AUTOSAR XML (schema 4-2-2)
standard types defined: UINT8, UINT16, UINT32
package /ECUSystem/CCU/CCUC/CCUCCfg
  ecu instance CCUCCfg: associated-com-i-pdu-group=[TxMPG_PTCANFDConnector_Ctrl, RxMPG_PTCANFDConnector_Ctrl], com-configuration-gw-time-base=0.005, com-configuration-rx-time-base=0.005, com-configuration-tx-time-base=0.005, sleep-mode-supported=true, wake-up-over-bus-supported=true
    can communication controller PTCANFDConnector_Ctrl: wake-up-by-controller-supported=true
    can communication connector PTCANFDConnector: comm-controller=PTCANFDConnector_Ctrl
package /ECUExtractCCU/VehicleProject
  system system: category=ECU_EXTRACT, ecu-extract-version=0.0.0;25/09/22, ECU.Cfg.Ver: 0, system-version=0.0.0;25/09/22, System.Ver: 0
    system mapping SystemMapping
      data-mappings:
        data-element=CCU_CSWC_proto.RootSwCompositionPrototype.CDU_ActiveWakeupBit.CDU_ActiveWakeupBit, system-signal=CDU_ActiveWakeupBit
        data-element=CCU_CSWC_proto.RootSwCompositionPrototype.CDU_APS_PortA_Currt{1..3}.CDU_APS_PortA_Currt{1..3}, system-signal=CDU_APS_PortA_Currt{1..3}
        data-element=CCU_CSWC_proto.RootSwCompositionPrototype.CDU_APS_PortA_U1.CDU_APS_PortA_U1, system-signal=CDU_APS_PortA_U1
        data-element=CCU_CSWC_proto.RootSwCompositionPrototype.CDU_APS_PortA_U2.CDU_APS_PortA_U2, system-signal=CDU_APS_PortA_U2
        data-element=CCU_CSWC_proto.RootSwCompositionPrototype.CDU_APS_PortB_Currt_DCDC.CDU_APS_PortB_Currt_DCDC, system-signal=CDU_APS_PortB_Currt_DCDC
        data-element=CCU_CSWC_proto.RootSwCompositionPrototype.CDU_APS_PortB_Currt_Sfty.CDU_APS_PortB_Currt_Sfty, system-signal=CDU_APS_PortB_Currt_Sfty
        data-element=CCU_CSWC_proto.RootSwCompositionPrototype.CDU_APS_PortB_U1.CDU_APS_PortB_U1, system-signal=CDU_APS_PortB_U1
        data-element=CCU_CSWC_proto.RootSwCompositionPrototype.CDU_APS_PortB_U2.CDU_APS_PortB_U2, system-signal=CDU_APS_PortB_U2
        data-element=CCU_CSWC_proto.RootSwCompositionPrototype.CDU_APS_SIGN.CDU_APS_SIGN, system-signal=CDU_APS_SIGN
        data-element=CCU_CSWC_proto.RootSwCompositionPrototype.CDU_DCDC_Checksum.CDU_DCDC_Checksum, system-signal=CDU_DCDC_Checksum
        data-element=CCU_CSWC_proto.RootSwCompositionPrototype.CDU_DCDC_Counter.CDU_DCDC_Counter, system-signal=CDU_DCDC_Counter
        data-element=CCU_CSWC_proto.RootSwCompositionPrototype.CDU_DetailedFltInfo.CDU_DetailedFltInfo, system-signal=CDU_DetailedFltInfo
        data-element=CCU_CSWC_proto.RootSwCompositionPrototype.CDU_FaultNum1.CDU_FaultNum1, system-signal=CDU_FaultNum1
        data-element=CCU_CSWC_proto.RootSwCompositionPrototype.CDU_FaultNum{10..19}.CDU_FaultNum{10..19}, system-signal=CDU_FaultNum{10..19}
        data-element=CCU_CSWC_proto.RootSwCompositionPrototype.CDU_FaultNum2.CDU_FaultNum2, system-signal=CDU_FaultNum2
        data-element=CCU_CSWC_proto.RootSwCompositionPrototype.CDU_FaultNum20.CDU_FaultNum20, system-signal=CDU_FaultNum20
        data-element=CCU_CSWC_proto.RootSwCompositionPrototype.CDU_FaultNum{3..9}.CDU_FaultNum{3..9}, system-signal=CDU_FaultNum{3..9}
        data-element=CCU_CSWC_proto.RootSwCompositionPrototype.CDU_FirstWakeupReason.CDU_FirstWakeupReason, system-signal=CDU_FirstWakeupReason
        data-element=CCU_CSWC_proto.RootSwCompositionPrototype.CDU_FrameIndex.CDU_FrameIndex, system-signal=CDU_FrameIndex
        data-element=CCU_CSWC_proto.RootSwCompositionPrototype.CDU_HwVersion.CDU_HwVersion, system-signal=CDU_HwVersion
        data-element=CCU_CSWC_proto.RootSwCompositionPrototype.CDU_KL15_Volt.CDU_KL15_Volt, system-signal=CDU_KL15_Volt
        data-element=CCU_CSWC_proto.RootSwCompositionPrototype.CDU_KL30_Volt.CDU_KL30_Volt, system-signal=CDU_KL30_Volt
        data-element=CCU_CSWC_proto.RootSwCompositionPrototype.CDU_NMReq_ACDchaChrgr.CDU_NMReq_ACDchaChrgr, system-signal=CDU_NMReq_ACDchaChrgr
        data-element=CCU_CSWC_proto.RootSwCompositionPrototype.CDU_NMReq_Diag.CDU_NMReq_Diag, system-signal=CDU_NMReq_Diag
        data-element=CCU_CSWC_proto.RootSwCompositionPrototype.CDU_NMReq_NM.CDU_NMReq_NM, system-signal=CDU_NMReq_NM
        data-element=CCU_CSWC_proto.RootSwCompositionPrototype.CDU_NMReq_Poweron.CDU_NMReq_Poweron, system-signal=CDU_NMReq_Poweron
        data-element=CCU_CSWC_proto.RootSwCompositionPrototype.CDU_OBC_1_Checksum.CDU_OBC_1_Checksum, system-signal=CDU_OBC_1_Checksum
        data-element=CCU_CSWC_proto.RootSwCompositionPrototype.CDU_OBC_1_Counter.CDU_OBC_1_Counter, system-signal=CDU_OBC_1_Counter
        data-element=CCU_CSWC_proto.RootSwCompositionPrototype.CDU_RepeatMessageRequestBit.CDU_RepeatMessageRequestBit, system-signal=CDU_RepeatMessageRequestBit
        data-element=CCU_CSWC_proto.RootSwCompositionPrototype.CDU_RepeatSts.CDU_RepeatSts, system-signal=CDU_RepeatSts
        data-element=CCU_CSWC_proto.RootSwCompositionPrototype.CDU_SourceNodeIdentifier.CDU_SourceNodeIdentifier, system-signal=CDU_SourceNodeIdentifier
        data-element=CCU_CSWC_proto.RootSwCompositionPrototype.CDU_SupplierCode.CDU_SupplierCode, system-signal=CDU_SupplierCode
        data-element=CCU_CSWC_proto.RootSwCompositionPrototype.CDU_SupplierNum.CDU_SupplierNum, system-signal=CDU_SupplierNum
        data-element=CCU_CSWC_proto.RootSwCompositionPrototype.CDU_SwMajorVersion.CDU_SwMajorVersion, system-signal=CDU_SwMajorVersion
        data-element=CCU_CSWC_proto.RootSwCompositionPrototype.CDU_SwMinorVersion.CDU_SwMinorVersion, system-signal=CDU_SwMinorVersion
        data-element=CCU_CSWC_proto.RootSwCompositionPrototype.CDU_SwPatchVersion.CDU_SwPatchVersion, system-signal=CDU_SwPatchVersion
        data-element=CCU_CSWC_proto.RootSwCompositionPrototype.CDU_SwVersionDay.CDU_SwVersionDay, system-signal=CDU_SwVersionDay
        data-element=CCU_CSWC_proto.RootSwCompositionPrototype.CDU_SwVersionMonth.CDU_SwVersionMonth, system-signal=CDU_SwVersionMonth
        data-element=CCU_CSWC_proto.RootSwCompositionPrototype.CDU_SwVersionYear.CDU_SwVersionYear, system-signal=CDU_SwVersionYear
        data-element=CCU_CSWC_proto.RootSwCompositionPrototype.CDU_TotalFaultNum.CDU_TotalFaultNum, system-signal=CDU_TotalFaultNum
        data-element=CCU_CSWC_proto.RootSwCompositionPrototype.DCDC_AlerSt.DCDC_AlerSt, system-signal=DCDC_AlerSt
        data-element=CCU_CSWC_proto.RootSwCompositionPrototype.DCDC_CopntTemp.DCDC_CopntTemp, system-signal=DCDC_CopntTemp
        data-element=CCU_CSWC_proto.RootSwCompositionPrototype.DCDC_DcInterLockVolt.DCDC_DcInterLockVolt, system-signal=DCDC_DcInterLockVolt
        data-element=CCU_CSWC_proto.RootSwCompositionPrototype.DCDC_DeratFlag.DCDC_DeratFlag, system-signal=DCDC_DeratFlag
        data-element=CCU_CSWC_proto.RootSwCompositionPrototype.DCDC_DeratReason1.DCDC_DeratReason1, system-signal=DCDC_DeratReason1
        data-element=CCU_CSWC_proto.RootSwCompositionPrototype.DCDC_DeratReason{10..12}.DCDC_DeratReason{10..12}, system-signal=DCDC_DeratReason{10..12}
        data-element=CCU_CSWC_proto.RootSwCompositionPrototype.DCDC_DeratReason{2..9}.DCDC_DeratReason{2..9}, system-signal=DCDC_DeratReason{2..9}
        data-element=CCU_CSWC_proto.RootSwCompositionPrototype.DCDC_EnergyConvrtDir.DCDC_EnergyConvrtDir, system-signal=DCDC_EnergyConvrtDir
        data-element=CCU_CSWC_proto.RootSwCompositionPrototype.DCDC_FaultLevel.DCDC_FaultLevel, system-signal=DCDC_FaultLevel
        data-element=CCU_CSWC_proto.RootSwCompositionPrototype.DCDC_FaultLightReq.DCDC_FaultLightReq, system-signal=DCDC_FaultLightReq
        data-element=CCU_CSWC_proto.RootSwCompositionPrototype.DCDC_FlowReq.DCDC_FlowReq, system-signal=DCDC_FlowReq
        data-element=CCU_CSWC_proto.RootSwCompositionPrototype.DCDC_HVIL_48VDCDC_St.DCDC_HVIL_48VDCDC_St, system-signal=DCDC_HVIL_48VDCDC_St
        data-element=CCU_CSWC_proto.RootSwCompositionPrototype.DCDC_HVIL_Batt_St.DCDC_HVIL_Batt_St, system-signal=DCDC_HVIL_Batt_St
        data-element=CCU_CSWC_proto.RootSwCompositionPrototype.DCDC_HVIL_EAS_St.DCDC_HVIL_EAS_St, system-signal=DCDC_HVIL_EAS_St
        data-element=CCU_CSWC_proto.RootSwCompositionPrototype.DCDC_HVIL_MCU_St.DCDC_HVIL_MCU_St, system-signal=DCDC_HVIL_MCU_St
        data-element=CCU_CSWC_proto.RootSwCompositionPrototype.DCDC_HVIL_PTC_St.DCDC_HVIL_PTC_St, system-signal=DCDC_HVIL_PTC_St
        data-element=CCU_CSWC_proto.RootSwCompositionPrototype.DCDC_HVIL_PTCR_St.DCDC_HVIL_PTCR_St, system-signal=DCDC_HVIL_PTCR_St
        data-element=CCU_CSWC_proto.RootSwCompositionPrototype.DCDC_InpWtrTemp.DCDC_InpWtrTemp, system-signal=DCDC_InpWtrTemp
        data-element=CCU_CSWC_proto.RootSwCompositionPrototype.DCDC_IptCurrt.DCDC_IptCurrt, system-signal=DCDC_IptCurrt
        data-element=CCU_CSWC_proto.RootSwCompositionPrototype.DCDC_IptVolt.DCDC_IptVolt, system-signal=DCDC_IptVolt
        data-element=CCU_CSWC_proto.RootSwCompositionPrototype.DCDC_LoopOut.DCDC_LoopOut, system-signal=DCDC_LoopOut
        data-element=CCU_CSWC_proto.RootSwCompositionPrototype.DCDC_LvSidePwr.DCDC_LvSidePwr, system-signal=DCDC_LvSidePwr
        data-element=CCU_CSWC_proto.RootSwCompositionPrototype.DCDC_MaxOptPwr.DCDC_MaxOptPwr, system-signal=DCDC_MaxOptPwr
        data-element=CCU_CSWC_proto.RootSwCompositionPrototype.DCDC_McuInterLockVolt.DCDC_McuInterLockVolt, system-signal=DCDC_McuInterLockVolt
        data-element=CCU_CSWC_proto.RootSwCompositionPrototype.DCDC_NoLoadCurrtFlag.DCDC_NoLoadCurrtFlag, system-signal=DCDC_NoLoadCurrtFlag
        data-element=CCU_CSWC_proto.RootSwCompositionPrototype.DCDC_OperSt.DCDC_OperSt, system-signal=DCDC_OperSt
        data-element=CCU_CSWC_proto.RootSwCompositionPrototype.DCDC_OptCurrt.DCDC_OptCurrt, system-signal=DCDC_OptCurrt
        data-element=CCU_CSWC_proto.RootSwCompositionPrototype.DCDC_OptVolt.DCDC_OptVolt, system-signal=DCDC_OptVolt
        data-element=CCU_CSWC_proto.RootSwCompositionPrototype.DCDC_Oring_APS_Temp.DCDC_Oring_APS_Temp, system-signal=DCDC_Oring_APS_Temp
        data-element=CCU_CSWC_proto.RootSwCompositionPrototype.DCDC_OutWtrTemp.DCDC_OutWtrTemp, system-signal=DCDC_OutWtrTemp
        data-element=CCU_CSWC_proto.RootSwCompositionPrototype.DCDC_OverTemp.DCDC_OverTemp, system-signal=DCDC_OverTemp
        data-element=CCU_CSWC_proto.RootSwCompositionPrototype.DCDC_PeakPwrTi.DCDC_PeakPwrTi, system-signal=DCDC_PeakPwrTi
        data-element=CCU_CSWC_proto.RootSwCompositionPrototype.DCDC_PNGSt.DCDC_PNGSt, system-signal=DCDC_PNGSt
        data-element=CCU_CSWC_proto.RootSwCompositionPrototype.DCDC_PtcInterLockVolt.DCDC_PtcInterLockVolt, system-signal=DCDC_PtcInterLockVolt
        data-element=CCU_CSWC_proto.RootSwCompositionPrototype.DCDC_SwMajorVersion.DCDC_SwMajorVersion, system-signal=DCDC_SwMajorVersion
        data-element=CCU_CSWC_proto.RootSwCompositionPrototype.DCDC_SwMinorVersion.DCDC_SwMinorVersion, system-signal=DCDC_SwMinorVersion
        data-element=CCU_CSWC_proto.RootSwCompositionPrototype.DCDC_SwPatchVersion.DCDC_SwPatchVersion, system-signal=DCDC_SwPatchVersion
        data-element=CCU_CSWC_proto.RootSwCompositionPrototype.DCDC_SwVersionDay.DCDC_SwVersionDay, system-signal=DCDC_SwVersionDay
        data-element=CCU_CSWC_proto.RootSwCompositionPrototype.DCDC_SwVersionMonth.DCDC_SwVersionMonth, system-signal=DCDC_SwVersionMonth
        data-element=CCU_CSWC_proto.RootSwCompositionPrototype.DCDC_SwVersionYear.DCDC_SwVersionYear, system-signal=DCDC_SwVersionYear
        data-element=CCU_CSWC_proto.RootSwCompositionPrototype.OBC_ACInpFrq.OBC_ACInpFrq, system-signal=OBC_ACInpFrq
        data-element=CCU_CSWC_proto.RootSwCompositionPrototype.OBC_AcIptSts.OBC_AcIptSts, system-signal=OBC_AcIptSts
        data-element=CCU_CSWC_proto.RootSwCompositionPrototype.OBC_AcIptType.OBC_AcIptType, system-signal=OBC_AcIptType
        data-element=CCU_CSWC_proto.RootSwCompositionPrototype.OBC_ACL1Currt.OBC_ACL1Currt, system-signal=OBC_ACL1Currt
        data-element=CCU_CSWC_proto.RootSwCompositionPrototype.OBC_ACL1Volt.OBC_ACL1Volt, system-signal=OBC_ACL1Volt
        data-element=CCU_CSWC_proto.RootSwCompositionPrototype.OBC_ACL2Currt.OBC_ACL2Currt, system-signal=OBC_ACL2Currt
        data-element=CCU_CSWC_proto.RootSwCompositionPrototype.OBC_ACL2Volt.OBC_ACL2Volt, system-signal=OBC_ACL2Volt
        data-element=CCU_CSWC_proto.RootSwCompositionPrototype.OBC_ACL3Currt.OBC_ACL3Currt, system-signal=OBC_ACL3Currt
        data-element=CCU_CSWC_proto.RootSwCompositionPrototype.OBC_ACL3Volt.OBC_ACL3Volt, system-signal=OBC_ACL3Volt
        data-element=CCU_CSWC_proto.RootSwCompositionPrototype.OBC_AcLineImpedance.OBC_AcLineImpedance, system-signal=OBC_AcLineImpedance
        data-element=CCU_CSWC_proto.RootSwCompositionPrototype.OBC_ACPileMaxCurrt.OBC_ACPileMaxCurrt, system-signal=OBC_ACPileMaxCurrt
        data-element=CCU_CSWC_proto.RootSwCompositionPrototype.OBC_ACPwr.OBC_ACPwr, system-signal=OBC_ACPwr
        data-element=CCU_CSWC_proto.RootSwCompositionPrototype.OBC_BusCapacity.OBC_BusCapacity, system-signal=OBC_BusCapacity
        data-element=CCU_CSWC_proto.RootSwCompositionPrototype.OBC_CCRes.OBC_CCRes, system-signal=OBC_CCRes
        data-element=CCU_CSWC_proto.RootSwCompositionPrototype.OBC_ChrgCablePermitCurrt.OBC_ChrgCablePermitCurrt, system-signal=OBC_ChrgCablePermitCurrt
        data-element=CCU_CSWC_proto.RootSwCompositionPrototype.OBC_ChrgDischrgStep.OBC_ChrgDischrgStep, system-signal=OBC_ChrgDischrgStep
        data-element=CCU_CSWC_proto.RootSwCompositionPrototype.OBC_ChrgEndNum.OBC_ChrgEndNum, system-signal=OBC_ChrgEndNum
        data-element=CCU_CSWC_proto.RootSwCompositionPrototype.OBC_ChrgGunCCSts.OBC_ChrgGunCCSts, system-signal=OBC_ChrgGunCCSts
        data-element=CCU_CSWC_proto.RootSwCompositionPrototype.OBC_ChrgOptMaxCurrt.OBC_ChrgOptMaxCurrt, system-signal=OBC_ChrgOptMaxCurrt
        data-element=CCU_CSWC_proto.RootSwCompositionPrototype.OBC_ChrgOptMaxPwr.OBC_ChrgOptMaxPwr, system-signal=OBC_ChrgOptMaxPwr
        data-element=CCU_CSWC_proto.RootSwCompositionPrototype.OBC_ChrgOptMaxVolt.OBC_ChrgOptMaxVolt, system-signal=OBC_ChrgOptMaxVolt
        data-element=CCU_CSWC_proto.RootSwCompositionPrototype.OBC_ChrgOptMinVolt.OBC_ChrgOptMinVolt, system-signal=OBC_ChrgOptMinVolt
        data-element=CCU_CSWC_proto.RootSwCompositionPrototype.OBC_CopntTemp.OBC_CopntTemp, system-signal=OBC_CopntTemp
        data-element=CCU_CSWC_proto.RootSwCompositionPrototype.OBC_CPDuty.OBC_CPDuty, system-signal=OBC_CPDuty
        data-element=CCU_CSWC_proto.RootSwCompositionPrototype.OBC_CPFreqSts.OBC_CPFreqSts, system-signal=OBC_CPFreqSts
        data-element=CCU_CSWC_proto.RootSwCompositionPrototype.OBC_CPFrq.OBC_CPFrq, system-signal=OBC_CPFrq
        data-element=CCU_CSWC_proto.RootSwCompositionPrototype.OBC_CPOutpDuty.OBC_CPOutpDuty, system-signal=OBC_CPOutpDuty
        data-element=CCU_CSWC_proto.RootSwCompositionPrototype.OBC_CPOutpVolt.OBC_CPOutpVolt, system-signal=OBC_CPOutpVolt
        data-element=CCU_CSWC_proto.RootSwCompositionPrototype.OBC_CPSts.OBC_CPSts, system-signal=OBC_CPSts
        data-element=CCU_CSWC_proto.RootSwCompositionPrototype.OBC_CPValidSt.OBC_CPValidSt, system-signal=OBC_CPValidSt
        data-element=CCU_CSWC_proto.RootSwCompositionPrototype.OBC_CPVolt.OBC_CPVolt, system-signal=OBC_CPVolt
        data-element=CCU_CSWC_proto.RootSwCompositionPrototype.OBC_DCChrgMod_LimCurrt.OBC_DCChrgMod_LimCurrt, system-signal=OBC_DCChrgMod_LimCurrt
        data-element=CCU_CSWC_proto.RootSwCompositionPrototype.OBC_DCCurrt.OBC_DCCurrt, system-signal=OBC_DCCurrt
        data-element=CCU_CSWC_proto.RootSwCompositionPrototype.OBC_DchaEndNum.OBC_DchaEndNum, system-signal=OBC_DchaEndNum
        data-element=CCU_CSWC_proto.RootSwCompositionPrototype.OBC_DCVolt.OBC_DCVolt, system-signal=OBC_DCVolt
        data-element=CCU_CSWC_proto.RootSwCompositionPrototype.OBC_DeratFlag.OBC_DeratFlag, system-signal=OBC_DeratFlag
        data-element=CCU_CSWC_proto.RootSwCompositionPrototype.OBC_DeratReason1.OBC_DeratReason1, system-signal=OBC_DeratReason1
        data-element=CCU_CSWC_proto.RootSwCompositionPrototype.OBC_DeratReason{10..19}.OBC_DeratReason{10..19}, system-signal=OBC_DeratReason{10..19}
        data-element=CCU_CSWC_proto.RootSwCompositionPrototype.OBC_DeratReason2.OBC_DeratReason2, system-signal=OBC_DeratReason2
        data-element=CCU_CSWC_proto.RootSwCompositionPrototype.OBC_DeratReason{20..24}.OBC_DeratReason{20..24}, system-signal=OBC_DeratReason{20..24}
        data-element=CCU_CSWC_proto.RootSwCompositionPrototype.OBC_DeratReason{3..9}.OBC_DeratReason{3..9}, system-signal=OBC_DeratReason{3..9}
        data-element=CCU_CSWC_proto.RootSwCompositionPrototype.OBC_DischrgLoadForm.OBC_DischrgLoadForm, system-signal=OBC_DischrgLoadForm
        data-element=CCU_CSWC_proto.RootSwCompositionPrototype.OBC_DischrgOptMaxPwr.OBC_DischrgOptMaxPwr, system-signal=OBC_DischrgOptMaxPwr
        data-element=CCU_CSWC_proto.RootSwCompositionPrototype.OBC_DisWorkMode.OBC_DisWorkMode, system-signal=OBC_DisWorkMode
        data-element=CCU_CSWC_proto.RootSwCompositionPrototype.OBC_EnergyConvrtDir.OBC_EnergyConvrtDir, system-signal=OBC_EnergyConvrtDir
        data-element=CCU_CSWC_proto.RootSwCompositionPrototype.OBC_FastChargeRelayNegSts.OBC_FastChargeRelayNegSts, system-signal=OBC_FastChargeRelayNegSts
        data-element=CCU_CSWC_proto.RootSwCompositionPrototype.OBC_FastChargeRelayPosSts.OBC_FastChargeRelayPosSts, system-signal=OBC_FastChargeRelayPosSts
        data-element=CCU_CSWC_proto.RootSwCompositionPrototype.OBC_FastChrgRelayNeg_Extd_U.OBC_FastChrgRelayNeg_Extd_U, system-signal=OBC_FastChrgRelayNeg_Extd_U
        data-element=CCU_CSWC_proto.RootSwCompositionPrototype.OBC_FastChrgRelayPos_Extd_U.OBC_FastChrgRelayPos_Extd_U, system-signal=OBC_FastChrgRelayPos_Extd_U
        data-element=CCU_CSWC_proto.RootSwCompositionPrototype.OBC_FaultLevel.OBC_FaultLevel, system-signal=OBC_FaultLevel
        data-element=CCU_CSWC_proto.RootSwCompositionPrototype.OBC_FaultLightReq.OBC_FaultLightReq, system-signal=OBC_FaultLightReq
        data-element=CCU_CSWC_proto.RootSwCompositionPrototype.OBC_HVIL_AC_St.OBC_HVIL_AC_St, system-signal=OBC_HVIL_AC_St
        data-element=CCU_CSWC_proto.RootSwCompositionPrototype.OBC_HVIL_DC_St.OBC_HVIL_DC_St, system-signal=OBC_HVIL_DC_St
        data-element=CCU_CSWC_proto.RootSwCompositionPrototype.OBC_InsulationR.OBC_InsulationR, system-signal=OBC_InsulationR
        data-element=CCU_CSWC_proto.RootSwCompositionPrototype.OBC_Ithd.OBC_Ithd, system-signal=OBC_Ithd
        data-element=CCU_CSWC_proto.RootSwCompositionPrototype.OBC_OperSt.OBC_OperSt, system-signal=OBC_OperSt
        data-element=CCU_CSWC_proto.RootSwCompositionPrototype.OBC_RatedPwrLevel.OBC_RatedPwrLevel, system-signal=OBC_RatedPwrLevel
        data-element=CCU_CSWC_proto.RootSwCompositionPrototype.OBC_RBCurrt.OBC_RBCurrt, system-signal=OBC_RBCurrt
        data-element=CCU_CSWC_proto.RootSwCompositionPrototype.OBC_RBMainK{1..4}Sts.OBC_RBMainK{1..4}Sts, system-signal=OBC_RBMainK{1..4}Sts
        data-element=CCU_CSWC_proto.RootSwCompositionPrototype.OBC_S1Sts.OBC_S1Sts, system-signal=OBC_S1Sts
        data-element=CCU_CSWC_proto.RootSwCompositionPrototype.OBC_S2Sts.OBC_S2Sts, system-signal=OBC_S2Sts
        data-element=CCU_CSWC_proto.RootSwCompositionPrototype.OBC_S4Sts.OBC_S4Sts, system-signal=OBC_S4Sts
        data-element=CCU_CSWC_proto.RootSwCompositionPrototype.OBC_SwMajorVersion.OBC_SwMajorVersion, system-signal=OBC_SwMajorVersion
        data-element=CCU_CSWC_proto.RootSwCompositionPrototype.OBC_SwMinorVersion.OBC_SwMinorVersion, system-signal=OBC_SwMinorVersion
        data-element=CCU_CSWC_proto.RootSwCompositionPrototype.OBC_SwPatchVersion.OBC_SwPatchVersion, system-signal=OBC_SwPatchVersion
        data-element=CCU_CSWC_proto.RootSwCompositionPrototype.OBC_SwVersionDay.OBC_SwVersionDay, system-signal=OBC_SwVersionDay
        data-element=CCU_CSWC_proto.RootSwCompositionPrototype.OBC_SwVersionMonth.OBC_SwVersionMonth, system-signal=OBC_SwVersionMonth
        data-element=CCU_CSWC_proto.RootSwCompositionPrototype.OBC_SwVersionYear.OBC_SwVersionYear, system-signal=OBC_SwVersionYear
        data-element=CCU_CSWC_proto.RootSwCompositionPrototype.OBC_Uthd.OBC_Uthd, system-signal=OBC_Uthd
        data-element=CCU_CSWC_proto.RootSwCompositionPrototype.OBC_WorkMode.OBC_WorkMode, system-signal=OBC_WorkMode
        data-element=CCU_CSWC_proto.RootSwCompositionPrototype.BMS_ActvHvOnReq.BMS_ActvHvOnReq, system-signal=BMS_ActvHvOnReq
        data-element=CCU_CSWC_proto.RootSwCompositionPrototype.BMS_BattVolt_U7.BMS_BattVolt_U7, system-signal=BMS_BattVolt_U7
        data-element=CCU_CSWC_proto.RootSwCompositionPrototype.BMS_ChargeInfo_Checksum.BMS_ChargeInfo_Checksum, system-signal=BMS_ChargeInfo_Checksum
        data-element=CCU_CSWC_proto.RootSwCompositionPrototype.BMS_ChargeInfo_Counter.BMS_ChargeInfo_Counter, system-signal=BMS_ChargeInfo_Counter
        data-element=CCU_CSWC_proto.RootSwCompositionPrototype.BMS_DCChrgConnectSt.BMS_DCChrgConnectSt, system-signal=BMS_DCChrgConnectSt
        data-element=CCU_CSWC_proto.RootSwCompositionPrototype.BMS_MainNegSt.BMS_MainNegSt, system-signal=BMS_MainNegSt
        data-element=CCU_CSWC_proto.RootSwCompositionPrototype.BMS_MainPosSt.BMS_MainPosSt, system-signal=BMS_MainPosSt
        data-element=CCU_CSWC_proto.RootSwCompositionPrototype.BMS_MainPreChrgSt.BMS_MainPreChrgSt, system-signal=BMS_MainPreChrgSt
        data-element=CCU_CSWC_proto.RootSwCompositionPrototype.BMS_Measure_Checksum.BMS_Measure_Checksum, system-signal=BMS_Measure_Checksum
        data-element=CCU_CSWC_proto.RootSwCompositionPrototype.BMS_Measure_Counter.BMS_Measure_Counter, system-signal=BMS_Measure_Counter
        data-element=CCU_CSWC_proto.RootSwCompositionPrototype.BMS_OBCCurrtReq.BMS_OBCCurrtReq, system-signal=BMS_OBCCurrtReq
        data-element=CCU_CSWC_proto.RootSwCompositionPrototype.BMS_OBCInvACVoltReq.BMS_OBCInvACVoltReq, system-signal=BMS_OBCInvACVoltReq
        data-element=CCU_CSWC_proto.RootSwCompositionPrototype.BMS_OBCInvMaxPermPwr.BMS_OBCInvMaxPermPwr, system-signal=BMS_OBCInvMaxPermPwr
        data-element=CCU_CSWC_proto.RootSwCompositionPrototype.BMS_OBCVoltReq.BMS_OBCVoltReq, system-signal=BMS_OBCVoltReq
        data-element=CCU_CSWC_proto.RootSwCompositionPrototype.BMS_OBCWorkModReq.BMS_OBCWorkModReq, system-signal=BMS_OBCWorkModReq
        data-element=CCU_CSWC_proto.RootSwCompositionPrototype.BMS_OperSt.BMS_OperSt, system-signal=BMS_OperSt
        data-element=CCU_CSWC_proto.RootSwCompositionPrototype.IPB_VehicleSpeed.IPB_VehicleSpeed, system-signal=IPB_VehicleSpeed
        data-element=CCU_CSWC_proto.RootSwCompositionPrototype.IPB_VehicleSpeedValid.IPB_VehicleSpeedValid, system-signal=IPB_VehicleSpeedValid
        data-element=CCU_CSWC_proto.RootSwCompositionPrototype.TBOX_DSTFlag.TBOX_DSTFlag, system-signal=TBOX_DSTFlag
        data-element=CCU_CSWC_proto.RootSwCompositionPrototype.TBOX_TimeDay.TBOX_TimeDay, system-signal=TBOX_TimeDay
        data-element=CCU_CSWC_proto.RootSwCompositionPrototype.TBOX_TimeFlag.TBOX_TimeFlag, system-signal=TBOX_TimeFlag
        data-element=CCU_CSWC_proto.RootSwCompositionPrototype.TBOX_TimeHour.TBOX_TimeHour, system-signal=TBOX_TimeHour
        data-element=CCU_CSWC_proto.RootSwCompositionPrototype.TBOX_TimeMinute.TBOX_TimeMinute, system-signal=TBOX_TimeMinute
        data-element=CCU_CSWC_proto.RootSwCompositionPrototype.TBOX_TimeMonth.TBOX_TimeMonth, system-signal=TBOX_TimeMonth
        data-element=CCU_CSWC_proto.RootSwCompositionPrototype.TBOX_TimeSecond.TBOX_TimeSecond, system-signal=TBOX_TimeSecond
        data-element=CCU_CSWC_proto.RootSwCompositionPrototype.TBOX_TimeYear.TBOX_TimeYear, system-signal=TBOX_TimeYear
        data-element=CCU_CSWC_proto.RootSwCompositionPrototype.TBOX_TimeZone.TBOX_TimeZone, system-signal=TBOX_TimeZone
        data-element=CCU_CSWC_proto.RootSwCompositionPrototype.TBOX_TimeZoneMinute.TBOX_TimeZoneMinute, system-signal=TBOX_TimeZoneMinute
        data-element=CCU_CSWC_proto.RootSwCompositionPrototype.TBOX_TimeZoneNum.TBOX_TimeZoneNum, system-signal=TBOX_TimeZoneNum
        data-element=CCU_CSWC_proto.RootSwCompositionPrototype.VDC_ActGearSt.VDC_ActGearSt, system-signal=VDC_ActGearSt
        data-element=CCU_CSWC_proto.RootSwCompositionPrototype.VDC_BMSDchaMaxPwr.VDC_BMSDchaMaxPwr, system-signal=VDC_BMSDchaMaxPwr
        data-element=CCU_CSWC_proto.RootSwCompositionPrototype.VDC_DCDCEnableCmd.VDC_DCDCEnableCmd, system-signal=VDC_DCDCEnableCmd
        data-element=CCU_CSWC_proto.RootSwCompositionPrototype.VDC_DCDCMaxCurrtAlld.VDC_DCDCMaxCurrtAlld, system-signal=VDC_DCDCMaxCurrtAlld
        data-element=CCU_CSWC_proto.RootSwCompositionPrototype.VDC_DCDCSetVolt.VDC_DCDCSetVolt, system-signal=VDC_DCDCSetVolt
        data-element=CCU_CSWC_proto.RootSwCompositionPrototype.VDC_HVCtrl_Checksum.VDC_HVCtrl_Checksum, system-signal=VDC_HVCtrl_Checksum
        data-element=CCU_CSWC_proto.RootSwCompositionPrototype.VDC_HVCtrl_Counter.VDC_HVCtrl_Counter, system-signal=VDC_HVCtrl_Counter
        data-element=CCU_CSWC_proto.RootSwCompositionPrototype.VDC_OBCACCurrtMaxPerm.VDC_OBCACCurrtMaxPerm, system-signal=VDC_OBCACCurrtMaxPerm
        data-element=CCU_CSWC_proto.RootSwCompositionPrototype.VDC_RBAllwdSts.VDC_RBAllwdSts, system-signal=VDC_RBAllwdSts
        data-element=CCU_CSWC_proto.RootSwCompositionPrototype.VDC_RBDCACVoltReq.VDC_RBDCACVoltReq, system-signal=VDC_RBDCACVoltReq
        data-element=CCU_CSWC_proto.RootSwCompositionPrototype.VDC_RBEnableSt.VDC_RBEnableSt, system-signal=VDC_RBEnableSt
        data-element=CCU_CSWC_proto.RootSwCompositionPrototype.VDC_RBMainK1K2Ctrl.VDC_RBMainK1K2Ctrl, system-signal=VDC_RBMainK1K2Ctrl
        data-element=CCU_CSWC_proto.RootSwCompositionPrototype.VDC_RBMainK3K4Ctrl.VDC_RBMainK3K4Ctrl, system-signal=VDC_RBMainK3K4Ctrl
        data-element=CCU_CSWC_proto.RootSwCompositionPrototype.VDC_RBOBCWorkModReq.VDC_RBOBCWorkModReq, system-signal=VDC_RBOBCWorkModReq
        data-element=CCU_CSWC_proto.RootSwCompositionPrototype.VDC_SysState_Checksum.VDC_SysState_Checksum, system-signal=VDC_SysState_Checksum
        data-element=CCU_CSWC_proto.RootSwCompositionPrototype.VDC_SysState_Counter.VDC_SysState_Counter, system-signal=VDC_SysState_Counter
        data-element=CCU_CSWC_proto.RootSwCompositionPrototype.VDC_TotalRang_VV01.VDC_TotalRang_VV01, system-signal=VDC_TotalRang_VV01
        data-element=CCU_CSWC_proto.RootSwCompositionPrototype.VDC_VehState_Checksum.VDC_VehState_Checksum, system-signal=VDC_VehState_Checksum
        data-element=CCU_CSWC_proto.RootSwCompositionPrototype.VDC_VehState_Counter.VDC_VehState_Counter, system-signal=VDC_VehState_Counter
        data-element=CCU_CSWC_proto.RootSwCompositionPrototype.VIU_CarMode.VIU_CarMode, system-signal=VIU_CarMode
        data-element=CCU_CSWC_proto.RootSwCompositionPrototype.VIU_Info_Checksum_VV01.VIU_Info_Checksum_VV01, system-signal=VIU_Info_Checksum_VV01
        data-element=CCU_CSWC_proto.RootSwCompositionPrototype.VIU_Info_Counter.VIU_Info_Counter, system-signal=VIU_Info_Counter
        data-element=CCU_CSWC_proto.RootSwCompositionPrototype.VIU_PowerMode.VIU_PowerMode, system-signal=VIU_PowerMode
        data-element=CCU_CSWC_proto.RootSwCompositionPrototype.VIU_Route_EP_Checksum.VIU_Route_EP_Checksum, system-signal=VIU_Route_EP_Checksum
        data-element=CCU_CSWC_proto.RootSwCompositionPrototype.VIU_Route_EP_Counter.VIU_Route_EP_Counter, system-signal=VIU_Route_EP_Counter
        data-element=CCU_CSWC_proto.RootSwCompositionPrototype.VIU_UsageMode.VIU_UsageMode, system-signal=VIU_UsageMode
      sw-mappings:
        swc to ecu mapping CCU: component=RootSwCompositionPrototype.CCU_CSWC_proto, ecu-instance=CCUCCfg
    root-software-compositions:
      root sw composition prototype RootSwCompositionPrototype: software-composition=RootComposition
package /VehicleTopology
  can cluster PTCANFD: baudrate=500000, protocol-name=CAN, protocol-version=CAN11, can-fd-baudrate=2000000
    can physical channel PhCnPTCANFD: comm-connectors=PTCANFDConnector
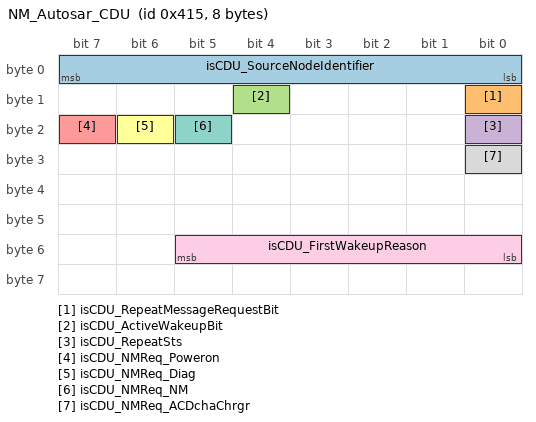
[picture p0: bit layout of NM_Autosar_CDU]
      frame NM_Autosar_CDU: id 0x415, from CCUCCfg, frame-length=8, can-addressing-mode=STANDARD, can-fd-frame-support=false, can-frame-tx-behavior=CAN-20
        nm pdu NM_Autosar_CDU: length=8, nm-vote-information=false, unused-bit-pattern=0
          signal isCDU_SourceNodeIdentifier: start 7, 8 bit, big-endian, data-type-policy=OVERRIDE, init-value=21, base-type=UINT8, compu {phys=raw for raw 0..255}, transfer-property=TRIGGERED  # 源节点ID
          signal isCDU_RepeatMessageRequestBit: start 8, 1 bit, big-endian, data-type-policy=OVERRIDE, init-value=0, base-type=UINT1, compu-method=CDU_RepeatMessageRequestBit, transfer-property=TRIGGERED  # 重复报文请求位
          signal isCDU_ActiveWakeupBit: start 12, 1 bit, big-endian, data-type-policy=OVERRIDE, init-value=0, base-type=UINT1, compu-method=CDU_ActiveWakeupBit, transfer-property=TRIGGERED  # 主动唤醒标志位
          signal isCDU_RepeatSts: start 16, 1 bit, big-endian, data-type-policy=OVERRIDE, init-value=0, base-type=UINT1, compu {0=CDU_RepeatSts_0_Not_in_the_RMS, 1=CDU_RepeatSts_1_Stay_in_the_RMS}, transfer-property=TRIGGERED  # 重复报文状态
          signal isCDU_NMReq_Poweron: start 23, 1 bit, big-endian, data-type-policy=OVERRIDE, init-value=0, base-type=UINT1, compu {0=CDU_NMReq_Poweron_0_Inactive, 1=CDU_NMReq_Poweron_1_Active}, transfer-property=TRIGGERED  # 因唤醒硬线ON请求网络
          signal isCDU_NMReq_Diag: start 22, 1 bit, big-endian, data-type-policy=OVERRIDE, init-value=0, base-type=UINT1, compu {0=CDU_NMReq_Diag_0_Inactive, 1=CDU_NMReq_Diag_1_Active}, transfer-property=TRIGGERED  # 因诊断请求网络
          signal isCDU_NMReq_NM: start 21, 1 bit, big-endian, data-type-policy=OVERRIDE, init-value=0, base-type=UINT1, compu {0=CDU_NMReq_NM_0_Inactive, 1=CDU_NMReq_NM_1_Active}, transfer-property=TRIGGERED  # 因被NM报文唤醒请求网络
          signal isCDU_NMReq_ACDchaChrgr: start 24, 1 bit, big-endian, data-type-policy=OVERRIDE, init-value=0, base-type=UINT1, compu {0=CDU_NMReq_ACDchaChrgr_0_Inactive, 1=CDU_NMReq_ACDchaChrgr_1_Active}, transfer-property=TRIGGERED  # 因交流充放电枪唤醒请求网络
          signal isCDU_FirstWakeupReason: start 53, 6 bit, big-endian, data-type-policy=OVERRIDE, init-value=0, base-type=UINT6, compu-method=CDU_FirstWakeupReason, transfer-property=TRIGGERED  # CDU首次唤醒原因
      frame CDU_Fault: id 0x51A, from CCUCCfg, frame-length=32, can-addressing-mode=STANDARD, can-fd-frame-support=true, can-frame-tx-behavior=CAN-FD
        pdu CDU_Fault: length=32, transmission-mode-condition{data-filter=data-filter-type=ALWAYS, i-signal-in-i-pdu=isCDU_TotalFaultNum_mtx}, transmission-mode-true-timing=cyclic-timing={time-offset=0.0, time-period=0.5}, unused-bit-pattern=0
          signal isCDU_FaultNum1: start 23, 12 bit, big-endian, data-type-policy=OVERRIDE, init-value=0, base-type=UINT12, compu {phys=raw for raw 0..4095}, transfer-property=PENDING  # 故障编号1
          signal isCDU_FaultNum10: start 123, 12 bit, big-endian, data-type-policy=OVERRIDE, init-value=0, base-type=UINT12, compu {phys=raw for raw 0..4095}, transfer-property=PENDING  # 故障编号10
          signal isCDU_FaultNum11: start 143, 12 bit, big-endian, data-type-policy=OVERRIDE, init-value=0, base-type=UINT12, compu {phys=raw for raw 0..4095}, transfer-property=PENDING  # 故障编号11
          signal isCDU_FaultNum12: start 147, 12 bit, big-endian, data-type-policy=OVERRIDE, init-value=0, base-type=UINT12, compu {phys=raw for raw 0..4095}, transfer-property=PENDING  # 故障编号12
          signal isCDU_FaultNum13: start 167, 12 bit, big-endian, data-type-policy=OVERRIDE, init-value=0, base-type=UINT12, compu {phys=raw for raw 0..4095}, transfer-property=PENDING  # 故障编号13
          signal isCDU_FaultNum14: start 171, 12 bit, big-endian, data-type-policy=OVERRIDE, init-value=0, base-type=UINT12, compu {phys=raw for raw 0..4095}, transfer-property=PENDING  # 故障编号14
          signal isCDU_FaultNum15: start 191, 12 bit, big-endian, data-type-policy=OVERRIDE, init-value=0, base-type=UINT12, compu {phys=raw for raw 0..4095}, transfer-property=PENDING  # 故障编号15
          signal isCDU_FaultNum16: start 195, 12 bit, big-endian, data-type-policy=OVERRIDE, init-value=0, base-type=UINT12, compu {phys=raw for raw 0..4095}, transfer-property=PENDING  # 故障编号16
          signal isCDU_FaultNum17: start 215, 12 bit, big-endian, data-type-policy=OVERRIDE, init-value=0, base-type=UINT12, compu {phys=raw for raw 0..4095}, transfer-property=PENDING  # 故障编号17
          signal isCDU_FaultNum18: start 219, 12 bit, big-endian, data-type-policy=OVERRIDE, init-value=0, base-type=UINT12, compu {phys=raw for raw 0..4095}, transfer-property=PENDING  # 故障编号18
          signal isCDU_FaultNum19: start 239, 12 bit, big-endian, data-type-policy=OVERRIDE, init-value=0, base-type=UINT12, compu {phys=raw for raw 0..4095}, transfer-property=PENDING  # 故障编号19
          signal isCDU_FaultNum2: start 27, 12 bit, big-endian, data-type-policy=OVERRIDE, init-value=0, base-type=UINT12, compu {phys=raw for raw 0..4095}, transfer-property=PENDING  # 故障编号2
          signal isCDU_FaultNum20: start 243, 12 bit, big-endian, data-type-policy=OVERRIDE, init-value=0, base-type=UINT12, compu {phys=raw for raw 0..4095}, transfer-property=PENDING  # 故障编号20
          signal isCDU_FaultNum3: start 47, 12 bit, big-endian, data-type-policy=OVERRIDE, init-value=0, base-type=UINT12, compu {phys=raw for raw 0..4095}, transfer-property=PENDING  # 故障编号3
          signal isCDU_FaultNum4: start 51, 12 bit, big-endian, data-type-policy=OVERRIDE, init-value=0, base-type=UINT12, compu {phys=raw for raw 0..4095}, transfer-property=PENDING  # 故障编号4
          signal isCDU_FaultNum5: start 71, 12 bit, big-endian, data-type-policy=OVERRIDE, init-value=0, base-type=UINT12, compu {phys=raw for raw 0..4095}, transfer-property=PENDING  # 故障编号5
          signal isCDU_FaultNum6: start 75, 12 bit, big-endian, data-type-policy=OVERRIDE, init-value=0, base-type=UINT12, compu {phys=raw for raw 0..4095}, transfer-property=PENDING  # 故障编号6
          signal isCDU_FaultNum7: start 95, 12 bit, big-endian, data-type-policy=OVERRIDE, init-value=0, base-type=UINT12, compu {phys=raw for raw 0..4095}, transfer-property=PENDING  # 故障编号7
          signal isCDU_FaultNum8: start 99, 12 bit, big-endian, data-type-policy=OVERRIDE, init-value=0, base-type=UINT12, compu {phys=raw for raw 0..4095}, transfer-property=PENDING  # 故障编号8
          signal isCDU_FaultNum9: start 119, 12 bit, big-endian, data-type-policy=OVERRIDE, init-value=0, base-type=UINT12, compu {phys=raw for raw 0..4095}, transfer-property=PENDING  # 故障编号9
          signal isCDU_FrameIndex: start 12, 5 bit, big-endian, data-type-policy=OVERRIDE, init-value=0, base-type=UINT5, compu {phys=raw for raw 0..31}, transfer-property=PENDING  # 帧序号
          signal isCDU_SupplierNum: start 15, 3 bit, big-endian, data-type-policy=OVERRIDE, init-value=0, base-type=UINT3, compu {phys=raw for raw 0..7}, transfer-property=PENDING  # 供应商代码
          signal isCDU_TotalFaultNum: start 7, 8 bit, big-endian, data-type-policy=OVERRIDE, init-value=0, base-type=UINT8, compu {phys=raw for raw 0..255}, transfer-property=PENDING  # 当前故障总数
      frame CDU_Version: id 0x5B4, from CCUCCfg, frame-length=32, can-addressing-mode=STANDARD, can-fd-frame-support=true, can-frame-tx-behavior=CAN-FD
        pdu CDU_Version: length=32, transmission-mode-condition{data-filter=data-filter-type=ALWAYS, i-signal-in-i-pdu=isCDU_SupplierCode_mtx}, transmission-mode-true-timing=cyclic-timing={time-offset=0.0, time-period=10.0}, unused-bit-pattern=0
          signal isCDU_HwVersion: start 23, 8 bit, big-endian, data-type-policy=OVERRIDE, init-value=0, base-type=UINT8, compu {phys=raw for raw 0..255}, transfer-property=PENDING  # CDU硬件版本
          signal isCDU_SupplierCode: start 7, 16 bit, big-endian, data-type-policy=OVERRIDE, init-value=0, base-type=UINT16, compu {phys=raw for raw 0..65535}, transfer-property=PENDING  # CDU供应商代码
          signal isCDU_SwMajorVersion: start 31, 8 bit, big-endian, data-type-policy=OVERRIDE, init-value=0, base-type=UINT8, compu {phys=raw for raw 0..255}, transfer-property=PENDING  # CDU软件主版本号
          signal isCDU_SwMinorVersion: start 39, 8 bit, big-endian, data-type-policy=OVERRIDE, init-value=0, base-type=UINT8, compu {phys=raw for raw 0..255}, transfer-property=PENDING  # CDU软件子版本号
          signal isCDU_SwPatchVersion: start 47, 8 bit, big-endian, data-type-policy=OVERRIDE, init-value=0, base-type=UINT8, compu {phys=raw for raw 0..255}, transfer-property=PENDING  # CDU软件补充版本号
          signal isCDU_SwVersionDay: start 71, 8 bit, big-endian, data-type-policy=OVERRIDE, init-value=0, base-type=UINT8, compu {phys=raw for raw 0..31}, transfer-property=PENDING  # CDU软件版本日
          signal isCDU_SwVersionMonth: start 63, 8 bit, big-endian, data-type-policy=OVERRIDE, init-value=0, base-type=UINT8, compu {phys=raw for raw 0..12}, transfer-property=PENDING  # CDU软件版本月
          signal isCDU_SwVersionYear: start 55, 8 bit, big-endian, data-type-policy=OVERRIDE, init-value=0, base-type=UINT8, compu {phys=raw for raw 0..255}, transfer-property=PENDING  # CDU软件版本年-2000
          signal isDCDC_SwMajorVersion: start 79, 8 bit, big-endian, data-type-policy=OVERRIDE, init-value=0, base-type=UINT8, compu {phys=raw for raw 0..255}, transfer-property=PENDING  # DCDC软件主版本号
          signal isDCDC_SwMinorVersion: start 87, 8 bit, big-endian, data-type-policy=OVERRIDE, init-value=0, base-type=UINT8, compu {phys=raw for raw 0..255}, transfer-property=PENDING  # DCDC软件子版本号
          signal isDCDC_SwPatchVersion: start 95, 8 bit, big-endian, data-type-policy=OVERRIDE, init-value=0, base-type=UINT8, compu {phys=raw for raw 0..255}, transfer-property=PENDING  # DCDC软件补充版本号
          signal isDCDC_SwVersionDay: start 119, 8 bit, big-endian, data-type-policy=OVERRIDE, init-value=0, base-type=UINT8, compu {phys=raw for raw 0..31}, transfer-property=PENDING  # DCDC软件版本日
          signal isDCDC_SwVersionMonth: start 111, 8 bit, big-endian, data-type-policy=OVERRIDE, init-value=0, base-type=UINT8, compu {phys=raw for raw 0..12}, transfer-property=PENDING  # DCDC软件版本月
          signal isDCDC_SwVersionYear: start 103, 8 bit, big-endian, data-type-policy=OVERRIDE, init-value=0, base-type=UINT8, compu {phys=raw for raw 0..255}, transfer-property=PENDING  # DCDC软件版本年-2000
          signal isOBC_SwMajorVersion: start 127, 8 bit, big-endian, data-type-policy=OVERRIDE, init-value=0, base-type=UINT8, compu {phys=raw for raw 0..255}, transfer-property=PENDING  # OBC软件主版本号
          signal isOBC_SwMinorVersion: start 135, 8 bit, big-endian, data-type-policy=OVERRIDE, init-value=0, base-type=UINT8, compu {phys=raw for raw 0..255}, transfer-property=PENDING  # OBC软件子版本号
          signal isOBC_SwPatchVersion: start 143, 8 bit, big-endian, data-type-policy=OVERRIDE, init-value=0, base-type=UINT8, compu {phys=raw for raw 0..255}, transfer-property=PENDING  # OBC软件补充版本号
          signal isOBC_SwVersionDay: start 167, 8 bit, big-endian, data-type-policy=OVERRIDE, init-value=0, base-type=UINT8, compu {phys=raw for raw 0..31}, transfer-property=PENDING  # OBC软件版本日
          signal isOBC_SwVersionMonth: start 159, 8 bit, big-endian, data-type-policy=OVERRIDE, init-value=0, base-type=UINT8, compu {phys=raw for raw 0..12}, transfer-property=PENDING  # OBC软件版本月
          signal isOBC_SwVersionYear: start 151, 8 bit, big-endian, data-type-policy=OVERRIDE, init-value=0, base-type=UINT8, compu {phys=raw for raw 0..255}, transfer-property=PENDING  # OBC软件版本年-2000
      frame CDU_OBC_2: id 0x31A, from CCUCCfg, frame-length=32, can-addressing-mode=STANDARD, can-fd-frame-support=true, can-frame-tx-behavior=CAN-FD
        pdu CDU_OBC_2: length=32, transmission-mode-condition{data-filter=data-filter-type=ALWAYS, i-signal-in-i-pdu=isOBC_DischrgOptMaxPwr_mtx}, transmission-mode-true-timing=cyclic-timing={time-offset=0.0, time-period=0.1}, unused-bit-pattern=0
          signal isCDU_KL15_Volt: start 255, 8 bit, big-endian, data-type-policy=OVERRIDE, init-value=254, base-type=UINT8, compu-method=CDU_KL15_Volt, transfer-property=PENDING  # KL15电压(仅用于问题定位)
          signal isCDU_KL30_Volt: start 247, 8 bit, big-endian, data-type-policy=OVERRIDE, init-value=254, base-type=UINT8, compu-method=CDU_KL30_Volt, transfer-property=PENDING  # KL30电压(仅用于问题定位)
          signal isOBC_ACL1Currt: start 159, 10 bit, big-endian, data-type-policy=OVERRIDE, init-value=0, base-type=UINT10, compu {phys=raw*0.1 for raw 0..1023, 1023=OBC_ACL1Currt_1023_Invalid}, transfer-property=PENDING  # OBC交流侧L1相电流
          signal isOBC_ACL1Volt: start 115, 12 bit, big-endian, data-type-policy=OVERRIDE, init-value=0, base-type=UINT12, compu {phys=raw for raw 0..4095, 4095=OBC_ACL1Volt_4095_Invalid}, transfer-property=PENDING  # OBC交流侧L1相电压
          signal isOBC_ACL2Currt: start 161, 10 bit, big-endian, data-type-policy=OVERRIDE, init-value=1022, base-type=UINT10, compu-method=OBC_ACL2Currt, transfer-property=PENDING  # OBC交流侧L2相电流
          signal isOBC_ACL2Volt: start 135, 12 bit, big-endian, data-type-policy=OVERRIDE, init-value=4094, base-type=UINT12, compu-method=OBC_ACL2Volt, transfer-property=PENDING  # OBC交流侧L2相电压
          signal isOBC_ACL3Currt: start 183, 10 bit, big-endian, data-type-policy=OVERRIDE, init-value=1022, base-type=UINT10, compu-method=OBC_ACL3Currt, transfer-property=PENDING  # OBC交流侧L3相电流
          signal isOBC_ACL3Volt: start 139, 12 bit, big-endian, data-type-policy=OVERRIDE, init-value=4094, base-type=UINT12, compu-method=OBC_ACL3Volt, transfer-property=PENDING  # OBC交流侧L3相电压
          signal isOBC_ACPileMaxCurrt: start 103, 8 bit, big-endian, data-type-policy=OVERRIDE, init-value=0, base-type=UINT8, compu {phys=raw for raw 0..255, 255=OBC_ACPileMaxCurrt_255_Invalid}, transfer-property=PENDING  # 交流充电桩允许最大电流
          signal isOBC_ACPwr: start 202, 11 bit, big-endian, data-type-policy=OVERRIDE, init-value=0, base-type=UINT11, compu {phys=raw*0.1 for raw 0..2047, 2047=OBC_ACPwr_2047_Invalid}, transfer-property=PENDING  # OBC交流侧功率
          signal isOBC_ChrgCablePermitCurrt: start 90, 3 bit, big-endian, data-type-policy=OVERRIDE, init-value=0, base-type=UINT3, compu-method=OBC_ChrgCablePermitCurrt, transfer-property=PENDING  # OBC充电线缆额定电流
          signal isOBC_ChrgEndNum: start 239, 8 bit, big-endian, data-type-policy=OVERRIDE, init-value=0, base-type=UINT8, compu {phys=raw for raw 0..255}, transfer-property=PENDING  # OBC充电结束码
          signal isOBC_ChrgOptMaxCurrt: start 111, 10 bit, big-endian, data-type-policy=OVERRIDE, init-value=0, base-type=UINT10, compu {phys=raw*0.1 for raw 0..1023, 1023=OBC_ChrgOptMaxCurrt_1023_Invalid}, transfer-property=PENDING  # OBC充电输出最大电流
          signal isOBC_ChrgOptMaxPwr: start 47, 11 bit, big-endian, data-type-policy=OVERRIDE, init-value=0, base-type=UINT11, compu {phys=raw*0.05 for raw 0..2047, 2047=OBC_ChrgOptMaxPwr_2047_Invalid}, transfer-property=PENDING  # OBC充电输出最大功率
          signal isOBC_ChrgOptMaxVolt: start 49, 10 bit, big-endian, data-type-policy=OVERRIDE, init-value=0, base-type=UINT10, compu {phys=raw for raw 0..1023, 1023=OBC_ChrgOptMaxVolt_1023_Invalid}, transfer-property=PENDING  # OBC充电输出最大电压
          signal isOBC_ChrgOptMinVolt: start 73, 10 bit, big-endian, data-type-policy=OVERRIDE, init-value=0, base-type=UINT10, compu {phys=raw for raw 0..1023, 1023=OBC_ChrgOptMinVolt_1023_Invalid}, transfer-property=PENDING  # OBC充电输出最小电压
          signal isOBC_DCChrgMod_LimCurrt: start 223, 9 bit, big-endian, data-type-policy=OVERRIDE, init-value=150, base-type=UINT9, compu {phys=raw*2 for raw 0..255, 511=OBC_DCChrgMod_LimCurrt_511_Invalid}, transfer-property=PENDING  # 直流充电模式最大限制电流(EVR)
          signal isOBC_DCCurrt: start 199, 11 bit, big-endian, data-type-policy=OVERRIDE, init-value=0, base-type=UINT11, compu {phys=raw*0.1-102.4 for raw 0..2047, 2047=OBC_DCCurrt_2047_Invalid}, transfer-property=PENDING  # OBC直流侧电流
          signal isOBC_DchaEndNum: start 230, 4 bit, big-endian, data-type-policy=OVERRIDE, init-value=0, base-type=UINT4, compu {phys=raw for raw 0..15}, transfer-property=PENDING  # OBC放电结束码
          signal isOBC_DCVolt: start 71, 12 bit, big-endian, data-type-policy=OVERRIDE, init-value=0, base-type=UINT12, compu {phys=raw for raw 0..4095, 4095=OBC_DCVolt_4095_Invalid}, transfer-property=PENDING  # OBC直流侧电压
          signal isOBC_DischrgOptMaxPwr: start 25, 10 bit, big-endian, data-type-policy=OVERRIDE, init-value=0, base-type=UINT10, compu {phys=raw*0.1 for raw 0..1023, 1023=OBC_DischrgOptMaxPwr_1023_Invalid}, transfer-property=PENDING  # OBC放电输出最大功率
      frame CDU_APS_State: id 0x58A, from CCUCCfg, frame-length=32, can-addressing-mode=STANDARD, can-fd-frame-support=true, can-frame-tx-behavior=CAN-FD
        pdu CDU_APS_State: length=32, transmission-mode-condition{data-filter=data-filter-type=ALWAYS, i-signal-in-i-pdu=isCDU_DetailedFltInfo_mtx}, transmission-mode-true-timing=cyclic-timing={time-offset=0.0, time-period=1.0}, unused-bit-pattern=0
          signal isCDU_APS_PortA_Currt1: start 109, 14 bit, big-endian, data-type-policy=OVERRIDE, init-value=16382, base-type=UINT14, compu-method=CDU_APS_PortA_Currt1, transfer-property=PENDING  # APS 端口A电流1
          signal isCDU_APS_PortA_Currt2: start 133, 14 bit, big-endian, data-type-policy=OVERRIDE, init-value=16382, base-type=UINT14, compu-method=CDU_APS_PortA_Currt2, transfer-property=PENDING  # APS 端口A电流2
          signal isCDU_APS_PortA_Currt3: start 199, 14 bit, big-endian, data-type-policy=OVERRIDE, init-value=16382, base-type=UINT14, compu-method=CDU_APS_PortA_Currt3, transfer-property=PENDING  # APS 端口A电流3
          signal isCDU_APS_PortA_U1: start 103, 10 bit, big-endian, data-type-policy=OVERRIDE, init-value=1022, base-type=UINT10, compu-method=CDU_APS_PortA_U1, transfer-property=PENDING  # APS 端口A电压1
          signal isCDU_APS_PortA_U2: start 127, 10 bit, big-endian, data-type-policy=OVERRIDE, init-value=1022, base-type=UINT10, compu-method=CDU_APS_PortA_U2, transfer-property=PENDING  # APS 端口A电压2
          signal isCDU_APS_PortB_Currt_DCDC: start 157, 14 bit, big-endian, data-type-policy=OVERRIDE, init-value=16382, base-type=UINT14, compu-method=CDU_APS_PortB_Currt_DCDC, transfer-property=PENDING  # DCDC侧计算的PortB电流
          signal isCDU_APS_PortB_Currt_Sfty: start 181, 14 bit, big-endian, data-type-policy=OVERRIDE, init-value=16382, base-type=UINT14, compu-method=CDU_APS_PortB_Currt_Sfty, transfer-property=PENDING  # 功能安全侧计算的PortB电流
          signal isCDU_APS_PortB_U1: start 151, 10 bit, big-endian, data-type-policy=OVERRIDE, init-value=1022, base-type=UINT10, compu-method=CDU_APS_PortB_U1, transfer-property=PENDING  # APS 端口B电压1
          signal isCDU_APS_PortB_U2: start 175, 10 bit, big-endian, data-type-policy=OVERRIDE, init-value=1022, base-type=UINT10, compu-method=CDU_APS_PortB_U2, transfer-property=PENDING  # APS 端口B电压2
          signal isCDU_APS_SIGN: start 201, 1 bit, big-endian, data-type-policy=OVERRIDE, init-value=0, base-type=UINT1, compu {0=CDU_APS_SIGN_0_APS, 1=CDU_APS_SIGN_1_No_APS}, transfer-property=PENDING  # APS标记
          signal isCDU_DetailedFltInfo: start 71, 32 bit, big-endian, data-type-policy=OVERRIDE, init-value=0, base-type=UINT32, compu {phys=raw for raw 0..4294967295}, transfer-property=PENDING  # CDU详细故障信息汇总
      frame CDU_DCDC: id 0x313, from CCUCCfg, frame-length=32, can-addressing-mode=STANDARD, can-fd-frame-support=true, can-frame-tx-behavior=CAN-FD
        pdu CDU_DCDC: length=32, transmission-mode-condition{data-filter=data-filter-type=ALWAYS, i-signal-in-i-pdu=isCDU_DCDC_Checksum_mtx}, transmission-mode-true-timing=cyclic-timing={time-offset=0.0, time-period=0.1}, unused-bit-pattern=0
          signal isCDU_DCDC_Checksum: start 7, 16 bit, big-endian, data-type-policy=OVERRIDE, init-value=0, base-type=UINT16, compu {phys=raw for raw 0..65535}, transfer-property=PENDING  # CRC16 checksum (DataID: 0x8313)
          signal isCDU_DCDC_Counter: start 23, 8 bit, big-endian, data-type-policy=OVERRIDE, init-value=0, base-type=UINT8, compu {phys=raw for raw 0..255}, transfer-property=PENDING  # Rolling Counter
          signal isDCDC_AlerSt: start 122, 1 bit, big-endian, data-type-policy=OVERRIDE, init-value=0, base-type=UINT1, compu {0=DCDC_AlerSt_0_No_Error, 1=DCDC_AlerSt_1_Error}, transfer-property=PENDING  # DCDC状态报警
          signal isDCDC_CopntTemp: start 191, 8 bit, big-endian, data-type-policy=OVERRIDE, init-value=0, base-type=UINT8, compu {phys=raw-48 for raw 0..254, 255=DCDC_CopntTemp_255_Invalid}, transfer-property=PENDING  # DCDC器件温度
          signal isDCDC_DeratFlag: start 113, 1 bit, big-endian, data-type-policy=OVERRIDE, init-value=0, base-type=UINT1, compu {0=DCDC_DeratFlag_0_Nomal_Working, 1=DCDC_DeratFlag_1_Derating_Working}, transfer-property=PENDING  # DCDC降额工作标志
          signal isDCDC_EnergyConvrtDir: start 87, 1 bit, big-endian, data-type-policy=OVERRIDE, init-value=0, base-type=UINT1, compu-method=DCDC_EnergyConvrtDir, transfer-property=PENDING  # DCDC能量转换方向
          signal isDCDC_FaultLevel: start 52, 3 bit, big-endian, data-type-policy=OVERRIDE, init-value=0, base-type=UINT3, compu-method=DCDC_FaultLevel, transfer-property=PENDING  # DCDC故障等级
          signal isDCDC_FaultLightReq: start 112, 1 bit, big-endian, data-type-policy=OVERRIDE, init-value=0, base-type=UINT1, compu {0=DCDC_FaultLightReq_0_No_Request, 1=DCDC_FaultLightReq_1_Request}, transfer-property=PENDING  # DCDC故障灯点亮请求
          signal isDCDC_FlowReq: start 117, 4 bit, big-endian, data-type-policy=OVERRIDE, init-value=0, base-type=UINT4, compu-method=DCDC_FlowReq, transfer-property=PENDING  # DCDC/OBC冷却液流量请求
          signal isDCDC_HVIL_48VDCDC_St: start 47, 2 bit, big-endian, data-type-policy=OVERRIDE, init-value=0, base-type=UINT2, compu-method=DCDC_HVIL_48VDCDC_St, transfer-property=PENDING  # DCDC 48VDCDC接口高压互锁状态(预留)
          signal isDCDC_HVIL_Batt_St: start 35, 2 bit, big-endian, data-type-policy=OVERRIDE, init-value=0, base-type=UINT2, compu-method=DCDC_HVIL_Batt_St, transfer-property=PENDING  # DCDC 电池接口高压互锁状态
          signal isDCDC_HVIL_EAS_St: start 41, 2 bit, big-endian, data-type-policy=OVERRIDE, init-value=0, base-type=UINT2, compu-method=DCDC_HVIL_EAS_St, transfer-property=PENDING  # DCDC 压缩机接口高压互锁状态(预留)
          signal isDCDC_HVIL_MCU_St: start 43, 2 bit, big-endian, data-type-policy=OVERRIDE, init-value=0, base-type=UINT2, compu-method=DCDC_HVIL_MCU_St, transfer-property=PENDING  # DCDC MCU接口高压互锁状态(EVR)
          signal isDCDC_HVIL_PTC_St: start 33, 2 bit, big-endian, data-type-policy=OVERRIDE, init-value=0, base-type=UINT2, compu-method=DCDC_HVIL_PTC_St, transfer-property=PENDING  # DCDC PTC接口高压互锁状态(预留)
          signal isDCDC_HVIL_PTCR_St: start 45, 2 bit, big-endian, data-type-policy=OVERRIDE, init-value=0, base-type=UINT2, compu-method=DCDC_HVIL_PTCR_St, transfer-property=PENDING  # DCDC PTCR接口高压互锁状态(预留)
          signal isDCDC_InpWtrTemp: start 103, 8 bit, big-endian, data-type-policy=OVERRIDE, init-value=0, base-type=UINT8, compu {phys=raw-48 for raw 0..255, 255=DCDC_InpWtrTemp_255_Invalid}, transfer-property=PENDING  # DCDC/OBC入水口温度
          signal isDCDC_IptCurrt: start 152, 9 bit, big-endian, data-type-policy=OVERRIDE, init-value=0, base-type=UINT9, compu {phys=raw*0.1 for raw 0..511, 511=DCDC_IptCurrt_511_Invalid}, transfer-property=PENDING  # DCDC输入电流
          signal isDCDC_IptVolt: start 85, 14 bit, big-endian, data-type-policy=OVERRIDE, init-value=0, base-type=UINT14, compu {phys=raw*0.1 for raw 0..16383, 16383=DCDC_IptVolt_16383_Invalid}, transfer-property=PENDING  # DCDC输入电压
          signal isDCDC_LvSidePwr: start 151, 10 bit, big-endian, data-type-policy=OVERRIDE, init-value=0, base-type=UINT10, compu {phys=raw*0.01 for raw 0..1023}, transfer-property=PENDING  # DCDC低压侧功率
          signal isDCDC_MaxOptPwr: start 111, 10 bit, big-endian, data-type-policy=OVERRIDE, init-value=0, base-type=UINT10, compu {phys=raw*0.01 for raw 0..1023, 1023=DCDC_MaxOptPwr_1023_Invalid}, transfer-property=PENDING  # DCDC最大输出功率
          signal isDCDC_NoLoadCurrtFlag: start 126, 3 bit, big-endian, data-type-policy=OVERRIDE, init-value=0, base-type=UINT3, compu-method=DCDC_NoLoadCurrtFlag, transfer-property=PENDING  # DCDC空载电流标志位
          signal isDCDC_OperSt: start 55, 3 bit, big-endian, data-type-policy=OVERRIDE, init-value=0, base-type=UINT3, compu-method=DCDC_OperSt, transfer-property=PENDING  # DCDC工作状态
          signal isDCDC_OptCurrt: start 31, 12 bit, big-endian, data-type-policy=OVERRIDE, init-value=0, base-type=UINT12, compu {phys=raw*0.1 for raw 0..4095, 4095=DCDC_OptCurrt_4095_Invalid}, transfer-property=PENDING  # DCDC 输出电流
          signal isDCDC_OptVolt: start 49, 10 bit, big-endian, data-type-policy=OVERRIDE, init-value=0, base-type=UINT10, compu {phys=raw*0.05 for raw 0..1023, 1023=DCDC_OptVolt_1023_Invalid}, transfer-property=PENDING  # DCDC输出电压
          signal isDCDC_OutWtrTemp: start 199, 8 bit, big-endian, data-type-policy=OVERRIDE, init-value=0, base-type=UINT8, compu-method=DCDC_OutWtrTemp, transfer-property=PENDING  # DCDC/OBC出水口温度
          signal isDCDC_OverTemp: start 123, 1 bit, big-endian, data-type-policy=OVERRIDE, init-value=0, base-type=UINT1, compu {0=DCDC_OverTemp_0_No_Error, 1=DCDC_OverTemp_1_Error}, transfer-property=PENDING  # DCDC温度报警
          signal isDCDC_PeakPwrTi: start 175, 12 bit, big-endian, data-type-policy=OVERRIDE, init-value=0, base-type=UINT12, compu {phys=raw for raw 0..3600, 4095=DCDC_PeakPwrTi_4095_Invalid}, transfer-property=PENDING  # DCDC峰值功率时间
          signal isDCDC_PNGSt: start 121, 2 bit, big-endian, data-type-policy=OVERRIDE, init-value=1, base-type=UINT2, compu-method=DCDC_PNGSt, transfer-property=PENDING  # PNG开关状态
          signal isDCDC_DeratReason1: start 200, 1 bit, big-endian, data-type-policy=OVERRIDE, init-value=0, base-type=UINT1, compu {0=DCDC_DeratReason1_0_Normal, 1=DCDC_DeratReason1_1_Abnormal}, transfer-property=PENDING  # DCDC输入低压或高压降额
          signal isDCDC_DeratReason10: start 213, 1 bit, big-endian, data-type-policy=OVERRIDE, init-value=0, base-type=UINT1, compu {0=DCDC_DeratReason10_0_Normal, 1=DCDC_DeratReason10_1_Abnormal}, transfer-property=PENDING  # DCDC降额工作原因10
          signal isDCDC_DeratReason11: start 214, 1 bit, big-endian, data-type-policy=OVERRIDE, init-value=0, base-type=UINT1, compu {0=DCDC_DeratReason11_0_Normal, 1=DCDC_DeratReason11_1_Abnormal}, transfer-property=PENDING  # DCDC降额工作原因11
          signal isDCDC_DeratReason12: start 215, 1 bit, big-endian, data-type-policy=OVERRIDE, init-value=0, base-type=UINT1, compu {0=DCDC_DeratReason12_0_Normal, 1=DCDC_DeratReason12_1_Abnormal}, transfer-property=PENDING  # DCDC降额工作原因12
          signal isDCDC_DeratReason2: start 201, 1 bit, big-endian, data-type-policy=OVERRIDE, init-value=0, base-type=UINT1, compu {0=DCDC_DeratReason2_0_Normal, 1=DCDC_DeratReason2_1_Abnormal}, transfer-property=PENDING  # DCDC输出低压降额
          signal isDCDC_DeratReason3: start 202, 1 bit, big-endian, data-type-policy=OVERRIDE, init-value=0, base-type=UINT1, compu {0=DCDC_DeratReason3_0_Normal, 1=DCDC_DeratReason3_1_Abnormal}, transfer-property=PENDING  # DCDC冷却液高温降额
          signal isDCDC_DeratReason4: start 203, 1 bit, big-endian, data-type-policy=OVERRIDE, init-value=0, base-type=UINT1, compu {0=DCDC_DeratReason4_0_Normal, 1=DCDC_DeratReason4_1_Abnormal}, transfer-property=PENDING  # DCDC内部过温降额
          signal isDCDC_DeratReason5: start 204, 1 bit, big-endian, data-type-policy=OVERRIDE, init-value=0, base-type=UINT1, compu {0=DCDC_DeratReason5_0_Normal, 1=DCDC_DeratReason5_1_Abnormal}, transfer-property=PENDING  # DCDC降额工作原因5
          signal isDCDC_DeratReason6: start 205, 1 bit, big-endian, data-type-policy=OVERRIDE, init-value=0, base-type=UINT1, compu {0=DCDC_DeratReason6_0_Normal, 1=DCDC_DeratReason6_1_Abnormal}, transfer-property=PENDING  # DCDC降额工作原因6
          signal isDCDC_DeratReason7: start 206, 1 bit, big-endian, data-type-policy=OVERRIDE, init-value=0, base-type=UINT1, compu {0=DCDC_DeratReason7_0_Normal, 1=DCDC_DeratReason7_1_Abnormal}, transfer-property=PENDING  # DCDC降额工作原因7
          signal isDCDC_DeratReason8: start 207, 1 bit, big-endian, data-type-policy=OVERRIDE, init-value=0, base-type=UINT1, compu {0=DCDC_DeratReason8_0_Normal, 1=DCDC_DeratReason8_1_Abnormal}, transfer-property=PENDING  # DCDC降额工作原因8
          signal isDCDC_DeratReason9: start 212, 1 bit, big-endian, data-type-policy=OVERRIDE, init-value=0, base-type=UINT1, compu {0=DCDC_DeratReason9_0_Normal, 1=DCDC_DeratReason9_1_Abnormal}, transfer-property=PENDING  # DCDC降额工作原因9
          signal isDCDC_LoopOut: start 231, 10 bit, big-endian, data-type-policy=OVERRIDE, init-value=0, base-type=UINT10, compu {phys=raw*0.1 for raw 0..1023}, transfer-property=PENDING  # DCDC环路值(仅用于问题定位)
          signal isDCDC_Oring_APS_Temp: start 223, 8 bit, big-endian, data-type-policy=OVERRIDE, init-value=254, base-type=UINT8, compu-method=DCDC_Oring_APS_Temp, transfer-property=PENDING  # DCDC oring/APS管温度
      frame CDU_OBC_1: id 0x316, from CCUCCfg, frame-length=32, can-addressing-mode=STANDARD, can-fd-frame-support=true, can-frame-tx-behavior=CAN-FD
        pdu CDU_OBC_1: length=32, transmission-mode-condition{data-filter=data-filter-type=ALWAYS, i-signal-in-i-pdu=isCDU_OBC_1_Checksum_mtx}, transmission-mode-true-timing=cyclic-timing={time-offset=0.0, time-period=0.1}, unused-bit-pattern=0
          signal isCDU_OBC_1_Checksum: start 7, 16 bit, big-endian, data-type-policy=OVERRIDE, init-value=0, base-type=UINT16, compu {phys=raw for raw 0..65535}, transfer-property=PENDING  # CRC16 checksum (DataID: 0x8316)
          signal isCDU_OBC_1_Counter: start 23, 8 bit, big-endian, data-type-policy=OVERRIDE, init-value=0, base-type=UINT8, compu {phys=raw for raw 0..255}, transfer-property=PENDING  # Rolling Counter
          signal isOBC_ACInpFrq: start 166, 7 bit, big-endian, data-type-policy=OVERRIDE, init-value=0, base-type=UINT7, compu {phys=raw for raw 0..127, 127=OBC_ACInpFrq_127_Invalid}, transfer-property=PENDING  # 交流输入电压频率
          signal isOBC_AcIptSts: start 39, 2 bit, big-endian, data-type-policy=OVERRIDE, init-value=0, base-type=UINT2, compu-method=OBC_AcIptSts, transfer-property=PENDING  # OBC交流输入状态
          signal isOBC_CCRes: start 100, 13 bit, big-endian, data-type-policy=OVERRIDE, init-value=0, base-type=UINT13, compu {phys=raw for raw 0..8191}, transfer-property=PENDING  # OBCCC阻值
          signal isOBC_ChrgGunCCSts: start 50, 3 bit, big-endian, data-type-policy=OVERRIDE, init-value=0, base-type=UINT3, compu-method=OBC_ChrgGunCCSts, transfer-property=PENDING  # OBC充电枪CC状态
          signal isOBC_CopntTemp: start 119, 8 bit, big-endian, data-type-policy=OVERRIDE, init-value=0, base-type=UINT8, compu {phys=raw-48 for raw 0..254, 255=OBC_CopntTemp_255_Invalid}, transfer-property=PENDING  # OBC器件温度
          signal isOBC_CPDuty: start 95, 10 bit, big-endian, data-type-policy=OVERRIDE, init-value=0, base-type=UINT10, compu {phys=raw*0.1 for raw 0..1023, 1023=OBC_CPDuty_1023_Invalid}, transfer-property=PENDING  # OBC接收CP占空比
          signal isOBC_CPFreqSts: start 45, 1 bit, big-endian, data-type-policy=OVERRIDE, init-value=0, base-type=UINT1, compu-method=OBC_CPFreqSts, transfer-property=PENDING  # OBC接收CP频率状态
          signal isOBC_CPFrq: start 151, 12 bit, big-endian, data-type-policy=OVERRIDE, init-value=0, base-type=UINT12, compu {phys=raw for raw 0..4095, 4095=OBC_CPFrq_4095_Invalid}, transfer-property=PENDING  # CP占空比实际频率
          signal isOBC_CPOutpDuty: start 175, 10 bit, big-endian, data-type-policy=OVERRIDE, init-value=0, base-type=UINT10, compu {phys=raw*0.1 for raw 0..1023, 1023=OBC_CPOutpDuty_1023_Invalid}, transfer-property=PENDING  # OBC输出CP占空比
          signal isOBC_CPOutpVolt: start 190, 7 bit, big-endian, data-type-policy=OVERRIDE, init-value=0, base-type=UINT7, compu {phys=raw*0.1 for raw 0..127, 127=OBC_CPOutpVolt_127_Invalid}, transfer-property=PENDING  # OBC输出CP电压峰值
          signal isOBC_CPSts: start 35, 4 bit, big-endian, data-type-policy=OVERRIDE, init-value=0, base-type=UINT4, compu-method=OBC_CPSts, transfer-property=PENDING  # OBCCP信号状态
          signal isOBC_CPValidSt: start 127, 2 bit, big-endian, data-type-policy=OVERRIDE, init-value=0, base-type=UINT2, compu-method=OBC_CPValidSt, transfer-property=PENDING  # CP有效状态
          signal isOBC_CPVolt: start 86, 7 bit, big-endian, data-type-policy=OVERRIDE, init-value=0, base-type=UINT7, compu {phys=raw*0.1 for raw 0..127, 127=OBC_CPVolt_127_Invalid}, transfer-property=PENDING  # OBCCP电压峰值
          signal isOBC_DeratFlag: start 36, 1 bit, big-endian, data-type-policy=OVERRIDE, init-value=0, base-type=UINT1, compu {0=OBC_DeratFlag_0_Nomal_Working, 1=OBC_DeratFlag_1_Derating_Working}, transfer-property=PENDING  # OBC降额工作标志
          signal isOBC_DischrgLoadForm: start 41, 2 bit, big-endian, data-type-policy=OVERRIDE, init-value=0, base-type=UINT2, compu-method=OBC_DischrgLoadForm, transfer-property=PENDING  # OBC放电负载形式
          signal isOBC_FastChargeRelayNegSts: start 253, 2 bit, big-endian, data-type-policy=OVERRIDE, init-value=0, base-type=UINT2, compu-method=OBC_FastChargeRelayNegSts, transfer-property=PENDING  # 快充继电器负极状态(EVR)
          signal isOBC_FastChargeRelayPosSts: start 255, 2 bit, big-endian, data-type-policy=OVERRIDE, init-value=0, base-type=UINT2, compu-method=OBC_FastChargeRelayPosSts, transfer-property=PENDING  # 快充继电器正极状态 (EVR)
          signal isOBC_FaultLevel: start 53, 3 bit, big-endian, data-type-policy=OVERRIDE, init-value=0, base-type=UINT3, compu-method=OBC_FaultLevel, transfer-property=PENDING  # OBC故障等级
          signal isOBC_FaultLightReq: start 24, 1 bit, big-endian, data-type-policy=OVERRIDE, init-value=0, base-type=UINT1, compu {0=OBC_FaultLightReq_0_No_Request, 1=OBC_FaultLightReq_1_Request}, transfer-property=PENDING  # OBC故障灯点亮请求
          signal isOBC_HVIL_AC_St: start 55, 2 bit, big-endian, data-type-policy=OVERRIDE, init-value=0, base-type=UINT2, compu-method=OBC_HVIL_AC_St, transfer-property=PENDING  # OBC 交流充放电接口高压互锁状态
          signal isOBC_HVIL_DC_St: start 251, 2 bit, big-endian, data-type-policy=OVERRIDE, init-value=0, base-type=UINT2, compu-method=OBC_HVIL_DC_St, transfer-property=PENDING  # OBC 直流充放电接口高压互锁状态(EVR)
          signal isOBC_OperSt: start 59, 4 bit, big-endian, data-type-policy=OVERRIDE, init-value=0, base-type=UINT4, compu-method=OBC_OperSt, transfer-property=PENDING  # OBC工作状态
          signal isOBC_RatedPwrLevel: start 31, 3 bit, big-endian, data-type-policy=OVERRIDE, init-value=0, base-type=UINT3, compu-method=OBC_RatedPwrLevel, transfer-property=PENDING  # OBC额定功率等级
          signal isOBC_S2Sts: start 26, 1 bit, big-endian, data-type-policy=OVERRIDE, init-value=0, base-type=UINT1, compu {0=OBC_S2Sts_0_Open, 1=OBC_S2Sts_1_Close}, transfer-property=PENDING  # OBC S2开关状态
          signal isOBC_WorkMode: start 63, 3 bit, big-endian, data-type-policy=OVERRIDE, init-value=0, base-type=UINT3, compu-method=OBC_WorkMode, transfer-property=PENDING  # OBC工作模式
          signal isOBC_AcIptType: start 28, 1 bit, big-endian, data-type-policy=OVERRIDE, init-value=0, base-type=UINT1, compu {0=OBC_AcIptType_0_One_Phase, 1=OBC_AcIptType_1_Three_Phase}, transfer-property=PENDING  # OBC交流输入形式
          signal isOBC_ChrgDischrgStep: start 44, 3 bit, big-endian, data-type-policy=OVERRIDE, init-value=0, base-type=UINT3, compu {phys=raw for raw 0..7}, transfer-property=PENDING  # OBC充放电阶段(预留)
          signal isOBC_DeratReason1: start 192, 1 bit, big-endian, data-type-policy=OVERRIDE, init-value=0, base-type=UINT1, compu {0=OBC_DeratReason1_0_Normal, 1=OBC_DeratReason1_1_Abnormal}, transfer-property=PENDING  # PFC母线电压过低降额保护
          signal isOBC_DeratReason10: start 201, 1 bit, big-endian, data-type-policy=OVERRIDE, init-value=0, base-type=UINT1, compu {0=OBC_DeratReason10_0_Normal, 1=OBC_DeratReason10_1_Abnormal}, transfer-property=PENDING  # 充电/逆变内部过温降额
          signal isOBC_DeratReason11: start 202, 1 bit, big-endian, data-type-policy=OVERRIDE, init-value=0, base-type=UINT1, compu {0=OBC_DeratReason11_0_Normal, 1=OBC_DeratReason11_1_Abnormal}, transfer-property=PENDING  # 弱电网降额
          signal isOBC_DeratReason12: start 203, 1 bit, big-endian, data-type-policy=OVERRIDE, init-value=0, base-type=UINT1, compu {0=OBC_DeratReason12_0_Normal, 1=OBC_DeratReason12_1_Abnormal}, transfer-property=PENDING  # OBC降额工作原因12
          signal isOBC_DeratReason13: start 204, 1 bit, big-endian, data-type-policy=OVERRIDE, init-value=0, base-type=UINT1, compu {0=OBC_DeratReason13_0_Normal, 1=OBC_DeratReason13_1_Abnormal}, transfer-property=PENDING  # OBC降额工作原因13
          signal isOBC_DeratReason14: start 205, 1 bit, big-endian, data-type-policy=OVERRIDE, init-value=0, base-type=UINT1, compu {0=OBC_DeratReason14_0_Normal, 1=OBC_DeratReason14_1_Abnormal}, transfer-property=PENDING  # OBC降额工作原因14
          signal isOBC_DeratReason15: start 206, 1 bit, big-endian, data-type-policy=OVERRIDE, init-value=0, base-type=UINT1, compu {0=OBC_DeratReason15_0_Normal, 1=OBC_DeratReason15_1_Abnormal}, transfer-property=PENDING  # OBC降额工作原因15
          signal isOBC_DeratReason16: start 207, 1 bit, big-endian, data-type-policy=OVERRIDE, init-value=0, base-type=UINT1, compu {0=OBC_DeratReason16_0_Normal, 1=OBC_DeratReason16_1_Abnormal}, transfer-property=PENDING  # OBC降额工作原因16
          signal isOBC_DeratReason17: start 208, 1 bit, big-endian, data-type-policy=OVERRIDE, init-value=0, base-type=UINT1, compu {0=OBC_DeratReason17_0_Normal, 1=OBC_DeratReason17_1_Abnormal}, transfer-property=PENDING  # OBC降额工作原因17
          signal isOBC_DeratReason18: start 209, 1 bit, big-endian, data-type-policy=OVERRIDE, init-value=0, base-type=UINT1, compu {0=OBC_DeratReason18_0_Normal, 1=OBC_DeratReason18_1_Abnormal}, transfer-property=PENDING  # OBC降额工作原因18
          signal isOBC_DeratReason19: start 210, 1 bit, big-endian, data-type-policy=OVERRIDE, init-value=0, base-type=UINT1, compu {0=OBC_DeratReason19_0_Normal, 1=OBC_DeratReason19_1_Abnormal}, transfer-property=PENDING  # OBC降额工作原因19
          signal isOBC_DeratReason2: start 193, 1 bit, big-endian, data-type-policy=OVERRIDE, init-value=0, base-type=UINT1, compu {0=OBC_DeratReason2_0_Normal, 1=OBC_DeratReason2_1_Abnormal}, transfer-property=PENDING  # 充电输入低压降额
          signal isOBC_DeratReason20: start 211, 1 bit, big-endian, data-type-policy=OVERRIDE, init-value=0, base-type=UINT1, compu {0=OBC_DeratReason20_0_Normal, 1=OBC_DeratReason20_1_Abnormal}, transfer-property=PENDING  # OBC降额工作原因20
          signal isOBC_DeratReason21: start 212, 1 bit, big-endian, data-type-policy=OVERRIDE, init-value=0, base-type=UINT1, compu {0=OBC_DeratReason21_0_Normal, 1=OBC_DeratReason21_1_Abnormal}, transfer-property=PENDING  # OBC降额工作原因21
          signal isOBC_DeratReason22: start 213, 1 bit, big-endian, data-type-policy=OVERRIDE, init-value=0, base-type=UINT1, compu {0=OBC_DeratReason22_0_Normal, 1=OBC_DeratReason22_1_Abnormal}, transfer-property=PENDING  # OBC降额工作原因22
          signal isOBC_DeratReason23: start 214, 1 bit, big-endian, data-type-policy=OVERRIDE, init-value=0, base-type=UINT1, compu {0=OBC_DeratReason23_0_Normal, 1=OBC_DeratReason23_1_Abnormal}, transfer-property=PENDING  # OBC降额工作原因23
          signal isOBC_DeratReason24: start 215, 1 bit, big-endian, data-type-policy=OVERRIDE, init-value=0, base-type=UINT1, compu {0=OBC_DeratReason24_0_Normal, 1=OBC_DeratReason24_1_Abnormal}, transfer-property=PENDING  # OBC降额工作原因24
          signal isOBC_DeratReason3: start 194, 1 bit, big-endian, data-type-policy=OVERRIDE, init-value=0, base-type=UINT1, compu {0=OBC_DeratReason3_0_Normal, 1=OBC_DeratReason3_1_Abnormal}, transfer-property=PENDING  # 充电输入高压降额
          signal isOBC_DeratReason4: start 195, 1 bit, big-endian, data-type-policy=OVERRIDE, init-value=0, base-type=UINT1, compu {0=OBC_DeratReason4_0_Normal, 1=OBC_DeratReason4_1_Abnormal}, transfer-property=PENDING  # 充电输出电压过低降额
          signal isOBC_DeratReason5: start 196, 1 bit, big-endian, data-type-policy=OVERRIDE, init-value=0, base-type=UINT1, compu {0=OBC_DeratReason5_0_Normal, 1=OBC_DeratReason5_1_Abnormal}, transfer-property=PENDING  # 充电输出电压过高降额
          signal isOBC_DeratReason6: start 197, 1 bit, big-endian, data-type-policy=OVERRIDE, init-value=0, base-type=UINT1, compu {0=OBC_DeratReason6_0_Normal, 1=OBC_DeratReason6_1_Abnormal}, transfer-property=PENDING  # 充电内部环温过低降额
          signal isOBC_DeratReason7: start 198, 1 bit, big-endian, data-type-policy=OVERRIDE, init-value=0, base-type=UINT1, compu {0=OBC_DeratReason7_0_Normal, 1=OBC_DeratReason7_1_Abnormal}, transfer-property=PENDING  # 充电冷却液高温降额
          signal isOBC_DeratReason8: start 199, 1 bit, big-endian, data-type-policy=OVERRIDE, init-value=0, base-type=UINT1, compu {0=OBC_DeratReason8_0_Normal, 1=OBC_DeratReason8_1_Abnormal}, transfer-property=PENDING  # 逆变冷却液高温降额
          signal isOBC_DeratReason9: start 200, 1 bit, big-endian, data-type-policy=OVERRIDE, init-value=0, base-type=UINT1, compu {0=OBC_DeratReason9_0_Normal, 1=OBC_DeratReason9_1_Abnormal}, transfer-property=PENDING  # 逆变输入低压或高压降额
          signal isOBC_DisWorkMode: start 125, 3 bit, big-endian, data-type-policy=OVERRIDE, init-value=0, base-type=UINT3, compu-method=OBC_DisWorkMode, transfer-property=PENDING  # OBC车内逆变工作模式
          signal isOBC_EnergyConvrtDir: start 47, 1 bit, big-endian, data-type-policy=OVERRIDE, init-value=0, base-type=UINT1, compu-method=OBC_EnergyConvrtDir, transfer-property=PENDING  # OBC能量转换方向
          signal isOBC_FastChrgRelayNeg_Extd_U: start 247, 8 bit, big-endian, data-type-policy=OVERRIDE, init-value=0, base-type=UINT8, compu {phys=raw*0.1 for raw 0..255}, transfer-property=PENDING  # 快充继电器负极外部采样电压(仅用于问题定位)
          signal isOBC_FastChrgRelayPos_Extd_U: start 227, 10 bit, big-endian, data-type-policy=OVERRIDE, init-value=0, base-type=UINT10, compu {phys=raw for raw 0..1023}, transfer-property=PENDING  # 快充继电器正极外部采样电压(仅用于问题定位)
          signal isOBC_InsulationR: start 223, 12 bit, big-endian, data-type-policy=OVERRIDE, init-value=0, base-type=UINT12, compu {phys=raw for raw 0..4095}, transfer-property=PENDING  # 逆变绝缘检测阻值(仅用于问题定位)
          signal isOBC_S1Sts: start 25, 1 bit, big-endian, data-type-policy=OVERRIDE, init-value=0, base-type=UINT1, compu {0=OBC_S1Sts_0_12V_Output, 1=OBC_S1Sts_1_PWM_Output}, transfer-property=PENDING  # OBC S1开关状态
          signal isOBC_S4Sts: start 27, 1 bit, big-endian, data-type-policy=OVERRIDE, init-value=0, base-type=UINT1, compu {0=OBC_S4Sts_0_Detection_status, 1=OBC_S4Sts_1_Output_status}, transfer-property=PENDING  # OBC S4开关状态
          signal isOBC_RBMainK1Sts: start 137, 2 bit, big-endian, data-type-policy=OVERRIDE, init-value=0, base-type=UINT2, compu-method=OBC_RBMainK1Sts, transfer-property=PENDING  # K1充电回路继电器状态
          signal isOBC_RBMainK2Sts: start 139, 2 bit, big-endian, data-type-policy=OVERRIDE, init-value=0, base-type=UINT2, compu-method=OBC_RBMainK2Sts, transfer-property=PENDING  # K2充电回路继电器状态
          signal isOBC_RBMainK3Sts: start 141, 2 bit, big-endian, data-type-policy=OVERRIDE, init-value=0, base-type=UINT2, compu-method=OBC_RBMainK3Sts, transfer-property=PENDING  # K3车内逆变回路继电器状态
          signal isOBC_RBMainK4Sts: start 143, 2 bit, big-endian, data-type-policy=OVERRIDE, init-value=0, base-type=UINT2, compu-method=OBC_RBMainK4Sts, transfer-property=PENDING  # K4车内逆变回路继电器状态
      frame Diag_Resp_CDU: id 0x7BD, from CCUCCfg, frame-length=64, can-addressing-mode=STANDARD, can-fd-frame-support=true, can-frame-tx-behavior=CAN-FD
        n pdu Diag_Resp_CDU: length=64
      frame CDU_OBC_3: id 0x367, from CCUCCfg, frame-length=32, can-addressing-mode=STANDARD, can-fd-frame-support=true, can-frame-tx-behavior=CAN-FD
        pdu CDU_OBC_3: length=32, transmission-mode-condition{data-filter=data-filter-type=ALWAYS, i-signal-in-i-pdu=isDCDC_PtcInterLockVolt_mtx}, transmission-mode-true-timing=cyclic-timing={time-offset=0.0, time-period=0.1}, unused-bit-pattern=0
          signal isDCDC_DcInterLockVolt: start 39, 8 bit, big-endian, data-type-policy=OVERRIDE, init-value=0, base-type=UINT8, compu {phys=raw*0.02 for raw 0..255}, transfer-property=PENDING  # DC互锁检测电压(仅用于问题定位)
          signal isDCDC_McuInterLockVolt: start 47, 8 bit, big-endian, data-type-policy=OVERRIDE, init-value=0, base-type=UINT8, compu {phys=raw*0.02 for raw 0..255}, transfer-property=PENDING  # MCU互锁检测电压(仅用于问题定位)
          signal isDCDC_PtcInterLockVolt: start 31, 8 bit, big-endian, data-type-policy=OVERRIDE, init-value=0, base-type=UINT8, compu {phys=raw*0.02 for raw 0..255}, transfer-property=PENDING  # PTC互锁检测电压(仅用于问题定位)
          signal isOBC_AcLineImpedance: start 71, 8 bit, big-endian, data-type-policy=OVERRIDE, init-value=0, base-type=UINT8, compu {phys=raw*0.02 for raw 0..255}, transfer-property=PENDING  # AC输入线路阻抗(仅用于问题定位)
          signal isOBC_BusCapacity: start 79, 8 bit, big-endian, data-type-policy=OVERRIDE, init-value=0, base-type=UINT8, compu {phys=raw*10 for raw 0..255}, transfer-property=PENDING  # 母线电容(仅用于问题定位)
          signal isOBC_Ithd: start 63, 8 bit, big-endian, data-type-policy=OVERRIDE, init-value=0, base-type=UINT8, compu {phys=raw*0.2 for raw 0..255}, transfer-property=PENDING  # 交流输入电流畸变率(仅用于问题定位)
          signal isOBC_Uthd: start 55, 8 bit, big-endian, data-type-policy=OVERRIDE, init-value=0, base-type=UINT8, compu {phys=raw*0.2 for raw 0..255}, transfer-property=PENDING  # 交流输入电压畸变率(仅用于问题定位)
          signal isOBC_RBCurrt: start 87, 10 bit, big-endian, data-type-policy=OVERRIDE, init-value=0, base-type=UINT10, compu {phys=raw*0.1 for raw 0..1023, 1023=OBC_RBCurrt_1023_Invalid}, transfer-property=PENDING  # OBC车内逆变电流
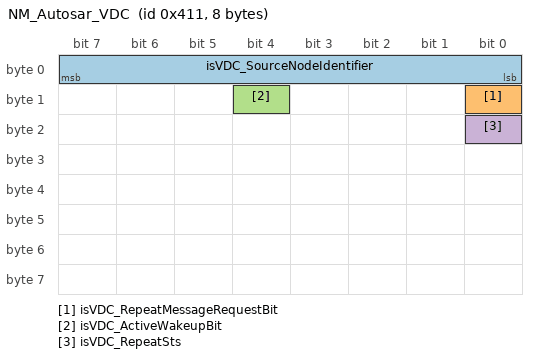
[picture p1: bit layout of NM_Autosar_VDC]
      frame NM_Autosar_VDC: id 0x411, to CCUCCfg, frame-length=8, can-addressing-mode=STANDARD, can-fd-frame-support=false, can-frame-rx-behavior=CAN-20, rx-identifier-range={lower-can-id=1024, upper-can-id=1151}
        nm pdu NM_Autosar_VDC: length=8, nm-vote-information=false, unused-bit-pattern=0
          signal isVDC_SourceNodeIdentifier: start 7, 8 bit, big-endian, data-type-policy=OVERRIDE, base-type=UINT8, compu {phys=raw for raw 0..255}  # 源节点ID
          signal isVDC_RepeatMessageRequestBit: start 8, 1 bit, big-endian, data-type-policy=OVERRIDE, base-type=UINT1, compu {0=VDC_RepeatMessageRequestBit_0_Not_Request, 1=VDC_RepeatMessageRequestBit_1_Repeat_Message_Request}  # 重复报文请求位
          signal isVDC_ActiveWakeupBit: start 12, 1 bit, big-endian, data-type-policy=OVERRIDE, base-type=UINT1, compu {0=VDC_ActiveWakeupBit_0_Passive_Wakeup, 1=VDC_ActiveWakeupBit_1_Active_Wakeup}  # 主动唤醒标志位
          signal isVDC_RepeatSts: start 16, 1 bit, big-endian, data-type-policy=OVERRIDE, base-type=UINT1, compu {0=VDC_RepeatSts_0_Not_in_the_RMS, 1=VDC_RepeatSts_1_Stay_in_the_RMS}  # 重复报文状态
      frame BMS_ChargeInfo: id 0x185, to CCUCCfg, frame-length=32, can-addressing-mode=STANDARD, can-fd-frame-support=true, can-frame-rx-behavior=CAN-FD
        pdu BMS_ChargeInfo: length=32, transmission-mode-true-timing=cyclic-timing=time-period=0.02, unused-bit-pattern=0
          signal isBMS_ChargeInfo_Checksum: start 7, 16 bit, big-endian, data-type-policy=OVERRIDE, init-value=0, base-type=UINT16, compu {phys=raw for raw 0..65535}, to CCUCCfg  # CRC16 checksum (DataID: 0x8185)
          signal isBMS_ChargeInfo_Counter: start 23, 8 bit, big-endian, data-type-policy=OVERRIDE, init-value=0, base-type=UINT8, compu {phys=raw for raw 0..255}, to CCUCCfg  # Rolling Counter
          signal isBMS_DCChrgConnectSt: start 26, 3 bit, big-endian, data-type-policy=OVERRIDE, init-value=0, base-type=UINT3, compu-method=BMS_DCChrgConnectSt, to CCUCCfg  # DC充电枪状态
          signal isBMS_OBCCurrtReq: start 155, 12 bit, big-endian, data-type-policy=OVERRIDE, init-value=4094, base-type=UINT12, compu-method=BMS_OBCCurrtReq, to CCUCCfg  # 请求OBC工作电流
          signal isBMS_OBCInvACVoltReq: start 176, 9 bit, big-endian, data-type-policy=OVERRIDE, init-value=0, base-type=UINT9, compu {phys=raw for raw 0..511, 511=BMS_OBCInvACVoltReq_511_Invalid}, to CCUCCfg  # OBC放电交流侧电压请求值
          signal isBMS_OBCInvMaxPermPwr: start 175, 10 bit, big-endian, data-type-policy=OVERRIDE, init-value=0, base-type=UINT10, compu {phys=raw*0.01 for raw 0..1023, 1023=BMS_OBCInvMaxPermPwr_1023_Invalid}, to CCUCCfg  # OBC放电功率最大允许值
          signal isBMS_OBCVoltReq: start 151, 10 bit, big-endian, data-type-policy=OVERRIDE, init-value=1022, base-type=UINT10, compu-method=BMS_OBCVoltReq, to CCUCCfg  # 请求OBC工作电压
          signal isBMS_OBCWorkModReq: start 142, 3 bit, big-endian, data-type-policy=OVERRIDE, init-value=0, base-type=UINT3, compu-method=BMS_OBCWorkModReq, to CCUCCfg  # 充电机工作模式请求
          signal isBMS_ActvHvOnReq: start 71, 8 bit, big-endian, data-type-policy=OVERRIDE, init-value=0, base-type=UINT8, compu-method=BMS_ActvHvOnReq, to CCUCCfg  # BMS主动上高压请求
      frame BMS_Measure: id 0x104, to CCUCCfg, frame-length=32, can-addressing-mode=STANDARD, can-fd-frame-support=true, can-frame-rx-behavior=CAN-FD
        pdu BMS_Measure: length=32, transmission-mode-true-timing=cyclic-timing=time-period=0.01, unused-bit-pattern=0
          signal isBMS_BattVolt_U7: start 85, 14 bit, big-endian, data-type-policy=OVERRIDE, init-value=16382, base-type=UINT14, compu-method=BMS_BattVolt_U7, to CCUCCfg  # 主正外侧电压-主负外侧电压U7(电池包后端输出电压)
          signal isBMS_Measure_Checksum: start 7, 16 bit, big-endian, data-type-policy=OVERRIDE, init-value=0, base-type=UINT16, compu {phys=raw for raw 0..65535}, to CCUCCfg  # CRC16 checksum (DataID: 0x8104)
          signal isBMS_Measure_Counter: start 23, 8 bit, big-endian, data-type-policy=OVERRIDE, init-value=0, base-type=UINT8, compu {phys=raw for raw 0..255}, to CCUCCfg  # Rolling Counter
      frame VIU_Route_EP: id 0x358, to CCUCCfg, frame-length=32, can-addressing-mode=STANDARD, can-fd-frame-support=true, can-frame-rx-behavior=CAN-FD
        pdu VIU_Route_EP: length=32, transmission-mode-true-timing={cyclic-timing=time-period=0.1, event-controlled-timing={number-of-repetitions=3, repetition-period=0.02}}, unused-bit-pattern=0
          signal isVIU_Route_EP_Checksum: start 7, 16 bit, big-endian, data-type-policy=OVERRIDE, init-value=0, base-type=UINT16, compu {phys=raw for raw 0..65535}, to CCUCCfg  # CRC16 checksum (DataID: 0x8358)
          signal isVIU_Route_EP_Counter: start 23, 8 bit, big-endian, data-type-policy=OVERRIDE, init-value=0, base-type=UINT8, compu {phys=raw for raw 0..255}, to CCUCCfg  # Rolling Counter
      frame VDC_HVCtrl: id 0x181, to CCUCCfg, frame-length=32, can-addressing-mode=STANDARD, can-fd-frame-support=true, can-frame-rx-behavior=CAN-FD
        pdu VDC_HVCtrl: length=32, transmission-mode-true-timing=cyclic-timing=time-period=0.02, unused-bit-pattern=0
          signal isVDC_BMSDchaMaxPwr: start 150, 7 bit, big-endian, data-type-policy=OVERRIDE, init-value=0, base-type=UINT7, compu {phys=raw*0.1 for raw 0..127}, to CCUCCfg  # VDC允许放电功率
          signal isVDC_DCDCEnableCmd: start 31, 3 bit, big-endian, data-type-policy=OVERRIDE, init-value=0, base-type=UINT3, compu-method=VDC_DCDCEnableCmd, to CCUCCfg  # DCDC工作使能指令
          signal isVDC_DCDCMaxCurrtAlld: start 55, 10 bit, big-endian, data-type-policy=OVERRIDE, init-value=0, base-type=UINT10, compu {phys=raw*0.5 for raw 0..1023, 1023=VDC_DCDCMaxCurrtAlld_1023_Invalid}, to CCUCCfg  # DCDC最大许用输出电流(低压侧)
          signal isVDC_DCDCSetVolt: start 39, 8 bit, big-endian, data-type-policy=OVERRIDE, init-value=0, base-type=UINT8, compu {phys=raw*0.1 for raw 0..254, 255=VDC_DCDCSetVolt_255_Invalid}, to CCUCCfg  # DCDC输出目标电压(低压侧)
          signal isVDC_HVCtrl_Checksum: start 7, 16 bit, big-endian, data-type-policy=OVERRIDE, init-value=0, base-type=UINT16, compu {phys=raw for raw 0..65535}, to CCUCCfg  # CRC16 checksum (DataID: 0x8181)
          signal isVDC_HVCtrl_Counter: start 23, 8 bit, big-endian, data-type-policy=OVERRIDE, init-value=0, base-type=UINT8, compu {phys=raw for raw 0..255}, to CCUCCfg  # Rolling Counter
          signal isVDC_OBCACCurrtMaxPerm: start 95, 7 bit, big-endian, data-type-policy=OVERRIDE, init-value=32, base-type=UINT7, compu {phys=raw for raw 0..100, 127=VDC_OBCACCurrtMaxPerm_127_Invalid}, to CCUCCfg  # OBC交流侧电流限值
      frame VDC_VehState: id 0x311, to CCUCCfg, frame-length=32, can-addressing-mode=STANDARD, can-fd-frame-support=true, can-frame-rx-behavior=CAN-FD
        pdu VDC_VehState: length=32, transmission-mode-true-timing=cyclic-timing=time-period=0.1, unused-bit-pattern=0
          signal isVDC_VehState_Checksum: start 7, 16 bit, big-endian, data-type-policy=OVERRIDE, init-value=0, base-type=UINT16, compu {phys=raw for raw 0..65535}, to CCUCCfg  # CRC16 checksum (DataID: 0x8311)
          signal isVDC_VehState_Counter: start 23, 8 bit, big-endian, data-type-policy=OVERRIDE, init-value=0, base-type=UINT8, compu {phys=raw for raw 0..255}, to CCUCCfg  # Rolling Counter
          signal isVDC_RBAllwdSts: start 122, 3 bit, big-endian, data-type-policy=OVERRIDE, init-value=0, base-type=UINT3, compu-method=VDC_RBAllwdSts, to CCUCCfg  # VDC允许车内逆变状态
          signal isVDC_RBDCACVoltReq: start 104, 9 bit, big-endian, data-type-policy=OVERRIDE, init-value=0, base-type=UINT9, compu {phys=raw for raw 0..511, 511=VDC_RBDCACVoltReq_511_Invalid}, to CCUCCfg  # 请求电压
          signal isVDC_RBEnableSt: start 110, 2 bit, big-endian, data-type-policy=OVERRIDE, init-value=0, base-type=UINT2, compu-method=VDC_RBEnableSt, to CCUCCfg  # 车内逆变硬线检测
          signal isVDC_RBMainK1K2Ctrl: start 124, 2 bit, big-endian, data-type-policy=OVERRIDE, init-value=0, base-type=UINT2, compu-method=VDC_RBMainK1K2Ctrl, to CCUCCfg  # K1K2继电器驱动指令
          signal isVDC_RBMainK3K4Ctrl: start 72, 1 bit, big-endian, data-type-policy=OVERRIDE, init-value=0, base-type=UINT1, compu {0=VDC_RBMainK3K4Ctrl_0_Open, 1=VDC_RBMainK3K4Ctrl_1_Close}, to CCUCCfg  # K3K4继电器驱动指令
          signal isVDC_RBOBCWorkModReq: start 108, 4 bit, big-endian, data-type-policy=OVERRIDE, init-value=0, base-type=UINT4, compu-method=VDC_RBOBCWorkModReq, to CCUCCfg  # 车内逆变工作模式请求
      frame VDC_SysState: id 0x184, to CCUCCfg, frame-length=32, can-addressing-mode=STANDARD, can-fd-frame-support=true, can-frame-rx-behavior=CAN-FD
        pdu VDC_SysState: length=32, transmission-mode-true-timing=cyclic-timing=time-period=0.02, unused-bit-pattern=0
          signal isVDC_ActGearSt: start 31, 4 bit, big-endian, data-type-policy=OVERRIDE, init-value=0, base-type=UINT4, compu-method=VDC_ActGearSt, to CCUCCfg  # 实际挡位
          signal isVDC_SysState_Checksum: start 7, 16 bit, big-endian, data-type-policy=OVERRIDE, init-value=0, base-type=UINT16, compu {phys=raw for raw 0..65535}, to CCUCCfg  # CRC16 checksum (DataID: 0x8184)
          signal isVDC_SysState_Counter: start 23, 8 bit, big-endian, data-type-policy=OVERRIDE, init-value=0, base-type=UINT8, compu {phys=raw for raw 0..255}, to CCUCCfg  # Rolling Counter
      frame VDC_EngyCalcu: id 0x580, to CCUCCfg, frame-length=64, can-addressing-mode=STANDARD, can-fd-frame-support=true, can-frame-rx-behavior=CAN-FD
        pdu VDC_EngyCalcu: length=64, transmission-mode-true-timing=cyclic-timing=time-period=0.5, unused-bit-pattern=0
          signal isVDC_TotalRang_VV01: start 7, 20 bit, big-endian, data-type-policy=OVERRIDE, init-value=0, base-type=UINT20, compu {phys=raw for raw 0..1048575, 1048575=VDC_TotalRang_1048575_Invalid}, to CCUCCfg
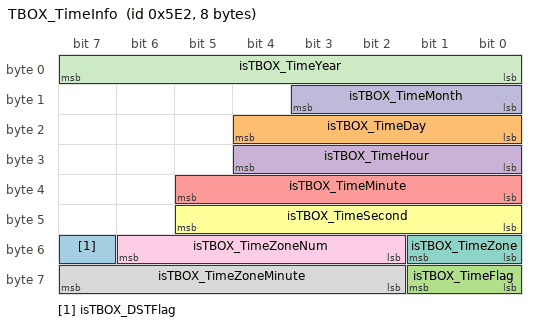
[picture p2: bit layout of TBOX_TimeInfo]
      frame TBOX_TimeInfo: id 0x5E2, to CCUCCfg, frame-length=8, can-addressing-mode=STANDARD, can-fd-frame-support=true, can-frame-rx-behavior=CAN-FD
        pdu TBOX_TimeInfo: length=8, transmission-mode-true-timing=cyclic-timing=time-period=0.5, unused-bit-pattern=0
          signal isTBOX_DSTFlag: start 55, 1 bit, big-endian, data-type-policy=OVERRIDE, init-value=0, base-type=UINT1, compu {0=TBOX_DSTFlag_0_Invalid, 1=TBOX_DSTFlag_1_Valid}, to CCUCCfg  # 夏令时标志位
          signal isTBOX_TimeDay: start 20, 5 bit, big-endian, data-type-policy=OVERRIDE, init-value=1, base-type=UINT5, compu {phys=raw for raw 1..31}, to CCUCCfg  # 本地时间_日
          signal isTBOX_TimeFlag: start 57, 2 bit, big-endian, data-type-policy=OVERRIDE, init-value=0, base-type=UINT2, compu-method=TBOX_TimeFlag, to CCUCCfg  # 时间有效性标志
          signal isTBOX_TimeHour: start 28, 5 bit, big-endian, data-type-policy=OVERRIDE, init-value=0, base-type=UINT5, compu {phys=raw for raw 0..23}, to CCUCCfg  # 本地时间_时
          signal isTBOX_TimeMinute: start 37, 6 bit, big-endian, data-type-policy=OVERRIDE, init-value=0, base-type=UINT6, compu {phys=raw for raw 0..59}, to CCUCCfg  # 本地时间_分
          signal isTBOX_TimeSecond: start 45, 6 bit, big-endian, data-type-policy=OVERRIDE, init-value=0, base-type=UINT6, compu {phys=raw for raw 0..59}, to CCUCCfg  # 本地时间_秒
          signal isTBOX_TimeZone: start 49, 2 bit, big-endian, data-type-policy=OVERRIDE, init-value=0, base-type=UINT2, compu-method=TBOX_TimeZone, to CCUCCfg  # 东/西时区
          signal isTBOX_TimeZoneMinute: start 63, 6 bit, big-endian, data-type-policy=OVERRIDE, init-value=0, base-type=UINT6, compu {phys=raw for raw 0..59}, to CCUCCfg  # 时区信息_分钟
          signal isTBOX_TimeZoneNum: start 54, 5 bit, big-endian, data-type-policy=OVERRIDE, init-value=0, base-type=UINT5, compu-method=TBOX_TimeZoneNum, to CCUCCfg  # 时区编号
          signal isTBOX_TimeMonth: start 11, 4 bit, big-endian, data-type-policy=OVERRIDE, init-value=1, base-type=UINT4, compu {phys=raw for raw 1..12}, to CCUCCfg  # 本地时间_月
          signal isTBOX_TimeYear: start 7, 8 bit, big-endian, data-type-policy=OVERRIDE, init-value=0, base-type=UINT8, compu {phys=raw+2000 for raw 0..255}, to CCUCCfg  # 本地时间_年
      frame Diag_FuncReq_PT: id 0x7DF, to CCUCCfg, frame-length=8, can-addressing-mode=STANDARD, can-fd-frame-support=true, can-frame-rx-behavior=CAN-FD
        n pdu Diag_FuncReq_PT: length=8
      frame IPB_Wheel: id 0x117, to CCUCCfg, frame-length=32, can-addressing-mode=STANDARD, can-fd-frame-support=true, can-frame-rx-behavior=CAN-FD
        pdu IPB_Wheel: length=32, transmission-mode-true-timing=cyclic-timing=time-period=0.01, unused-bit-pattern=0
          signal isIPB_VehicleSpeed: start 204, 13 bit, big-endian, data-type-policy=OVERRIDE, init-value=0, base-type=UINT13, compu {phys=raw*0.05625 for raw 0..8191, 8191=IPB_VehicleSpeed_8191_Invalid}, to CCUCCfg  # 车速
          signal isIPB_VehicleSpeedValid: start 205, 1 bit, big-endian, data-type-policy=OVERRIDE, init-value=0, base-type=UINT1, compu {0=IPB_VehicleSpeedValid_0_Invalid, 1=IPB_VehicleSpeedValid_1_Valid}, to CCUCCfg  # 车速有效位
      frame Diag_PhyReq_CDU: id 0x73D, to CCUCCfg, frame-length=64, can-addressing-mode=STANDARD, can-fd-frame-support=true, can-frame-rx-behavior=CAN-FD
        n pdu Diag_PhyReq_CDU: length=64
      frame VIU_Info_VV02: id 0x1D3, to CCUCCfg, frame-length=32, can-addressing-mode=STANDARD, can-fd-frame-support=true, can-frame-rx-behavior=CAN-FD
        pdu VIU_Info_PT: length=32, transmission-mode-true-timing=cyclic-timing=time-period=0.02, unused-bit-pattern=0
          signal isVIU_Info_Counter: start 23, 8 bit, big-endian, data-type-policy=OVERRIDE, init-value=0, base-type=UINT8, compu {phys=raw for raw 0..255}, to CCUCCfg  # RollingCounter
          signal isVIU_CarMode: start 27, 4 bit, big-endian, data-type-policy=OVERRIDE, init-value=14, base-type=UINT4, compu-method=VIU_CarMode, to CCUCCfg  # 车辆模式
          signal isVIU_UsageMode: start 31, 4 bit, big-endian, data-type-policy=OVERRIDE, init-value=1, base-type=UINT4, compu-method=VIU_UsageMode, to CCUCCfg  # 用户模式
          signal isVIU_PowerMode: start 39, 2 bit, big-endian, data-type-policy=OVERRIDE, init-value=0, base-type=UINT2, compu-method=VIU_PowerMode, to CCUCCfg  # 电源模式
          signal isVIU_Info_Checksum_VV01: start 7, 16 bit, big-endian, data-type-policy=OVERRIDE, init-value=0, base-type=UINT16, compu {phys=raw for raw 0..65535}, to CCUCCfg  # CRC16 Checksum(Data ID:0x81D3)
      frame BMS_State: id 0x107, to CCUCCfg, frame-length=32, can-addressing-mode=STANDARD, can-fd-frame-support=true, can-frame-rx-behavior=CAN-FD
        pdu BMS_State: length=32, transmission-mode-true-timing=cyclic-timing=time-period=0.01, unused-bit-pattern=0
          signal isBMS_MainNegSt: start 45, 2 bit, big-endian, data-type-policy=OVERRIDE, init-value=0, base-type=UINT2, compu-method=BMS_MainNegSt, to CCUCCfg  # 主负继电器状态
          signal isBMS_MainPosSt: start 47, 2 bit, big-endian, data-type-policy=OVERRIDE, init-value=0, base-type=UINT2, compu-method=BMS_MainPosSt, to CCUCCfg  # 主正继电器状态
          signal isBMS_MainPreChrgSt: start 43, 2 bit, big-endian, data-type-policy=OVERRIDE, init-value=0, base-type=UINT2, compu-method=BMS_MainPreChrgSt, to CCUCCfg  # 预充继电器状态
          signal isBMS_OperSt: start 59, 4 bit, big-endian, data-type-policy=OVERRIDE, init-value=0, base-type=UINT4, compu-method=BMS_OperSt, to CCUCCfg  # BMS工作状态
      pdu triggering PduTrDCM_DIAGCAN_FunReq: pdu=DCM_DIAGCAN_FunReq, to CCUCCfg
      pdu triggering PduTrDCM_DIAGCAN_PhysResp_CCU: pdu=DCM_DIAGCAN_PhysResp_CCU, from CCUCCfg
      pdu triggering PduTrDCM_DIAGCAN_PhysReq_CCU: pdu=DCM_DIAGCAN_PhysReq_CCU, to CCUCCfg
package /Communication/Pdu
  dcm i pdu DCM_DIAGCAN_FunReq: length=7, diag-pdu-type=DIAG-REQUEST
  dcm i pdu DCM_DIAGCAN_PhysResp_CCU: length=4095, diag-pdu-type=DIAG-RESPONSE
  dcm i pdu DCM_DIAGCAN_PhysReq_CCU: length=4095, diag-pdu-type=DIAG-REQUEST
package /Communication/ISignalPduGroup
  4 x i signal i pdu group:
    TxMPG_PTCANFDConnector_Ctrl: communication-direction=OUT, communication-mode=tx, contained-i-signal-i-pdu-group=TxSPG_PTCANFDConnector_Ctrl
    TxSPG_PTCANFDConnector_Ctrl: communication-direction=OUT, communication-mode=tx, i-signal-i-pdus=[CDU_OBC_3, CDU_DCDC, CDU_Version, CDU_APS_State, CDU_OBC_2, CDU_OBC_1, CDU_Fault]
    RxMPG_PTCANFDConnector_Ctrl: communication-direction=IN, communication-mode=rx, contained-i-signal-i-pdu-group=RxSPG_PTCANFDConnector_Ctrl
    RxSPG_PTCANFDConnector_Ctrl: communication-direction=IN, communication-mode=rx
      i-signal-i-pdus:
        VIU_Info_PT
        BMS_Measure
        IPB_Wheel
        VDC_SysState
        BMS_State
        BMS_ChargeInfo
        VIU_Route_EP
        VDC_VehState
        VDC_HVCtrl
        TBOX_TimeInfo
        VDC_EngyCalcu
package /Communication/NmConfig
  nm config NmConfig_PTCANFD: can-nm-cluster-coupling{coupled-cluster=CanNmPTCANFD, nm-busload-reduction-enabled=false, nm-immediate-restart-enabled=false}
    can nm cluster CanNmPTCANFD:
      communication-cluster=PTCANFD
      nm-channel-id=7
      nm-channel-sleep-master=false
      nm-synchronizing-network=false
      nm-busload-reduction-active=false
      nm-car-wake-up-filter-enabled=false
      nm-car-wake-up-rx-enabled=false
      nm-cbv-position=1
      nm-channel-active=true
      nm-immediate-nm-cycle-time=0.01
      nm-immediate-nm-transmissions=20
      nm-message-timeout-time=0.08
      nm-msg-cycle-time=0.1
      nm-network-timeout=5.0
      nm-nid-position=0
      nm-remote-sleep-indication-time=2.0
      nm-repeat-message-time=1.0
      nm-user-data-length=6
      nm-wait-bus-sleep-time=1.0
      can nm node CCU: controller=PTCANFDConnector_Ctrl, nm-if-ecu=CCU, nm-node-id=21, nm-passive-mode-enabled=false, rx-nm-pdu=NM_Autosar_VDC, tx-nm-pdu=NM_Autosar_CDU, nm-msg-cycle-offset=0.0, nm-msg-reduced-time=0.1, nm-range-config={lower-can-id=1024, upper-can-id=1151}
    nm-if-ecus:
      nm ecu CCU:
        bus-specific-nm-ecu=can-nm-ecu=nm-repeat-msg-indication-enabled=true
        ecu-instance=CCUCCfg
        nm-bus-synchronization-enabled=false
        nm-com-control-enabled=true
        nm-cycletime-main-function=0.01
        nm-node-detection-enabled=true
        nm-node-id-enabled=true
        nm-passive-mode-enabled=false
        nm-pdu-rx-indication-enabled=true
        nm-remote-sleep-ind-enabled=false
        nm-repeat-msg-ind-enabled=true
        nm-state-change-ind-enabled=true
        nm-user-data-enabled=true
package /Communication/TpConfig
  can tp config CanTpConfig_PTCANFD: communication-cluster=PTCANFD, can-tp-ecu=CCUCCfg
    9 x can tp address:
      MultiCanTpAddress: tp-address=255
      CanTpAddress_VIU: tp-address=1
      CanTpAddress_BMS: tp-address=2
      CanTpAddress_CCU: tp-address=3
      CanTpAddress_HVAC: tp-address=16
      CanTpAddress_PEU: tp-address=4
      CanTpAddress_PICU: tp-address=5
      CanTpAddress_TC: tp-address=6
      CanTpAddress_SAC: tp-address=8
    can tp channel CanTpChannel_PTCANFD: channel-id=9, channel-mode=HALF-DUPLEX-MODE
    tp-connections:
      addressing-format=STANDARD, can-tp-channel=CanTpChannel_PTCANFD, data-pdu=Diag_FuncReq_PT, max-block-size=8, multicast=MultiCanTpAddress, padding-activation=true, receiver=[BMS, CCU, HVAC, PEU, PICU, TC, SAC], ta-type=FUNCTIONAL-CAN-FD, timeout-br=0.05, timeout-bs=1.0, timeout-cr=1.0, timeout-cs=0.4, tp-sdu=DCM_DIAGCAN_FunReq, transmit-cancellation=true, transmitter=VIU
      addressing-format=STANDARD, can-tp-channel=CanTpChannel_PTCANFD, data-pdu=Diag_Resp_CDU, flow-control-pdu=Diag_PhyReq_CDU, max-block-size=8, padding-activation=true, receiver=VIU, ta-type=PHYSICAL-CAN-FD, timeout-br=0.05, timeout-bs=1.0, timeout-cr=1.0, timeout-cs=0.4, tp-sdu=DCM_DIAGCAN_PhysResp_CCU, transmit-cancellation=true, transmitter=CCU
      addressing-format=STANDARD, can-tp-channel=CanTpChannel_PTCANFD, data-pdu=Diag_PhyReq_CDU, flow-control-pdu=Diag_Resp_CDU, max-block-size=8, padding-activation=true, receiver=CCU, ta-type=PHYSICAL-CAN-FD, timeout-br=0.05, timeout-bs=1.0, timeout-cr=1.0, timeout-cs=0.4, tp-sdu=DCM_DIAGCAN_PhysReq_CCU, transmit-cancellation=true, transmitter=VIU
    8 x can tp node, all with max-fc-wait=2, timeout-ar=0.5:
      VIU: st-min=0.02, timeout-as=0.5, tp-address=CanTpAddress_VIU
      BMS: tp-address=CanTpAddress_BMS
      CCU: connector=PTCANFDConnector, st-min=0.02, timeout-as=0.5, tp-address=CanTpAddress_CCU
      HVAC: tp-address=CanTpAddress_HVAC
      PEU: tp-address=CanTpAddress_PEU
      PICU: tp-address=CanTpAddress_PICU
      TC: tp-address=CanTpAddress_TC
      SAC: tp-address=CanTpAddress_SAC
package /DataType
  data type mapping set DataTypeMappingSet
  253 x app type, all with category=VALUE:
    CDU_ActiveWakeupBit_dt: compu-method=CDU_ActiveWakeupBit
    CDU_APS_PortA_Currt{1..3}_dt: compu-method=CDU_APS_PortA_Currt{1..3}
    CDU_APS_PortA_U1_dt: compu-method=CDU_APS_PortA_U1
    CDU_APS_PortA_U2_dt: compu-method=CDU_APS_PortA_U2
    CDU_APS_PortB_Currt_DCDC_dt: compu-method=CDU_APS_PortB_Currt_DCDC
    CDU_APS_PortB_Currt_Sfty_dt: compu-method=CDU_APS_PortB_Currt_Sfty
    CDU_APS_PortB_U1_dt: compu-method=CDU_APS_PortB_U1
    CDU_APS_PortB_U2_dt: compu-method=CDU_APS_PortB_U2
    CDU_APS_SIGN_dt: compu {0=CDU_APS_SIGN_0_APS, 1=CDU_APS_SIGN_1_No_APS}
    CDU_DCDC_Checksum_dt: compu {phys=raw for raw 0..65535}
    CDU_DCDC_Counter_dt: compu {phys=raw for raw 0..255}
    CDU_DetailedFltInfo_dt: compu {phys=raw for raw 0..4294967295}
    CDU_FaultNum1_dt: compu {phys=raw for raw 0..4095}
    CDU_FaultNum{10..19}_dt: compu {phys=raw for raw 0..4095}
    CDU_FaultNum2_dt: compu {phys=raw for raw 0..4095}
    CDU_FaultNum20_dt: compu {phys=raw for raw 0..4095}
    CDU_FaultNum{3..9}_dt: compu {phys=raw for raw 0..4095}
    CDU_FirstWakeupReason_dt: compu-method=CDU_FirstWakeupReason
    CDU_FrameIndex_dt: compu {phys=raw for raw 0..31}
    CDU_HwVersion_dt: compu {phys=raw for raw 0..255}
    CDU_KL15_Volt_dt: compu-method=CDU_KL15_Volt
    CDU_KL30_Volt_dt: compu-method=CDU_KL30_Volt
    CDU_NMReq_ACDchaChrgr_dt: compu {0=CDU_NMReq_ACDchaChrgr_0_Inactive, 1=CDU_NMReq_ACDchaChrgr_1_Active}
    CDU_NMReq_Diag_dt: compu {0=CDU_NMReq_Diag_0_Inactive, 1=CDU_NMReq_Diag_1_Active}
    CDU_NMReq_NM_dt: compu {0=CDU_NMReq_NM_0_Inactive, 1=CDU_NMReq_NM_1_Active}
    CDU_NMReq_Poweron_dt: compu {0=CDU_NMReq_Poweron_0_Inactive, 1=CDU_NMReq_Poweron_1_Active}
    CDU_OBC_1_Checksum_dt: compu {phys=raw for raw 0..65535}
    CDU_OBC_1_Counter_dt: compu {phys=raw for raw 0..255}
    CDU_RepeatMessageRequestBit_dt: compu-method=CDU_RepeatMessageRequestBit
    CDU_RepeatSts_dt: compu {0=CDU_RepeatSts_0_Not_in_the_RMS, 1=CDU_RepeatSts_1_Stay_in_the_RMS}
    CDU_SourceNodeIdentifier_dt: compu {phys=raw for raw 0..255}
    CDU_SupplierCode_dt: compu {phys=raw for raw 0..65535}
    CDU_SupplierNum_dt: compu {phys=raw for raw 0..7}
    CDU_SwMajorVersion_dt: compu {phys=raw for raw 0..255}
    CDU_SwMinorVersion_dt: compu {phys=raw for raw 0..255}
    CDU_SwPatchVersion_dt: compu {phys=raw for raw 0..255}
    CDU_SwVersionDay_dt: compu {phys=raw for raw 0..31}
    CDU_SwVersionMonth_dt: compu {phys=raw for raw 0..12}
    CDU_SwVersionYear_dt: compu {phys=raw for raw 0..255}
    CDU_TotalFaultNum_dt: compu {phys=raw for raw 0..255}
    DCDC_AlerSt_dt: compu {0=DCDC_AlerSt_0_No_Error, 1=DCDC_AlerSt_1_Error}
    DCDC_CopntTemp_dt: compu {phys=raw-48 for raw 0..254, 255=DCDC_CopntTemp_255_Invalid}
    DCDC_DcInterLockVolt_dt: compu {phys=raw*0.02 for raw 0..255}
    DCDC_DeratFlag_dt: compu {0=DCDC_DeratFlag_0_Nomal_Working, 1=DCDC_DeratFlag_1_Derating_Working}
    DCDC_DeratReason1_dt: compu {0=DCDC_DeratReason1_0_Normal, 1=DCDC_DeratReason1_1_Abnormal}
    DCDC_DeratReason{10..12}_dt: compu {0=DCDC_DeratReason{10..12}_0_Normal, 1=DCDC_DeratReason{10..12}_1_Abnormal}
    DCDC_DeratReason{2..9}_dt: compu {0=DCDC_DeratReason{2..9}_0_Normal, 1=DCDC_DeratReason{2..9}_1_Abnormal}
    DCDC_EnergyConvrtDir_dt: compu-method=DCDC_EnergyConvrtDir
    DCDC_FaultLevel_dt: compu-method=DCDC_FaultLevel
    DCDC_FaultLightReq_dt: compu {0=DCDC_FaultLightReq_0_No_Request, 1=DCDC_FaultLightReq_1_Request}
    DCDC_FlowReq_dt: compu-method=DCDC_FlowReq
    DCDC_HVIL_48VDCDC_St_dt: compu-method=DCDC_HVIL_48VDCDC_St
    DCDC_HVIL_Batt_St_dt: compu-method=DCDC_HVIL_Batt_St
    DCDC_HVIL_EAS_St_dt: compu-method=DCDC_HVIL_EAS_St
    DCDC_HVIL_MCU_St_dt: compu-method=DCDC_HVIL_MCU_St
    DCDC_HVIL_PTC_St_dt: compu-method=DCDC_HVIL_PTC_St
    DCDC_HVIL_PTCR_St_dt: compu-method=DCDC_HVIL_PTCR_St
    DCDC_InpWtrTemp_dt: compu {phys=raw-48 for raw 0..255, 255=DCDC_InpWtrTemp_255_Invalid}
    DCDC_IptCurrt_dt: compu {phys=raw*0.1 for raw 0..511, 511=DCDC_IptCurrt_511_Invalid}
    DCDC_IptVolt_dt: compu {phys=raw*0.1 for raw 0..16383, 16383=DCDC_IptVolt_16383_Invalid}
    DCDC_LoopOut_dt: compu {phys=raw*0.1 for raw 0..1023}
    DCDC_LvSidePwr_dt: compu {phys=raw*0.01 for raw 0..1023}
    DCDC_MaxOptPwr_dt: compu {phys=raw*0.01 for raw 0..1023, 1023=DCDC_MaxOptPwr_1023_Invalid}
    DCDC_McuInterLockVolt_dt: compu {phys=raw*0.02 for raw 0..255}
    DCDC_NoLoadCurrtFlag_dt: compu-method=DCDC_NoLoadCurrtFlag
    DCDC_OperSt_dt: compu-method=DCDC_OperSt
    DCDC_OptCurrt_dt: compu {phys=raw*0.1 for raw 0..4095, 4095=DCDC_OptCurrt_4095_Invalid}
    DCDC_OptVolt_dt: compu {phys=raw*0.05 for raw 0..1023, 1023=DCDC_OptVolt_1023_Invalid}
    DCDC_Oring_APS_Temp_dt: compu-method=DCDC_Oring_APS_Temp
    DCDC_OutWtrTemp_dt: compu-method=DCDC_OutWtrTemp
    DCDC_OverTemp_dt: compu {0=DCDC_OverTemp_0_No_Error, 1=DCDC_OverTemp_1_Error}
    DCDC_PeakPwrTi_dt: compu {phys=raw for raw 0..3600, 4095=DCDC_PeakPwrTi_4095_Invalid}
    DCDC_PNGSt_dt: compu-method=DCDC_PNGSt
    DCDC_PtcInterLockVolt_dt: compu {phys=raw*0.02 for raw 0..255}
    DCDC_SwMajorVersion_dt: compu {phys=raw for raw 0..255}
    DCDC_SwMinorVersion_dt: compu {phys=raw for raw 0..255}
    DCDC_SwPatchVersion_dt: compu {phys=raw for raw 0..255}
    DCDC_SwVersionDay_dt: compu {phys=raw for raw 0..31}
    DCDC_SwVersionMonth_dt: compu {phys=raw for raw 0..12}
    DCDC_SwVersionYear_dt: compu {phys=raw for raw 0..255}
    OBC_ACInpFrq_dt: compu {phys=raw for raw 0..127, 127=OBC_ACInpFrq_127_Invalid}
    OBC_AcIptSts_dt: compu-method=OBC_AcIptSts
    OBC_AcIptType_dt: compu {0=OBC_AcIptType_0_One_Phase, 1=OBC_AcIptType_1_Three_Phase}
    OBC_ACL1Currt_dt: compu {phys=raw*0.1 for raw 0..1023, 1023=OBC_ACL1Currt_1023_Invalid}
    OBC_ACL1Volt_dt: compu {phys=raw for raw 0..4095, 4095=OBC_ACL1Volt_4095_Invalid}
    OBC_ACL2Currt_dt: compu-method=OBC_ACL2Currt
    OBC_ACL2Volt_dt: compu-method=OBC_ACL2Volt
    OBC_ACL3Currt_dt: compu-method=OBC_ACL3Currt
    OBC_ACL3Volt_dt: compu-method=OBC_ACL3Volt
    OBC_AcLineImpedance_dt: compu {phys=raw*0.02 for raw 0..255}
    OBC_ACPileMaxCurrt_dt: compu {phys=raw for raw 0..255, 255=OBC_ACPileMaxCurrt_255_Invalid}
    OBC_ACPwr_dt: compu {phys=raw*0.1 for raw 0..2047, 2047=OBC_ACPwr_2047_Invalid}
    OBC_BusCapacity_dt: compu {phys=raw*10 for raw 0..255}
    OBC_CCRes_dt: compu {phys=raw for raw 0..8191}
    OBC_ChrgCablePermitCurrt_dt: compu-method=OBC_ChrgCablePermitCurrt
    OBC_ChrgDischrgStep_dt: compu {phys=raw for raw 0..7}
    OBC_ChrgEndNum_dt: compu {phys=raw for raw 0..255}
    OBC_ChrgGunCCSts_dt: compu-method=OBC_ChrgGunCCSts
    OBC_ChrgOptMaxCurrt_dt: compu {phys=raw*0.1 for raw 0..1023, 1023=OBC_ChrgOptMaxCurrt_1023_Invalid}
    OBC_ChrgOptMaxPwr_dt: compu {phys=raw*0.05 for raw 0..2047, 2047=OBC_ChrgOptMaxPwr_2047_Invalid}
    OBC_ChrgOptMaxVolt_dt: compu {phys=raw for raw 0..1023, 1023=OBC_ChrgOptMaxVolt_1023_Invalid}
    OBC_ChrgOptMinVolt_dt: compu {phys=raw for raw 0..1023, 1023=OBC_ChrgOptMinVolt_1023_Invalid}
    OBC_CopntTemp_dt: compu {phys=raw-48 for raw 0..254, 255=OBC_CopntTemp_255_Invalid}
    OBC_CPDuty_dt: compu {phys=raw*0.1 for raw 0..1023, 1023=OBC_CPDuty_1023_Invalid}
    OBC_CPFreqSts_dt: compu-method=OBC_CPFreqSts
    OBC_CPFrq_dt: compu {phys=raw for raw 0..4095, 4095=OBC_CPFrq_4095_Invalid}
    OBC_CPOutpDuty_dt: compu {phys=raw*0.1 for raw 0..1023, 1023=OBC_CPOutpDuty_1023_Invalid}
    OBC_CPOutpVolt_dt: compu {phys=raw*0.1 for raw 0..127, 127=OBC_CPOutpVolt_127_Invalid}
    OBC_CPSts_dt: compu-method=OBC_CPSts
    OBC_CPValidSt_dt: compu-method=OBC_CPValidSt
    OBC_CPVolt_dt: compu {phys=raw*0.1 for raw 0..127, 127=OBC_CPVolt_127_Invalid}
    OBC_DCChrgMod_LimCurrt_dt: compu {phys=raw*2 for raw 0..255, 511=OBC_DCChrgMod_LimCurrt_511_Invalid}
    OBC_DCCurrt_dt: compu {phys=raw*0.1-102.4 for raw 0..2047, 2047=OBC_DCCurrt_2047_Invalid}
    OBC_DchaEndNum_dt: compu {phys=raw for raw 0..15}
    OBC_DCVolt_dt: compu {phys=raw for raw 0..4095, 4095=OBC_DCVolt_4095_Invalid}
    OBC_DeratFlag_dt: compu {0=OBC_DeratFlag_0_Nomal_Working, 1=OBC_DeratFlag_1_Derating_Working}
    OBC_DeratReason1_dt: compu {0=OBC_DeratReason1_0_Normal, 1=OBC_DeratReason1_1_Abnormal}
    OBC_DeratReason{10..19}_dt: compu {0=OBC_DeratReason{10..19}_0_Normal, 1=OBC_DeratReason{10..19}_1_Abnormal}
    OBC_DeratReason2_dt: compu {0=OBC_DeratReason2_0_Normal, 1=OBC_DeratReason2_1_Abnormal}
    OBC_DeratReason{20..24}_dt: compu {0=OBC_DeratReason{20..24}_0_Normal, 1=OBC_DeratReason{20..24}_1_Abnormal}
    OBC_DeratReason{3..9}_dt: compu {0=OBC_DeratReason{3..9}_0_Normal, 1=OBC_DeratReason{3..9}_1_Abnormal}
    OBC_DischrgLoadForm_dt: compu-method=OBC_DischrgLoadForm
    OBC_DischrgOptMaxPwr_dt: compu {phys=raw*0.1 for raw 0..1023, 1023=OBC_DischrgOptMaxPwr_1023_Invalid}
    OBC_DisWorkMode_dt: compu-method=OBC_DisWorkMode
    OBC_EnergyConvrtDir_dt: compu-method=OBC_EnergyConvrtDir
    OBC_FastChargeRelayNegSts_dt: compu-method=OBC_FastChargeRelayNegSts
    OBC_FastChargeRelayPosSts_dt: compu-method=OBC_FastChargeRelayPosSts
    OBC_FastChrgRelayNeg_Extd_U_dt: compu {phys=raw*0.1 for raw 0..255}
    OBC_FastChrgRelayPos_Extd_U_dt: compu {phys=raw for raw 0..1023}
    OBC_FaultLevel_dt: compu-method=OBC_FaultLevel
    OBC_FaultLightReq_dt: compu {0=OBC_FaultLightReq_0_No_Request, 1=OBC_FaultLightReq_1_Request}
    OBC_HVIL_AC_St_dt: compu-method=OBC_HVIL_AC_St
    OBC_HVIL_DC_St_dt: compu-method=OBC_HVIL_DC_St
    OBC_InsulationR_dt: compu {phys=raw for raw 0..4095}
    OBC_Ithd_dt: compu {phys=raw*0.2 for raw 0..255}
    OBC_OperSt_dt: compu-method=OBC_OperSt
    OBC_RatedPwrLevel_dt: compu-method=OBC_RatedPwrLevel
    OBC_RBCurrt_dt: compu {phys=raw*0.1 for raw 0..1023, 1023=OBC_RBCurrt_1023_Invalid}
    OBC_RBMainK{1..4}Sts_dt: compu-method=OBC_RBMainK{1..4}Sts
    OBC_S1Sts_dt: compu {0=OBC_S1Sts_0_12V_Output, 1=OBC_S1Sts_1_PWM_Output}
    OBC_S2Sts_dt: compu {0=OBC_S2Sts_0_Open, 1=OBC_S2Sts_1_Close}
    OBC_S4Sts_dt: compu {0=OBC_S4Sts_0_Detection_status, 1=OBC_S4Sts_1_Output_status}
    OBC_SwMajorVersion_dt: compu {phys=raw for raw 0..255}
    OBC_SwMinorVersion_dt: compu {phys=raw for raw 0..255}
    OBC_SwPatchVersion_dt: compu {phys=raw for raw 0..255}
    OBC_SwVersionDay_dt: compu {phys=raw for raw 0..31}
    OBC_SwVersionMonth_dt: compu {phys=raw for raw 0..12}
    OBC_SwVersionYear_dt: compu {phys=raw for raw 0..255}
    OBC_Uthd_dt: compu {phys=raw*0.2 for raw 0..255}
    OBC_WorkMode_dt: compu-method=OBC_WorkMode
    BMS_ActvHvOnReq_dt: compu-method=BMS_ActvHvOnReq
    BMS_BattVolt_U7_dt: compu-method=BMS_BattVolt_U7
    BMS_ChargeInfo_Checksum_dt: compu {phys=raw for raw 0..65535}
    BMS_ChargeInfo_Counter_dt: compu {phys=raw for raw 0..255}
    BMS_DCChrgConnectSt_dt: compu-method=BMS_DCChrgConnectSt
    BMS_MainNegSt_dt: compu-method=BMS_MainNegSt
    BMS_MainPosSt_dt: compu-method=BMS_MainPosSt
    BMS_MainPreChrgSt_dt: compu-method=BMS_MainPreChrgSt
    BMS_Measure_Checksum_dt: compu {phys=raw for raw 0..65535}
    BMS_Measure_Counter_dt: compu {phys=raw for raw 0..255}
    BMS_OBCCurrtReq_dt: compu-method=BMS_OBCCurrtReq
    BMS_OBCInvACVoltReq_dt: compu {phys=raw for raw 0..511, 511=BMS_OBCInvACVoltReq_511_Invalid}
    BMS_OBCInvMaxPermPwr_dt: compu {phys=raw*0.01 for raw 0..1023, 1023=BMS_OBCInvMaxPermPwr_1023_Invalid}
    BMS_OBCVoltReq_dt: compu-method=BMS_OBCVoltReq
    BMS_OBCWorkModReq_dt: compu-method=BMS_OBCWorkModReq
    BMS_OperSt_dt: compu-method=BMS_OperSt
    IPB_VehicleSpeed_dt: compu {phys=raw*0.05625 for raw 0..8191, 8191=IPB_VehicleSpeed_8191_Invalid}
    IPB_VehicleSpeedValid_dt: compu {0=IPB_VehicleSpeedValid_0_Invalid, 1=IPB_VehicleSpeedValid_1_Valid}
    TBOX_DSTFlag_dt: compu {0=TBOX_DSTFlag_0_Invalid, 1=TBOX_DSTFlag_1_Valid}
    TBOX_TimeDay_dt: compu {phys=raw for raw 1..31}
    TBOX_TimeFlag_dt: compu-method=TBOX_TimeFlag
    TBOX_TimeHour_dt: compu {phys=raw for raw 0..23}
    TBOX_TimeMinute_dt: compu {phys=raw for raw 0..59}
    TBOX_TimeMonth_dt: compu {phys=raw for raw 1..12}
    TBOX_TimeSecond_dt: compu {phys=raw for raw 0..59}
    TBOX_TimeYear_dt: compu {phys=raw+2000 for raw 0..255}
    TBOX_TimeZone_dt: compu-method=TBOX_TimeZone
    TBOX_TimeZoneMinute_dt: compu {phys=raw for raw 0..59}
    TBOX_TimeZoneNum_dt: compu-method=TBOX_TimeZoneNum
    VDC_ActGearSt_dt: compu-method=VDC_ActGearSt
    VDC_BMSDchaMaxPwr_dt: compu {phys=raw*0.1 for raw 0..127}
    VDC_DCDCEnableCmd_dt: compu-method=VDC_DCDCEnableCmd
    VDC_DCDCMaxCurrtAlld_dt: compu {phys=raw*0.5 for raw 0..1023, 1023=VDC_DCDCMaxCurrtAlld_1023_Invalid}
    VDC_DCDCSetVolt_dt: compu {phys=raw*0.1 for raw 0..254, 255=VDC_DCDCSetVolt_255_Invalid}
    VDC_HVCtrl_Checksum_dt: compu {phys=raw for raw 0..65535}
    VDC_HVCtrl_Counter_dt: compu {phys=raw for raw 0..255}
    VDC_OBCACCurrtMaxPerm_dt: compu {phys=raw for raw 0..100, 127=VDC_OBCACCurrtMaxPerm_127_Invalid}
    VDC_RBAllwdSts_dt: compu-method=VDC_RBAllwdSts
    VDC_RBDCACVoltReq_dt: compu {phys=raw for raw 0..511, 511=VDC_RBDCACVoltReq_511_Invalid}
    VDC_RBEnableSt_dt: compu-method=VDC_RBEnableSt
    VDC_RBMainK1K2Ctrl_dt: compu-method=VDC_RBMainK1K2Ctrl
    VDC_RBMainK3K4Ctrl_dt: compu {0=VDC_RBMainK3K4Ctrl_0_Open, 1=VDC_RBMainK3K4Ctrl_1_Close}
    VDC_RBOBCWorkModReq_dt: compu-method=VDC_RBOBCWorkModReq
    VDC_SysState_Checksum_dt: compu {phys=raw for raw 0..65535}
    VDC_SysState_Counter_dt: compu {phys=raw for raw 0..255}
    VDC_TotalRang_VV01_dt: compu {phys=raw for raw 0..1048575, 1048575=VDC_TotalRang_1048575_Invalid}
    VDC_VehState_Checksum_dt: compu {phys=raw for raw 0..65535}
    VDC_VehState_Counter_dt: compu {phys=raw for raw 0..255}
    VIU_CarMode_dt: compu-method=VIU_CarMode
    VIU_Info_Checksum_VV01_dt: compu {phys=raw for raw 0..65535}
    VIU_Info_Counter_dt: compu {phys=raw for raw 0..255}
    VIU_PowerMode_dt: compu-method=VIU_PowerMode
    VIU_Route_EP_Checksum_dt: compu {phys=raw for raw 0..65535}
    VIU_Route_EP_Counter_dt: compu {phys=raw for raw 0..255}
    VIU_UsageMode_dt: compu-method=VIU_UsageMode
package /DataType/DataTypeSemantics
  compu method CDU_RepeatMessageRequestBit: 0=CDU_RepeatMessageRequestBit_0_Not_Request, 1=CDU_RepeatMessageRequestBit_1_Repeat_Message_Request
  compu method CDU_ActiveWakeupBit: 0=CDU_ActiveWakeupBit_0_Passive_Wakeup, 1=CDU_ActiveWakeupBit_1_Active_Wakeup
  compu method CDU_FirstWakeupReason: 0=CDU_FirstWakeupReason_0_Initial, 1=CDU_FirstWakeupReason_1_Wakeup_HardWire_ON, 2=CDU_FirstWakeupReason_2_NM_Wakeup, 3=CDU_FirstWakeupReason_3_CC_or_CP_Wakeup, 63=CDU_FirstWakeupReason_63_Invalid
  compu method CDU_KL15_Volt: phys=raw*0.1 for raw 0..253, 254=CDU_KL15_Volt_254_Initial, 255=CDU_KL15_Volt_255_Invalid
  compu method CDU_KL30_Volt: phys=raw*0.1 for raw 0..253, 254=CDU_KL30_Volt_254_Initial, 255=CDU_KL30_Volt_255_Invalid
  compu method OBC_ACL2Currt: phys=raw*0.1 for raw 0..1023, 1022=OBC_ACL2Currt_1022_Initial, 1023=OBC_ACL2Currt_1023_Invalid
  compu method OBC_ACL2Volt: phys=raw for raw 0..4095, 4094=OBC_ACL2Volt_4094_Initial, 4095=OBC_ACL2Volt_4095_Invalid
  compu method OBC_ACL3Currt: phys=raw*0.1 for raw 0..1023, 1022=OBC_ACL3Currt_1022_Initial, 1023=OBC_ACL3Currt_1023_Invalid
  compu method OBC_ACL3Volt: phys=raw for raw 0..4095, 4094=OBC_ACL3Volt_4094_Initial, 4095=OBC_ACL3Volt_4095_Invalid
  compu method OBC_ChrgCablePermitCurrt: 0=OBC_ChrgCablePermitCurrt_0_Unknown, 1=OBC_ChrgCablePermitCurrt_1_10A, 2=OBC_ChrgCablePermitCurrt_2_16A, 3=OBC_ChrgCablePermitCurrt_3_32A, 4=OBC_ChrgCablePermitCurrt_4_63A, 5=OBC_ChrgCablePermitCurrt_5_Reserved
  compu method CDU_APS_PortA_Currt{1..3}: phys=raw*0.1-500 for raw 0..16383, 16382=CDU_APS_PortA_Currt{1..3}_16382_Initial, 16383=CDU_APS_PortA_Currt{1..3}_16383_Invalid
  compu method CDU_APS_PortA_U1: phys=raw*0.05 for raw 0..1023, 1022=CDU_APS_PortA_U1_1022_Initial, 1023=CDU_APS_PortA_U1_1023_Invalid
  compu method CDU_APS_PortA_U2: phys=raw*0.05 for raw 0..1023, 1022=CDU_APS_PortA_U2_1022_Initial, 1023=CDU_APS_PortA_U2_1023_Invalid
  compu method CDU_APS_PortB_Currt_DCDC: phys=raw*0.1-500 for raw 0..16383, 16382=CDU_APS_PortB_Currt_DCDC_16382_Initial, 16383=CDU_APS_PortB_Currt_DCDC_16383_Invalid
  compu method CDU_APS_PortB_Currt_Sfty: phys=raw*0.1-500 for raw 0..16383, 16382=CDU_APS_PortB_Currt_Sfty_16382_Initial, 16383=CDU_APS_PortB_Currt_Sfty_16383_Invalid
  compu method CDU_APS_PortB_U1: phys=raw*0.05 for raw 0..1023, 1022=CDU_APS_PortB_U1_1022_Initial, 1023=CDU_APS_PortB_U1_1023_Invalid
  compu method CDU_APS_PortB_U2: phys=raw*0.05 for raw 0..1023, 1022=CDU_APS_PortB_U2_1022_Initial, 1023=CDU_APS_PortB_U2_1023_Invalid
  compu method DCDC_EnergyConvrtDir: 0=DCDC_EnergyConvrtDir_0_Uni_Direction, 1=DCDC_EnergyConvrtDir_1_Bi_Direction
  compu method DCDC_FaultLevel: 0=DCDC_FaultLevel_0_Normal, 1=DCDC_FaultLevel_1_Level1, 2=DCDC_FaultLevel_2_Level2, 3=DCDC_FaultLevel_3_Level3, 4=DCDC_FaultLevel_4_Level4, 5=DCDC_FaultLevel_5_Level5, 6=DCDC_FaultLevel_6_Reseverd
  compu method DCDC_FlowReq: 0=DCDC_FlowReq_0_0, 1=DCDC_FlowReq_1_1, 2=DCDC_FlowReq_2_2, 3=DCDC_FlowReq_3_3, 4=DCDC_FlowReq_4_4, 5=DCDC_FlowReq_5_5, 6=DCDC_FlowReq_6_6, 7=DCDC_FlowReq_7_7, 8=DCDC_FlowReq_8_8, 9=DCDC_FlowReq_9_9, 10=DCDC_FlowReq_10_10, 11=DCDC_FlowReq_11_11, 12=DCDC_FlowReq_12_12, 13=DCDC_FlowReq_13_Reserved
  compu method DCDC_HVIL_48VDCDC_St: 0=DCDC_HVIL_48VDCDC_St_0_Not_ready, 1=DCDC_HVIL_48VDCDC_St_1_Lock, 2=DCDC_HVIL_48VDCDC_St_2_Unlock, 3=DCDC_HVIL_48VDCDC_St_3_HW_Fault
  compu method DCDC_HVIL_Batt_St: 0=DCDC_HVIL_Batt_St_0_Not_ready, 1=DCDC_HVIL_Batt_St_1_Lock, 2=DCDC_HVIL_Batt_St_2_Unlock, 3=DCDC_HVIL_Batt_St_3_HW_Fault
  compu method DCDC_HVIL_EAS_St: 0=DCDC_HVIL_EAS_St_0_Not_ready, 1=DCDC_HVIL_EAS_St_1_Lock, 2=DCDC_HVIL_EAS_St_2_Unlock, 3=DCDC_HVIL_EAS_St_3_HW_Fault
  compu method DCDC_HVIL_MCU_St: 0=DCDC_HVIL_MCU_St_0_Not_ready, 1=DCDC_HVIL_MCU_St_1_Lock, 2=DCDC_HVIL_MCU_St_2_Unlock, 3=DCDC_HVIL_MCU_St_3_HW_Fault
  compu method DCDC_HVIL_PTC_St: 0=DCDC_HVIL_PTC_St_0_Not_ready, 1=DCDC_HVIL_PTC_St_1_Lock, 2=DCDC_HVIL_PTC_St_2_Unlock, 3=DCDC_HVIL_PTC_St_3_HW_Fault
  compu method DCDC_HVIL_PTCR_St: 0=DCDC_HVIL_PTCR_St_0_Not_ready, 1=DCDC_HVIL_PTCR_St_1_Lock, 2=DCDC_HVIL_PTCR_St_2_Unlock, 3=DCDC_HVIL_PTCR_St_3_HW_Fault
  compu method DCDC_NoLoadCurrtFlag: 0=DCDC_NoLoadCurrtFlag_0_Not_ready, 1=DCDC_NoLoadCurrtFlag_1_With_Load, 2=DCDC_NoLoadCurrtFlag_2_Without_Load, 3=DCDC_NoLoadCurrtFlag_3_Reserved
  compu method DCDC_OperSt: 0=DCDC_OperSt_0_Initial, 1=DCDC_OperSt_1_Standby, 2=DCDC_OperSt_2_Work, 3=DCDC_OperSt_3_Fault, 4=DCDC_OperSt_4_Safety, 5=DCDC_OperSt_5_PreSleep(Not_reported_within_100_ms) (DCDC_OperSt_DCDC_OperSt_5_PreSleep_Not_reported_within_100_ms_), 6=DCDC_OperSt_6_Reserved
  compu method DCDC_OutWtrTemp: phys=raw-48 for raw 0..255, 255=DCDC_OutWtrTemp_255_Invalid, 255=DCDC_OutWtrTemp_255_Invalid
  compu method DCDC_PNGSt: 0=DCDC_PNGSt_0_Open, 1=DCDC_PNGSt_1_Close, 2=DCDC_PNGSt_2_Reserved, 3=DCDC_PNGSt_3_Reserved
  compu method DCDC_Oring_APS_Temp: phys=raw-48 for raw 0..253, 254=DCDC_Oring_APS_Temp_254_Initial, 255=DCDC_Oring_APS_Temp_255_Invalid
  compu method OBC_AcIptSts: 0=OBC_AcIptSts_0_AC_power_is_normal, 1=OBC_AcIptSts_1_No_electricity_or_Undervoltage, 2=OBC_AcIptSts_2_Ac_power_is_blackout, 3=OBC_AcIptSts_3_Overvoltage
  compu method OBC_ChrgGunCCSts: 0=OBC_ChrgGunCCSts_0_Invalid_CC_Res, 1=OBC_ChrgGunCCSts_1_Not_Connected, 2=OBC_ChrgGunCCSts_2_Half_Connected, 3=OBC_ChrgGunCCSts_3_ACChrg_Full_Connected, 4=OBC_ChrgGunCCSts_4_V2L_Cun_Full_Connected, 5=OBC_ChrgGunCCSts_5_V2V_Gun_Full_Connected, 6=OBC_ChrgGunCCSts_6_Unknown(Full_Connected) (OBC_ChrgGunCCSts_OBC_ChrgGunCCSts_6_Unknown_Full_Connected_), 7=OBC_ChrgGunCCSts_7_Reserved
  compu method OBC_CPFreqSts: 0=OBC_CPFreqSts_0_CP_is_within_500Hz_to1500Hz, 1=OBC_CPFreqSts_1_CP_is_beyond_500Hz_to_1500Hz
  compu method OBC_CPSts: 0=OBC_CPSts_0_no_CP_signal, 1=OBC_CPSts_1_CP_is_12V_high_level, 2=OBC_CPSts_2_CP_is_9V_high_level, 3=OBC_CPSts_3_CP_is_9V_PWM, 4=OBC_CPSts_4_CP_is_6V_PWM, 5=OBC_CPSts_5_CP_is_6V_high_level, 6=OBC_CPSts_6_CP_is_12V_PWM, 7=OBC_CPSts_7_CP_signal_is_abnormal
  compu method OBC_CPValidSt: 0=OBC_CPValidSt_0_Not_Connected, 1=OBC_CPValidSt_1_Valid, 2=OBC_CPValidSt_2_Invalid, 3=OBC_CPValidSt_3_Reserved
  compu method OBC_DischrgLoadForm: 0=OBC_DischrgLoadForm_0_Unknown, 1=OBC_DischrgLoadForm_1_Non-intelligent_load (OBC_DischrgLoadForm_OBC_DischrgLoadForm_1_Non_intelligent_load), 2=OBC_DischrgLoadForm_2_Intelligent_loads, 3=OBC_DischrgLoadForm_3_Reserved
  compu method OBC_FastChargeRelayNegSts: 0=OBC_FastChargeRelayNegSts_0_OPEN, 1=OBC_FastChargeRelayNegSts_1_CLOSE, 2=OBC_FastChargeRelayNegSts_2_FAULT, 3=OBC_FastChargeRelayNegSts_3_Reserved
  compu method OBC_FastChargeRelayPosSts: 0=OBC_FastChargeRelayPosSts_0_OPEN, 1=OBC_FastChargeRelayPosSts_1_CLOSE, 2=OBC_FastChargeRelayPosSts_2_FAULT, 3=OBC_FastChargeRelayPosSts_3_Reserved
  compu method OBC_FaultLevel: 0=OBC_FaultLevel_0_Normal, 1=OBC_FaultLevel_1_Level1, 2=OBC_FaultLevel_2_Level2, 3=OBC_FaultLevel_3_Level3, 4=OBC_FaultLevel_4_Level4, 5=OBC_FaultLevel_5_Level5, 6=OBC_FaultLevel_6_Level6_EVR, 7=OBC_FaultLevel_7_Reseverd
  compu method OBC_HVIL_AC_St: 0=OBC_HVIL_AC_St_0_Not_ready, 1=OBC_HVIL_AC_St_1_Lock, 2=OBC_HVIL_AC_St_2_Unlock, 3=OBC_HVIL_AC_St_3_HW_Fault
  compu method OBC_HVIL_DC_St: 0=OBC_HVIL_DC_St_0_Not_ready, 1=OBC_HVIL_DC_St_1_Lock, 2=OBC_HVIL_DC_St_2_Unlock, 3=OBC_HVIL_DC_St_3_HW_Fault
  compu method OBC_OperSt: 0=OBC_OperSt_0_Initial, 1=OBC_OperSt_1_Standby, 2=OBC_OperSt_2_AC_Charge, 3=OBC_OperSt_3_Bat_Heat, 4=OBC_OperSt_4_AC_Discharge, 5=OBC_OperSt_5_Fault, 6=OBC_OperSt_6_Safety, 7=OBC_OperSt_7_PreSleep, 8=OBC_OperSt_8_Reserved
  compu method OBC_RatedPwrLevel: 0=OBC_RatedPwrLevel_0_9.9kW (OBC_RatedPwrLevel_OBC_RatedPwrLevel_0_9_9kW), 1=OBC_RatedPwrLevel_1_reserved, 2=OBC_RatedPwrLevel_2_3.3kW (OBC_RatedPwrLevel_OBC_RatedPwrLevel_2_3_3kW), 3=OBC_RatedPwrLevel_3_6.6kW (OBC_RatedPwrLevel_OBC_RatedPwrLevel_3_6_6kW), 4=OBC_RatedPwrLevel_4_reserved
  compu method OBC_WorkMode: 0=OBC_WorkMode_0_No_mode, 1=OBC_WorkMode_1_DcChargeMode, 2=OBC_WorkMode_2_AcChargeMode, 3=OBC_WorkMode_3_BatteryWarm, 4=OBC_WorkMode_4_InverterMode, 5=OBC_WorkMode_5_Reserved
  compu method OBC_DisWorkMode: 0=OBC_DisWorkMode_0_No_mode, 1=OBC_DisWorkMode_1_DCACMode, 2=OBC_DisWorkMode_2_Reserved
  compu method OBC_EnergyConvrtDir: 0=OBC_EnergyConvrtDir_0_Uni_Direction, 1=OBC_EnergyConvrtDir_1_Bi_Direction
  compu method OBC_RBMainK{1..4}Sts: 0=OBC_RBMainK{1..4}Sts_0_Init, 1=OBC_RBMainK{1..4}Sts_1_Open, 2=OBC_RBMainK{1..4}Sts_2_Close, 3=OBC_RBMainK{1..4}Sts_3_Fault
  compu method BMS_DCChrgConnectSt: 0=BMS_DCChrgConnectSt_0_Disconnect, 1=BMS_DCChrgConnectSt_1_Charge_gun_fully_connected, 2=BMS_DCChrgConnectSt_2_The_connection_is_abnormal. (BMS_DCChrgConnectSt_BMS_DCChrgConnectSt_2_The_connection_is_abnormal_), 3=BMS_DCChrgConnectSt_3_Converter_connection, 4=BMS_DCChrgConnectSt_4_discharge_gun_connection
  compu method BMS_OBCCurrtReq: phys=raw*0.1 for raw 0..4095, 4094=BMS_OBCCurrtReq_4094_Initial_Value, 4095=BMS_OBCCurrtReq_4095_Invalid
  compu method BMS_OBCVoltReq: phys=raw for raw 0..1000, 1022=BMS_OBCVoltReq_1022_Initial_Value, 1023=BMS_OBCVoltReq_1023_Invalid
  compu method BMS_OBCWorkModReq: 0=BMS_OBCWorkModReq_0_No_mode, 1=BMS_OBCWorkModReq_1_DcChargeMode(Reserved) (BMS_OBCWorkModReq_BMS_OBCWorkModReq_1_DcChargeMode_Reserved_), 2=BMS_OBCWorkModReq_2_AcChargeMode, 3=BMS_OBCWorkModReq_3_BatteryWarm, 4=BMS_OBCWorkModReq_4_InverterMode, 5=BMS_OBCWorkModReq_5_Reserved
  compu method BMS_ActvHvOnReq: 0=BMS_ActvHvOnReq_0_No_Request, 1=BMS_ActvHvOnReq_1_Charge, 2=BMS_ActvHvOnReq_2_Low_Temp_Heat, 3=BMS_ActvHvOnReq_3_Charge&Low_Temp_Heat (BMS_ActvHvOnReq_BMS_ActvHvOnReq_3_Charge_Low_Temp_Heat)
  compu method BMS_BattVolt_U7: phys=raw*0.1 for raw 0..10000, 16382=BMS_BattVolt_U7_16382_Initial_Value, 16383=BMS_BattVolt_U7_16383_Invalid
  compu method VDC_DCDCEnableCmd: 0=VDC_DCDCEnableCmd_0_Disable, 1=VDC_DCDCEnableCmd_1_Enable, 2=VDC_DCDCEnableCmd_2_Reserved
  compu method VDC_RBAllwdSts: 0=VDC_RBAllwdSts_0_Initial, 1=VDC_RBAllwdSts_1_Allowed, 2=VDC_RBAllwdSts_2_Not_Allowed(Normal), 3=VDC_RBAllwdSts_3_Not_Allowed(Fault), 4=VDC_RBAllwdSts_4_Reserved, 5=VDC_RBAllwdSts_5_Reserved, 6=VDC_RBAllwdSts_6_Reserved, 7=VDC_RBAllwdSts_7_Reserved
  compu method VDC_RBEnableSt: 0=VDC_RBEnableSt_0_Invalid, 1=VDC_RBEnableSt_1_Valid, 2=VDC_RBEnableSt_2_Fault
  compu method VDC_RBMainK1K2Ctrl: 0=VDC_RBMainK1K2Ctrl_0_Init, 1=VDC_RBMainK1K2Ctrl_1_Open, 2=VDC_RBMainK1K2Ctrl_2_Close
  compu method VDC_RBOBCWorkModReq: phys=raw for raw 0..15, 0=VDC_RBOBCWorkModReq_0_No_mode, 1=VDC_RBOBCWorkModReq_1_DCACMode, 2=VDC_RBOBCWorkModReq_2_Reserved
  compu method VDC_ActGearSt: 0=VDC_ActGearSt_0_Undefined, 1=VDC_ActGearSt_1_P, 2=VDC_ActGearSt_2_R, 3=VDC_ActGearSt_3_N, 4=VDC_ActGearSt_4_D, 5=VDC_ActGearSt_5_Reserved, 6=VDC_ActGearSt_6_Reserved
  compu method TBOX_TimeFlag: 0=TBOX_TimeFlag_0_Invalid, 1=TBOX_TimeFlag_1_Valid, 2=TBOX_TimeFlag_2_With_Offset(Reserved) (TBOX_TimeFlag_TBOX_TimeFlag_2_With_Offset_Reserved_), 3=TBOX_TimeFlag_3_Reserved
  compu method TBOX_TimeZone: 0=TBOX_TimeZone_0_Initial, 1=TBOX_TimeZone_1_East, 2=TBOX_TimeZone_2_West, 3=TBOX_TimeZone_3_Reserved
  compu method TBOX_TimeZoneNum: 0=TBOX_TimeZoneNum_0_TimeZone_0, 1=TBOX_TimeZoneNum_1_TimeZone_1, 2=TBOX_TimeZoneNum_2_TimeZone_2, 3=TBOX_TimeZoneNum_3_TimeZone_3, 4=TBOX_TimeZoneNum_4_TimeZone_4, 5=TBOX_TimeZoneNum_5_TimeZone_5, 6=TBOX_TimeZoneNum_6_TimeZone_6, 7=TBOX_TimeZoneNum_7_TimeZone_7, 8=TBOX_TimeZoneNum_8_TimeZone_8, 9=TBOX_TimeZoneNum_9_TimeZone_9, 10=TBOX_TimeZoneNum_10_TimeZone_10, 11=TBOX_TimeZoneNum_11_TimeZone_11, 12=TBOX_TimeZoneNum_12_TimeZone_12, 13=TBOX_TimeZoneNum_13_TimeZone_13, 14=TBOX_TimeZoneNum_14_TimeZone_14, 15=TBOX_TimeZoneNum_15_Reserved
  compu method VIU_CarMode: 0=VIU_CarMode_0_Factory, 1=VIU_CarMode_1_Transport, 2=VIU_CarMode_2_Dynotest, 3=VIU_CarMode_3_Normal, 4=VIU_CarMode_4_ExhibitionInDoor, 5=VIU_CarMode_5_ExhibitionOutDoor, 6=VIU_CarMode_6_reserved, 14=VIU_CarMode_14_Initial, 15=VIU_CarMode_15_Invalid
  compu method VIU_UsageMode: 0=VIU_UsageMode_0_Abandoned, 1=VIU_UsageMode_1_Inactive, 2=VIU_UsageMode_2_Convenience, 3=VIU_UsageMode_3_Driving, 4=VIU_UsageMode_4_OTA_Updating, 5=VIU_UsageMode_5_Remote, 6=VIU_UsageMode_6_RemoteDriving, 7=VIU_UsageMode_7_reserved, 15=VIU_UsageMode_15_Invalid
  compu method VIU_PowerMode: 0=VIU_PowerMode_0_OFF, 1=VIU_PowerMode_1_ON, 2=VIU_PowerMode_2_Reserved, 3=VIU_PowerMode_3_Invalid
  compu method BMS_MainNegSt: 0=BMS_MainNegSt_0_Open, 1=BMS_MainNegSt_1_Close, 2=BMS_MainNegSt_2_Fault
  compu method BMS_MainPosSt: 0=BMS_MainPosSt_0_Open, 1=BMS_MainPosSt_1_Close, 2=BMS_MainPosSt_2_Fault
  compu method BMS_MainPreChrgSt: 0=BMS_MainPreChrgSt_0_Open, 1=BMS_MainPreChrgSt_1_Close, 2=BMS_MainPreChrgSt_2_Fault
  compu method BMS_OperSt: 0=BMS_OperSt_0_Initial_初始化 (BMS_OperSt_BMS_OperSt_0_Initial_), 1=BMS_OperSt_1_Standby_待机 (BMS_OperSt_BMS_OperSt_1_Standby_), 2=BMS_OperSt_2_Precharge_预充 (BMS_OperSt_BMS_OperSt_2_Precharge_), 3=BMS_OperSt_3_HVON_电池包高压Ready (BMS_OperSt_BMS_OperSt_3_HVON_Ready), 4=BMS_OperSt_4_HVOff_高压下电 (BMS_OperSt_BMS_OperSt_4_HVOff_), 5=BMS_OperSt_5_Polling_巡检不上高压 (BMS_OperSt_BMS_OperSt_5_Polling_), 6=BMS_OperSt_6_AfterRun, 7=BMS_OperSt_7_HVFault_无法上高压或故障下高压状态 (BMS_OperSt_BMS_OperSt_7_HVFault_), 8=BMS_OperSt_8_LinkHVON_桩端高压Ready (BMS_OperSt_BMS_OperSt_8_LinkHVON_Ready), 9=BMS_OperSt_9_Reserved
package /DataType/DataTypeSemantics/SwBaseTypes
  14 x base type, all with category=FIXED_LENGTH, base-type-encoding=NONE:
    UINT1: base-type-size=1
    UINT6: base-type-size=6
    UINT12: base-type-size=12
    UINT5: base-type-size=5
    UINT3: base-type-size=3
    UINT10: base-type-size=10
    UINT11: base-type-size=11
    UINT9: base-type-size=9
    UINT4: base-type-size=4
    UINT14: base-type-size=14
    UINT2: base-type-size=2
    UINT7: base-type-size=7
    UINT13: base-type-size=13
    UINT20: base-type-size=20
package /ComponentType
  composition sw component type RootComposition
    component CCU_CSWC_proto: type=CCU_CSWC
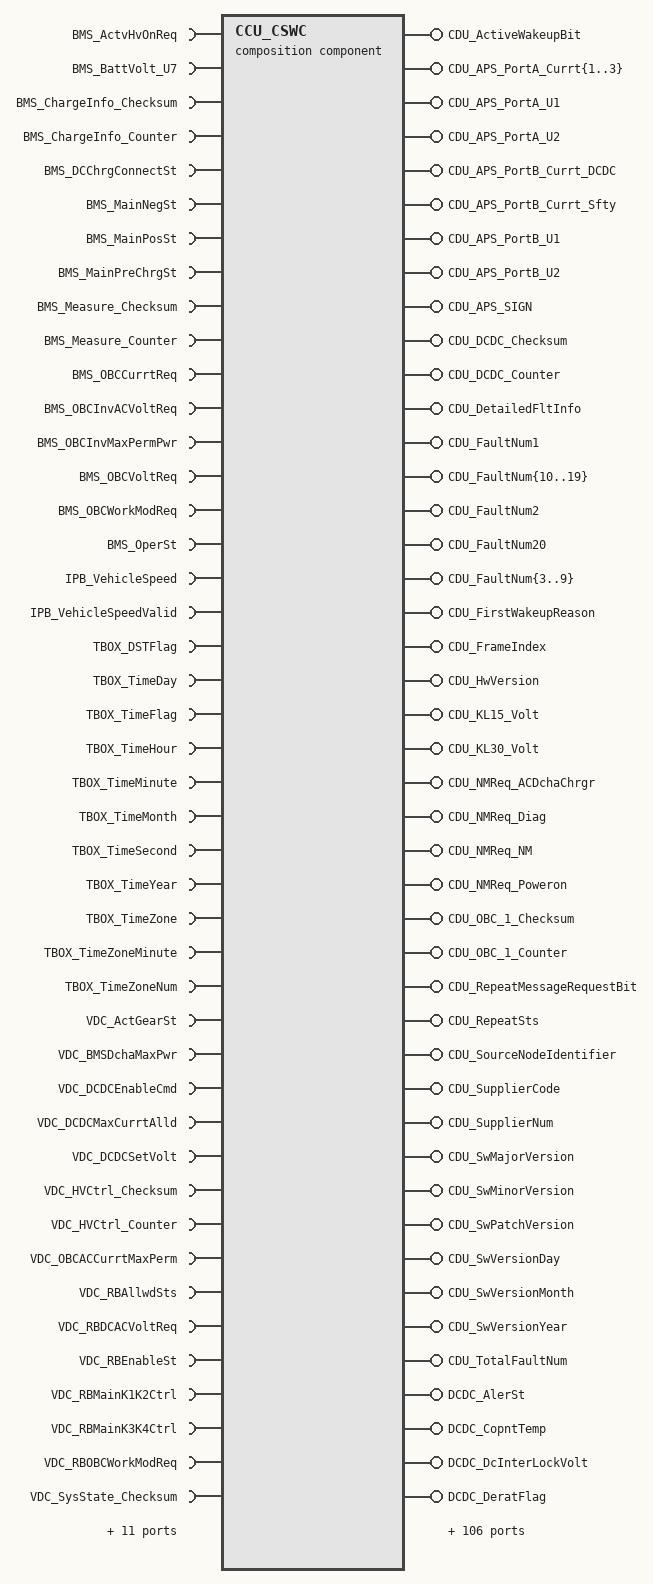
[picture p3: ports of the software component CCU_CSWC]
  composition sw component type CCU_CSWC: data-type-mapping=DataTypeMappingSet
    198 x provide port:
      CDU_ActiveWakeupBit: provided-interface=CDU_ActiveWakeupBit
      CDU_APS_PortA_Currt{1..3}: provided-interface=CDU_APS_PortA_Currt{1..3}
      CDU_APS_PortA_U1: provided-interface=CDU_APS_PortA_U1
      CDU_APS_PortA_U2: provided-interface=CDU_APS_PortA_U2
      CDU_APS_PortB_Currt_DCDC: provided-interface=CDU_APS_PortB_Currt_DCDC
      CDU_APS_PortB_Currt_Sfty: provided-interface=CDU_APS_PortB_Currt_Sfty
      CDU_APS_PortB_U1: provided-interface=CDU_APS_PortB_U1
      CDU_APS_PortB_U2: provided-interface=CDU_APS_PortB_U2
      CDU_APS_SIGN: provided-interface=CDU_APS_SIGN
      CDU_DCDC_Checksum: provided-interface=CDU_DCDC_Checksum
      CDU_DCDC_Counter: provided-interface=CDU_DCDC_Counter
      CDU_DetailedFltInfo: provided-interface=CDU_DetailedFltInfo
      CDU_FaultNum1: provided-interface=CDU_FaultNum1
      CDU_FaultNum{10..19}: provided-interface=CDU_FaultNum{10..19}
      CDU_FaultNum2: provided-interface=CDU_FaultNum2
      CDU_FaultNum20: provided-interface=CDU_FaultNum20
      CDU_FaultNum{3..9}: provided-interface=CDU_FaultNum{3..9}
      CDU_FirstWakeupReason: provided-interface=CDU_FirstWakeupReason
      CDU_FrameIndex: provided-interface=CDU_FrameIndex
      CDU_HwVersion: provided-interface=CDU_HwVersion
      CDU_KL15_Volt: provided-interface=CDU_KL15_Volt
      CDU_KL30_Volt: provided-interface=CDU_KL30_Volt
      CDU_NMReq_ACDchaChrgr: provided-interface=CDU_NMReq_ACDchaChrgr
      CDU_NMReq_Diag: provided-interface=CDU_NMReq_Diag
      CDU_NMReq_NM: provided-interface=CDU_NMReq_NM
      CDU_NMReq_Poweron: provided-interface=CDU_NMReq_Poweron
      CDU_OBC_1_Checksum: provided-interface=CDU_OBC_1_Checksum
      CDU_OBC_1_Counter: provided-interface=CDU_OBC_1_Counter
      CDU_RepeatMessageRequestBit: provided-interface=CDU_RepeatMessageRequestBit
      CDU_RepeatSts: provided-interface=CDU_RepeatSts
      CDU_SourceNodeIdentifier: provided-interface=CDU_SourceNodeIdentifier
      CDU_SupplierCode: provided-interface=CDU_SupplierCode
      CDU_SupplierNum: provided-interface=CDU_SupplierNum
      CDU_SwMajorVersion: provided-interface=CDU_SwMajorVersion
      CDU_SwMinorVersion: provided-interface=CDU_SwMinorVersion
      CDU_SwPatchVersion: provided-interface=CDU_SwPatchVersion
      CDU_SwVersionDay: provided-interface=CDU_SwVersionDay
      CDU_SwVersionMonth: provided-interface=CDU_SwVersionMonth
      CDU_SwVersionYear: provided-interface=CDU_SwVersionYear
      CDU_TotalFaultNum: provided-interface=CDU_TotalFaultNum
      DCDC_AlerSt: provided-interface=DCDC_AlerSt
      DCDC_CopntTemp: provided-interface=DCDC_CopntTemp
      DCDC_DcInterLockVolt: provided-interface=DCDC_DcInterLockVolt
      DCDC_DeratFlag: provided-interface=DCDC_DeratFlag
      DCDC_DeratReason1: provided-interface=DCDC_DeratReason1
      DCDC_DeratReason{10..12}: provided-interface=DCDC_DeratReason{10..12}
      DCDC_DeratReason{2..9}: provided-interface=DCDC_DeratReason{2..9}
      DCDC_EnergyConvrtDir: provided-interface=DCDC_EnergyConvrtDir
      DCDC_FaultLevel: provided-interface=DCDC_FaultLevel
      DCDC_FaultLightReq: provided-interface=DCDC_FaultLightReq
      DCDC_FlowReq: provided-interface=DCDC_FlowReq
      DCDC_HVIL_48VDCDC_St: provided-interface=DCDC_HVIL_48VDCDC_St
      DCDC_HVIL_Batt_St: provided-interface=DCDC_HVIL_Batt_St
      DCDC_HVIL_EAS_St: provided-interface=DCDC_HVIL_EAS_St
      DCDC_HVIL_MCU_St: provided-interface=DCDC_HVIL_MCU_St
      DCDC_HVIL_PTC_St: provided-interface=DCDC_HVIL_PTC_St
      DCDC_HVIL_PTCR_St: provided-interface=DCDC_HVIL_PTCR_St
      DCDC_InpWtrTemp: provided-interface=DCDC_InpWtrTemp
      DCDC_IptCurrt: provided-interface=DCDC_IptCurrt
      DCDC_IptVolt: provided-interface=DCDC_IptVolt
      DCDC_LoopOut: provided-interface=DCDC_LoopOut
      DCDC_LvSidePwr: provided-interface=DCDC_LvSidePwr
      DCDC_MaxOptPwr: provided-interface=DCDC_MaxOptPwr
      DCDC_McuInterLockVolt: provided-interface=DCDC_McuInterLockVolt
      DCDC_NoLoadCurrtFlag: provided-interface=DCDC_NoLoadCurrtFlag
      DCDC_OperSt: provided-interface=DCDC_OperSt
      DCDC_OptCurrt: provided-interface=DCDC_OptCurrt
      DCDC_OptVolt: provided-interface=DCDC_OptVolt
      DCDC_Oring_APS_Temp: provided-interface=DCDC_Oring_APS_Temp
      DCDC_OutWtrTemp: provided-interface=DCDC_OutWtrTemp
      DCDC_OverTemp: provided-interface=DCDC_OverTemp
      DCDC_PeakPwrTi: provided-interface=DCDC_PeakPwrTi
      DCDC_PNGSt: provided-interface=DCDC_PNGSt
      DCDC_PtcInterLockVolt: provided-interface=DCDC_PtcInterLockVolt
      DCDC_SwMajorVersion: provided-interface=DCDC_SwMajorVersion
      DCDC_SwMinorVersion: provided-interface=DCDC_SwMinorVersion
      DCDC_SwPatchVersion: provided-interface=DCDC_SwPatchVersion
      DCDC_SwVersionDay: provided-interface=DCDC_SwVersionDay
      DCDC_SwVersionMonth: provided-interface=DCDC_SwVersionMonth
      DCDC_SwVersionYear: provided-interface=DCDC_SwVersionYear
      OBC_ACInpFrq: provided-interface=OBC_ACInpFrq
      OBC_AcIptSts: provided-interface=OBC_AcIptSts
      OBC_AcIptType: provided-interface=OBC_AcIptType
      OBC_ACL1Currt: provided-interface=OBC_ACL1Currt
      OBC_ACL1Volt: provided-interface=OBC_ACL1Volt
      OBC_ACL2Currt: provided-interface=OBC_ACL2Currt
      OBC_ACL2Volt: provided-interface=OBC_ACL2Volt
      OBC_ACL3Currt: provided-interface=OBC_ACL3Currt
      OBC_ACL3Volt: provided-interface=OBC_ACL3Volt
      OBC_AcLineImpedance: provided-interface=OBC_AcLineImpedance
      OBC_ACPileMaxCurrt: provided-interface=OBC_ACPileMaxCurrt
      OBC_ACPwr: provided-interface=OBC_ACPwr
      OBC_BusCapacity: provided-interface=OBC_BusCapacity
      OBC_CCRes: provided-interface=OBC_CCRes
      OBC_ChrgCablePermitCurrt: provided-interface=OBC_ChrgCablePermitCurrt
      OBC_ChrgDischrgStep: provided-interface=OBC_ChrgDischrgStep
      OBC_ChrgEndNum: provided-interface=OBC_ChrgEndNum
      OBC_ChrgGunCCSts: provided-interface=OBC_ChrgGunCCSts
      OBC_ChrgOptMaxCurrt: provided-interface=OBC_ChrgOptMaxCurrt
      OBC_ChrgOptMaxPwr: provided-interface=OBC_ChrgOptMaxPwr
      OBC_ChrgOptMaxVolt: provided-interface=OBC_ChrgOptMaxVolt
      OBC_ChrgOptMinVolt: provided-interface=OBC_ChrgOptMinVolt
      OBC_CopntTemp: provided-interface=OBC_CopntTemp
      OBC_CPDuty: provided-interface=OBC_CPDuty
      OBC_CPFreqSts: provided-interface=OBC_CPFreqSts
      OBC_CPFrq: provided-interface=OBC_CPFrq
      OBC_CPOutpDuty: provided-interface=OBC_CPOutpDuty
      OBC_CPOutpVolt: provided-interface=OBC_CPOutpVolt
      OBC_CPSts: provided-interface=OBC_CPSts
      OBC_CPValidSt: provided-interface=OBC_CPValidSt
      OBC_CPVolt: provided-interface=OBC_CPVolt
      OBC_DCChrgMod_LimCurrt: provided-interface=OBC_DCChrgMod_LimCurrt
      OBC_DCCurrt: provided-interface=OBC_DCCurrt
      OBC_DchaEndNum: provided-interface=OBC_DchaEndNum
      OBC_DCVolt: provided-interface=OBC_DCVolt
      OBC_DeratFlag: provided-interface=OBC_DeratFlag
      OBC_DeratReason1: provided-interface=OBC_DeratReason1
      OBC_DeratReason{10..19}: provided-interface=OBC_DeratReason{10..19}
      OBC_DeratReason2: provided-interface=OBC_DeratReason2
      OBC_DeratReason{20..24}: provided-interface=OBC_DeratReason{20..24}
      OBC_DeratReason{3..9}: provided-interface=OBC_DeratReason{3..9}
      OBC_DischrgLoadForm: provided-interface=OBC_DischrgLoadForm
      OBC_DischrgOptMaxPwr: provided-interface=OBC_DischrgOptMaxPwr
      OBC_DisWorkMode: provided-interface=OBC_DisWorkMode
      OBC_EnergyConvrtDir: provided-interface=OBC_EnergyConvrtDir
      OBC_FastChargeRelayNegSts: provided-interface=OBC_FastChargeRelayNegSts
      OBC_FastChargeRelayPosSts: provided-interface=OBC_FastChargeRelayPosSts
      OBC_FastChrgRelayNeg_Extd_U: provided-interface=OBC_FastChrgRelayNeg_Extd_U
      OBC_FastChrgRelayPos_Extd_U: provided-interface=OBC_FastChrgRelayPos_Extd_U
      OBC_FaultLevel: provided-interface=OBC_FaultLevel
      OBC_FaultLightReq: provided-interface=OBC_FaultLightReq
      OBC_HVIL_AC_St: provided-interface=OBC_HVIL_AC_St
      OBC_HVIL_DC_St: provided-interface=OBC_HVIL_DC_St
      OBC_InsulationR: provided-interface=OBC_InsulationR
      OBC_Ithd: provided-interface=OBC_Ithd
      OBC_OperSt: provided-interface=OBC_OperSt
      OBC_RatedPwrLevel: provided-interface=OBC_RatedPwrLevel
      OBC_RBCurrt: provided-interface=OBC_RBCurrt
      OBC_RBMainK{1..4}Sts: provided-interface=OBC_RBMainK{1..4}Sts
      OBC_S1Sts: provided-interface=OBC_S1Sts
      OBC_S2Sts: provided-interface=OBC_S2Sts
      OBC_S4Sts: provided-interface=OBC_S4Sts
      OBC_SwMajorVersion: provided-interface=OBC_SwMajorVersion
      OBC_SwMinorVersion: provided-interface=OBC_SwMinorVersion
      OBC_SwPatchVersion: provided-interface=OBC_SwPatchVersion
      OBC_SwVersionDay: provided-interface=OBC_SwVersionDay
      OBC_SwVersionMonth: provided-interface=OBC_SwVersionMonth
      OBC_SwVersionYear: provided-interface=OBC_SwVersionYear
      OBC_Uthd: provided-interface=OBC_Uthd
      OBC_WorkMode: provided-interface=OBC_WorkMode
    55 x require port:
      BMS_ActvHvOnReq: required-interface=BMS_ActvHvOnReq
      BMS_BattVolt_U7: required-interface=BMS_BattVolt_U7
      BMS_ChargeInfo_Checksum: required-interface=BMS_ChargeInfo_Checksum
      BMS_ChargeInfo_Counter: required-interface=BMS_ChargeInfo_Counter
      BMS_DCChrgConnectSt: required-interface=BMS_DCChrgConnectSt
      BMS_MainNegSt: required-interface=BMS_MainNegSt
      BMS_MainPosSt: required-interface=BMS_MainPosSt
      BMS_MainPreChrgSt: required-interface=BMS_MainPreChrgSt
      BMS_Measure_Checksum: required-interface=BMS_Measure_Checksum
      BMS_Measure_Counter: required-interface=BMS_Measure_Counter
      BMS_OBCCurrtReq: required-interface=BMS_OBCCurrtReq
      BMS_OBCInvACVoltReq: required-interface=BMS_OBCInvACVoltReq
      BMS_OBCInvMaxPermPwr: required-interface=BMS_OBCInvMaxPermPwr
      BMS_OBCVoltReq: required-interface=BMS_OBCVoltReq
      BMS_OBCWorkModReq: required-interface=BMS_OBCWorkModReq
      BMS_OperSt: required-interface=BMS_OperSt
      IPB_VehicleSpeed: required-interface=IPB_VehicleSpeed
      IPB_VehicleSpeedValid: required-interface=IPB_VehicleSpeedValid
      TBOX_DSTFlag: required-interface=TBOX_DSTFlag
      TBOX_TimeDay: required-interface=TBOX_TimeDay
      TBOX_TimeFlag: required-interface=TBOX_TimeFlag
      TBOX_TimeHour: required-interface=TBOX_TimeHour
      TBOX_TimeMinute: required-interface=TBOX_TimeMinute
      TBOX_TimeMonth: required-interface=TBOX_TimeMonth
      TBOX_TimeSecond: required-interface=TBOX_TimeSecond
      TBOX_TimeYear: required-interface=TBOX_TimeYear
      TBOX_TimeZone: required-interface=TBOX_TimeZone
      TBOX_TimeZoneMinute: required-interface=TBOX_TimeZoneMinute
      TBOX_TimeZoneNum: required-interface=TBOX_TimeZoneNum
      VDC_ActGearSt: required-interface=VDC_ActGearSt
      VDC_BMSDchaMaxPwr: required-interface=VDC_BMSDchaMaxPwr
      VDC_DCDCEnableCmd: required-interface=VDC_DCDCEnableCmd
      VDC_DCDCMaxCurrtAlld: required-interface=VDC_DCDCMaxCurrtAlld
      VDC_DCDCSetVolt: required-interface=VDC_DCDCSetVolt
      VDC_HVCtrl_Checksum: required-interface=VDC_HVCtrl_Checksum
      VDC_HVCtrl_Counter: required-interface=VDC_HVCtrl_Counter
      VDC_OBCACCurrtMaxPerm: required-interface=VDC_OBCACCurrtMaxPerm
      VDC_RBAllwdSts: required-interface=VDC_RBAllwdSts
      VDC_RBDCACVoltReq: required-interface=VDC_RBDCACVoltReq
      VDC_RBEnableSt: required-interface=VDC_RBEnableSt
      VDC_RBMainK1K2Ctrl: required-interface=VDC_RBMainK1K2Ctrl
      VDC_RBMainK3K4Ctrl: required-interface=VDC_RBMainK3K4Ctrl
      VDC_RBOBCWorkModReq: required-interface=VDC_RBOBCWorkModReq
      VDC_SysState_Checksum: required-interface=VDC_SysState_Checksum
      VDC_SysState_Counter: required-interface=VDC_SysState_Counter
      VDC_TotalRang_VV01: required-interface=VDC_TotalRang_VV01
      VDC_VehState_Checksum: required-interface=VDC_VehState_Checksum
      VDC_VehState_Counter: required-interface=VDC_VehState_Counter
      VIU_CarMode: required-interface=VIU_CarMode
      VIU_Info_Checksum_VV01: required-interface=VIU_Info_Checksum_VV01
      VIU_Info_Counter: required-interface=VIU_Info_Counter
      VIU_PowerMode: required-interface=VIU_PowerMode
      VIU_Route_EP_Checksum: required-interface=VIU_Route_EP_Checksum
      VIU_Route_EP_Counter: required-interface=VIU_Route_EP_Counter
      VIU_UsageMode: required-interface=VIU_UsageMode
    component CCU_proto: type=CCU_SWC
    delegate CCU_proto.CDU_ActiveWakeupBit <-> outer port CCU_CSWC/CDU_ActiveWakeupBit
    delegate CCU_proto.CDU_APS_PortA_Currt{1..3} <-> outer port CCU_CSWC/CDU_APS_PortA_Currt{1..3}
    delegate CCU_proto.CDU_APS_PortA_U1 <-> outer port CCU_CSWC/CDU_APS_PortA_U1
    delegate CCU_proto.CDU_APS_PortA_U2 <-> outer port CCU_CSWC/CDU_APS_PortA_U2
    delegate CCU_proto.CDU_APS_PortB_Currt_DCDC <-> outer port CCU_CSWC/CDU_APS_PortB_Currt_DCDC
    delegate CCU_proto.CDU_APS_PortB_Currt_Sfty <-> outer port CCU_CSWC/CDU_APS_PortB_Currt_Sfty
    delegate CCU_proto.CDU_APS_PortB_U1 <-> outer port CCU_CSWC/CDU_APS_PortB_U1
    delegate CCU_proto.CDU_APS_PortB_U2 <-> outer port CCU_CSWC/CDU_APS_PortB_U2
    delegate CCU_proto.CDU_APS_SIGN <-> outer port CCU_CSWC/CDU_APS_SIGN
    delegate CCU_proto.CDU_DCDC_Checksum <-> outer port CCU_CSWC/CDU_DCDC_Checksum
    delegate CCU_proto.CDU_DCDC_Counter <-> outer port CCU_CSWC/CDU_DCDC_Counter
    delegate CCU_proto.CDU_DetailedFltInfo <-> outer port CCU_CSWC/CDU_DetailedFltInfo
    delegate CCU_proto.CDU_FaultNum1 <-> outer port CCU_CSWC/CDU_FaultNum1
    delegate CCU_proto.CDU_FaultNum{10..19} <-> outer port CCU_CSWC/CDU_FaultNum{10..19}
    delegate CCU_proto.CDU_FaultNum2 <-> outer port CCU_CSWC/CDU_FaultNum2
    delegate CCU_proto.CDU_FaultNum20 <-> outer port CCU_CSWC/CDU_FaultNum20
    delegate CCU_proto.CDU_FaultNum{3..9} <-> outer port CCU_CSWC/CDU_FaultNum{3..9}
    delegate CCU_proto.CDU_FirstWakeupReason <-> outer port CCU_CSWC/CDU_FirstWakeupReason
    delegate CCU_proto.CDU_FrameIndex <-> outer port CCU_CSWC/CDU_FrameIndex
    delegate CCU_proto.CDU_HwVersion <-> outer port CCU_CSWC/CDU_HwVersion
    delegate CCU_proto.CDU_KL15_Volt <-> outer port CCU_CSWC/CDU_KL15_Volt
    delegate CCU_proto.CDU_KL30_Volt <-> outer port CCU_CSWC/CDU_KL30_Volt
    delegate CCU_proto.CDU_NMReq_ACDchaChrgr <-> outer port CCU_CSWC/CDU_NMReq_ACDchaChrgr
    delegate CCU_proto.CDU_NMReq_Diag <-> outer port CCU_CSWC/CDU_NMReq_Diag
    delegate CCU_proto.CDU_NMReq_NM <-> outer port CCU_CSWC/CDU_NMReq_NM
    delegate CCU_proto.CDU_NMReq_Poweron <-> outer port CCU_CSWC/CDU_NMReq_Poweron
    delegate CCU_proto.CDU_OBC_1_Checksum <-> outer port CCU_CSWC/CDU_OBC_1_Checksum
    delegate CCU_proto.CDU_OBC_1_Counter <-> outer port CCU_CSWC/CDU_OBC_1_Counter
    delegate CCU_proto.CDU_RepeatMessageRequestBit <-> outer port CCU_CSWC/CDU_RepeatMessageRequestBit
    delegate CCU_proto.CDU_RepeatSts <-> outer port CCU_CSWC/CDU_RepeatSts
    delegate CCU_proto.CDU_SourceNodeIdentifier <-> outer port CCU_CSWC/CDU_SourceNodeIdentifier
    delegate CCU_proto.CDU_SupplierCode <-> outer port CCU_CSWC/CDU_SupplierCode
    delegate CCU_proto.CDU_SupplierNum <-> outer port CCU_CSWC/CDU_SupplierNum
    delegate CCU_proto.CDU_SwMajorVersion <-> outer port CCU_CSWC/CDU_SwMajorVersion
    delegate CCU_proto.CDU_SwMinorVersion <-> outer port CCU_CSWC/CDU_SwMinorVersion
    delegate CCU_proto.CDU_SwPatchVersion <-> outer port CCU_CSWC/CDU_SwPatchVersion
    delegate CCU_proto.CDU_SwVersionDay <-> outer port CCU_CSWC/CDU_SwVersionDay
    delegate CCU_proto.CDU_SwVersionMonth <-> outer port CCU_CSWC/CDU_SwVersionMonth
    delegate CCU_proto.CDU_SwVersionYear <-> outer port CCU_CSWC/CDU_SwVersionYear
    delegate CCU_proto.CDU_TotalFaultNum <-> outer port CCU_CSWC/CDU_TotalFaultNum
    delegate CCU_proto.DCDC_AlerSt <-> outer port CCU_CSWC/DCDC_AlerSt
    delegate CCU_proto.DCDC_CopntTemp <-> outer port CCU_CSWC/DCDC_CopntTemp
    delegate CCU_proto.DCDC_DcInterLockVolt <-> outer port CCU_CSWC/DCDC_DcInterLockVolt
    delegate CCU_proto.DCDC_DeratFlag <-> outer port CCU_CSWC/DCDC_DeratFlag
    delegate CCU_proto.DCDC_DeratReason1 <-> outer port CCU_CSWC/DCDC_DeratReason1
    delegate CCU_proto.DCDC_DeratReason{10..12} <-> outer port CCU_CSWC/DCDC_DeratReason{10..12}
    delegate CCU_proto.DCDC_DeratReason{2..9} <-> outer port CCU_CSWC/DCDC_DeratReason{2..9}
    delegate CCU_proto.DCDC_EnergyConvrtDir <-> outer port CCU_CSWC/DCDC_EnergyConvrtDir
    delegate CCU_proto.DCDC_FaultLevel <-> outer port CCU_CSWC/DCDC_FaultLevel
    delegate CCU_proto.DCDC_FaultLightReq <-> outer port CCU_CSWC/DCDC_FaultLightReq
    delegate CCU_proto.DCDC_FlowReq <-> outer port CCU_CSWC/DCDC_FlowReq
    delegate CCU_proto.DCDC_HVIL_48VDCDC_St <-> outer port CCU_CSWC/DCDC_HVIL_48VDCDC_St
    delegate CCU_proto.DCDC_HVIL_Batt_St <-> outer port CCU_CSWC/DCDC_HVIL_Batt_St
    delegate CCU_proto.DCDC_HVIL_EAS_St <-> outer port CCU_CSWC/DCDC_HVIL_EAS_St
    delegate CCU_proto.DCDC_HVIL_MCU_St <-> outer port CCU_CSWC/DCDC_HVIL_MCU_St
    delegate CCU_proto.DCDC_HVIL_PTC_St <-> outer port CCU_CSWC/DCDC_HVIL_PTC_St
    delegate CCU_proto.DCDC_HVIL_PTCR_St <-> outer port CCU_CSWC/DCDC_HVIL_PTCR_St
    delegate CCU_proto.DCDC_InpWtrTemp <-> outer port CCU_CSWC/DCDC_InpWtrTemp
    delegate CCU_proto.DCDC_IptCurrt <-> outer port CCU_CSWC/DCDC_IptCurrt
    delegate CCU_proto.DCDC_IptVolt <-> outer port CCU_CSWC/DCDC_IptVolt
    delegate CCU_proto.DCDC_LoopOut <-> outer port CCU_CSWC/DCDC_LoopOut
    delegate CCU_proto.DCDC_LvSidePwr <-> outer port CCU_CSWC/DCDC_LvSidePwr
    delegate CCU_proto.DCDC_MaxOptPwr <-> outer port CCU_CSWC/DCDC_MaxOptPwr
    delegate CCU_proto.DCDC_McuInterLockVolt <-> outer port CCU_CSWC/DCDC_McuInterLockVolt
    delegate CCU_proto.DCDC_NoLoadCurrtFlag <-> outer port CCU_CSWC/DCDC_NoLoadCurrtFlag
    delegate CCU_proto.DCDC_OperSt <-> outer port CCU_CSWC/DCDC_OperSt
    delegate CCU_proto.DCDC_OptCurrt <-> outer port CCU_CSWC/DCDC_OptCurrt
    delegate CCU_proto.DCDC_OptVolt <-> outer port CCU_CSWC/DCDC_OptVolt
    delegate CCU_proto.DCDC_Oring_APS_Temp <-> outer port CCU_CSWC/DCDC_Oring_APS_Temp
    delegate CCU_proto.DCDC_OutWtrTemp <-> outer port CCU_CSWC/DCDC_OutWtrTemp
    delegate CCU_proto.DCDC_OverTemp <-> outer port CCU_CSWC/DCDC_OverTemp
    delegate CCU_proto.DCDC_PeakPwrTi <-> outer port CCU_CSWC/DCDC_PeakPwrTi
    delegate CCU_proto.DCDC_PNGSt <-> outer port CCU_CSWC/DCDC_PNGSt
    delegate CCU_proto.DCDC_PtcInterLockVolt <-> outer port CCU_CSWC/DCDC_PtcInterLockVolt
    delegate CCU_proto.DCDC_SwMajorVersion <-> outer port CCU_CSWC/DCDC_SwMajorVersion
    delegate CCU_proto.DCDC_SwMinorVersion <-> outer port CCU_CSWC/DCDC_SwMinorVersion
    delegate CCU_proto.DCDC_SwPatchVersion <-> outer port CCU_CSWC/DCDC_SwPatchVersion
    delegate CCU_proto.DCDC_SwVersionDay <-> outer port CCU_CSWC/DCDC_SwVersionDay
    delegate CCU_proto.DCDC_SwVersionMonth <-> outer port CCU_CSWC/DCDC_SwVersionMonth
    delegate CCU_proto.DCDC_SwVersionYear <-> outer port CCU_CSWC/DCDC_SwVersionYear
    delegate CCU_proto.OBC_ACInpFrq <-> outer port CCU_CSWC/OBC_ACInpFrq
    delegate CCU_proto.OBC_AcIptSts <-> outer port CCU_CSWC/OBC_AcIptSts
    delegate CCU_proto.OBC_AcIptType <-> outer port CCU_CSWC/OBC_AcIptType
    delegate CCU_proto.OBC_ACL1Currt <-> outer port CCU_CSWC/OBC_ACL1Currt
    delegate CCU_proto.OBC_ACL1Volt <-> outer port CCU_CSWC/OBC_ACL1Volt
    delegate CCU_proto.OBC_ACL2Currt <-> outer port CCU_CSWC/OBC_ACL2Currt
    delegate CCU_proto.OBC_ACL2Volt <-> outer port CCU_CSWC/OBC_ACL2Volt
    delegate CCU_proto.OBC_ACL3Currt <-> outer port CCU_CSWC/OBC_ACL3Currt
    delegate CCU_proto.OBC_ACL3Volt <-> outer port CCU_CSWC/OBC_ACL3Volt
    delegate CCU_proto.OBC_AcLineImpedance <-> outer port CCU_CSWC/OBC_AcLineImpedance
    delegate CCU_proto.OBC_ACPileMaxCurrt <-> outer port CCU_CSWC/OBC_ACPileMaxCurrt
    delegate CCU_proto.OBC_ACPwr <-> outer port CCU_CSWC/OBC_ACPwr
    delegate CCU_proto.OBC_BusCapacity <-> outer port CCU_CSWC/OBC_BusCapacity
    delegate CCU_proto.OBC_CCRes <-> outer port CCU_CSWC/OBC_CCRes
    delegate CCU_proto.OBC_ChrgCablePermitCurrt <-> outer port CCU_CSWC/OBC_ChrgCablePermitCurrt
    delegate CCU_proto.OBC_ChrgDischrgStep <-> outer port CCU_CSWC/OBC_ChrgDischrgStep
    delegate CCU_proto.OBC_ChrgEndNum <-> outer port CCU_CSWC/OBC_ChrgEndNum
    delegate CCU_proto.OBC_ChrgGunCCSts <-> outer port CCU_CSWC/OBC_ChrgGunCCSts
    delegate CCU_proto.OBC_ChrgOptMaxCurrt <-> outer port CCU_CSWC/OBC_ChrgOptMaxCurrt
    delegate CCU_proto.OBC_ChrgOptMaxPwr <-> outer port CCU_CSWC/OBC_ChrgOptMaxPwr
    delegate CCU_proto.OBC_ChrgOptMaxVolt <-> outer port CCU_CSWC/OBC_ChrgOptMaxVolt
    delegate CCU_proto.OBC_ChrgOptMinVolt <-> outer port CCU_CSWC/OBC_ChrgOptMinVolt
    delegate CCU_proto.OBC_CopntTemp <-> outer port CCU_CSWC/OBC_CopntTemp
    delegate CCU_proto.OBC_CPDuty <-> outer port CCU_CSWC/OBC_CPDuty
    delegate CCU_proto.OBC_CPFreqSts <-> outer port CCU_CSWC/OBC_CPFreqSts
    delegate CCU_proto.OBC_CPFrq <-> outer port CCU_CSWC/OBC_CPFrq
    delegate CCU_proto.OBC_CPOutpDuty <-> outer port CCU_CSWC/OBC_CPOutpDuty
    delegate CCU_proto.OBC_CPOutpVolt <-> outer port CCU_CSWC/OBC_CPOutpVolt
    delegate CCU_proto.OBC_CPSts <-> outer port CCU_CSWC/OBC_CPSts
    delegate CCU_proto.OBC_CPValidSt <-> outer port CCU_CSWC/OBC_CPValidSt
    delegate CCU_proto.OBC_CPVolt <-> outer port CCU_CSWC/OBC_CPVolt
    delegate CCU_proto.OBC_DCChrgMod_LimCurrt <-> outer port CCU_CSWC/OBC_DCChrgMod_LimCurrt
    delegate CCU_proto.OBC_DCCurrt <-> outer port CCU_CSWC/OBC_DCCurrt
    delegate CCU_proto.OBC_DchaEndNum <-> outer port CCU_CSWC/OBC_DchaEndNum
    delegate CCU_proto.OBC_DCVolt <-> outer port CCU_CSWC/OBC_DCVolt
    delegate CCU_proto.OBC_DeratFlag <-> outer port CCU_CSWC/OBC_DeratFlag
    delegate CCU_proto.OBC_DeratReason1 <-> outer port CCU_CSWC/OBC_DeratReason1
    delegate CCU_proto.OBC_DeratReason{10..19} <-> outer port CCU_CSWC/OBC_DeratReason{10..19}
    delegate CCU_proto.OBC_DeratReason2 <-> outer port CCU_CSWC/OBC_DeratReason2
    delegate CCU_proto.OBC_DeratReason{20..24} <-> outer port CCU_CSWC/OBC_DeratReason{20..24}
    delegate CCU_proto.OBC_DeratReason{3..9} <-> outer port CCU_CSWC/OBC_DeratReason{3..9}
    delegate CCU_proto.OBC_DischrgLoadForm <-> outer port CCU_CSWC/OBC_DischrgLoadForm
    delegate CCU_proto.OBC_DischrgOptMaxPwr <-> outer port CCU_CSWC/OBC_DischrgOptMaxPwr
    delegate CCU_proto.OBC_DisWorkMode <-> outer port CCU_CSWC/OBC_DisWorkMode
    delegate CCU_proto.OBC_EnergyConvrtDir <-> outer port CCU_CSWC/OBC_EnergyConvrtDir
    delegate CCU_proto.OBC_FastChargeRelayNegSts <-> outer port CCU_CSWC/OBC_FastChargeRelayNegSts
    delegate CCU_proto.OBC_FastChargeRelayPosSts <-> outer port CCU_CSWC/OBC_FastChargeRelayPosSts
    delegate CCU_proto.OBC_FastChrgRelayNeg_Extd_U <-> outer port CCU_CSWC/OBC_FastChrgRelayNeg_Extd_U
    delegate CCU_proto.OBC_FastChrgRelayPos_Extd_U <-> outer port CCU_CSWC/OBC_FastChrgRelayPos_Extd_U
    delegate CCU_proto.OBC_FaultLevel <-> outer port CCU_CSWC/OBC_FaultLevel
    delegate CCU_proto.OBC_FaultLightReq <-> outer port CCU_CSWC/OBC_FaultLightReq
    delegate CCU_proto.OBC_HVIL_AC_St <-> outer port CCU_CSWC/OBC_HVIL_AC_St
    delegate CCU_proto.OBC_HVIL_DC_St <-> outer port CCU_CSWC/OBC_HVIL_DC_St
    delegate CCU_proto.OBC_InsulationR <-> outer port CCU_CSWC/OBC_InsulationR
    delegate CCU_proto.OBC_Ithd <-> outer port CCU_CSWC/OBC_Ithd
    delegate CCU_proto.OBC_OperSt <-> outer port CCU_CSWC/OBC_OperSt
    delegate CCU_proto.OBC_RatedPwrLevel <-> outer port CCU_CSWC/OBC_RatedPwrLevel
    delegate CCU_proto.OBC_RBCurrt <-> outer port CCU_CSWC/OBC_RBCurrt
    delegate CCU_proto.OBC_RBMainK{1..4}Sts <-> outer port CCU_CSWC/OBC_RBMainK{1..4}Sts
    delegate CCU_proto.OBC_S1Sts <-> outer port CCU_CSWC/OBC_S1Sts
    delegate CCU_proto.OBC_S2Sts <-> outer port CCU_CSWC/OBC_S2Sts
    delegate CCU_proto.OBC_S4Sts <-> outer port CCU_CSWC/OBC_S4Sts
    delegate CCU_proto.OBC_SwMajorVersion <-> outer port CCU_CSWC/OBC_SwMajorVersion
    delegate CCU_proto.OBC_SwMinorVersion <-> outer port CCU_CSWC/OBC_SwMinorVersion
    delegate CCU_proto.OBC_SwPatchVersion <-> outer port CCU_CSWC/OBC_SwPatchVersion
    delegate CCU_proto.OBC_SwVersionDay <-> outer port CCU_CSWC/OBC_SwVersionDay
    delegate CCU_proto.OBC_SwVersionMonth <-> outer port CCU_CSWC/OBC_SwVersionMonth
    delegate CCU_proto.OBC_SwVersionYear <-> outer port CCU_CSWC/OBC_SwVersionYear
    delegate CCU_proto.OBC_Uthd <-> outer port CCU_CSWC/OBC_Uthd
    delegate CCU_proto.OBC_WorkMode <-> outer port CCU_CSWC/OBC_WorkMode
    delegate CCU_proto.BMS_ActvHvOnReq <-> outer port CCU_CSWC/BMS_ActvHvOnReq
    delegate CCU_proto.BMS_BattVolt_U7 <-> outer port CCU_CSWC/BMS_BattVolt_U7
    delegate CCU_proto.BMS_ChargeInfo_Checksum <-> outer port CCU_CSWC/BMS_ChargeInfo_Checksum
    delegate CCU_proto.BMS_ChargeInfo_Counter <-> outer port CCU_CSWC/BMS_ChargeInfo_Counter
    delegate CCU_proto.BMS_DCChrgConnectSt <-> outer port CCU_CSWC/BMS_DCChrgConnectSt
    delegate CCU_proto.BMS_MainNegSt <-> outer port CCU_CSWC/BMS_MainNegSt
    delegate CCU_proto.BMS_MainPosSt <-> outer port CCU_CSWC/BMS_MainPosSt
    delegate CCU_proto.BMS_MainPreChrgSt <-> outer port CCU_CSWC/BMS_MainPreChrgSt
    delegate CCU_proto.BMS_Measure_Checksum <-> outer port CCU_CSWC/BMS_Measure_Checksum
    delegate CCU_proto.BMS_Measure_Counter <-> outer port CCU_CSWC/BMS_Measure_Counter
    delegate CCU_proto.BMS_OBCCurrtReq <-> outer port CCU_CSWC/BMS_OBCCurrtReq
    delegate CCU_proto.BMS_OBCInvACVoltReq <-> outer port CCU_CSWC/BMS_OBCInvACVoltReq
    delegate CCU_proto.BMS_OBCInvMaxPermPwr <-> outer port CCU_CSWC/BMS_OBCInvMaxPermPwr
    delegate CCU_proto.BMS_OBCVoltReq <-> outer port CCU_CSWC/BMS_OBCVoltReq
    delegate CCU_proto.BMS_OBCWorkModReq <-> outer port CCU_CSWC/BMS_OBCWorkModReq
    delegate CCU_proto.BMS_OperSt <-> outer port CCU_CSWC/BMS_OperSt
    delegate CCU_proto.IPB_VehicleSpeed <-> outer port CCU_CSWC/IPB_VehicleSpeed
    delegate CCU_proto.IPB_VehicleSpeedValid <-> outer port CCU_CSWC/IPB_VehicleSpeedValid
    delegate CCU_proto.TBOX_DSTFlag <-> outer port CCU_CSWC/TBOX_DSTFlag
    delegate CCU_proto.TBOX_TimeDay <-> outer port CCU_CSWC/TBOX_TimeDay
    delegate CCU_proto.TBOX_TimeFlag <-> outer port CCU_CSWC/TBOX_TimeFlag
    delegate CCU_proto.TBOX_TimeHour <-> outer port CCU_CSWC/TBOX_TimeHour
    delegate CCU_proto.TBOX_TimeMinute <-> outer port CCU_CSWC/TBOX_TimeMinute
    delegate CCU_proto.TBOX_TimeMonth <-> outer port CCU_CSWC/TBOX_TimeMonth
    delegate CCU_proto.TBOX_TimeSecond <-> outer port CCU_CSWC/TBOX_TimeSecond
    delegate CCU_proto.TBOX_TimeYear <-> outer port CCU_CSWC/TBOX_TimeYear
    delegate CCU_proto.TBOX_TimeZone <-> outer port CCU_CSWC/TBOX_TimeZone
    delegate CCU_proto.TBOX_TimeZoneMinute <-> outer port CCU_CSWC/TBOX_TimeZoneMinute
    delegate CCU_proto.TBOX_TimeZoneNum <-> outer port CCU_CSWC/TBOX_TimeZoneNum
    delegate CCU_proto.VDC_ActGearSt <-> outer port CCU_CSWC/VDC_ActGearSt
    delegate CCU_proto.VDC_BMSDchaMaxPwr <-> outer port CCU_CSWC/VDC_BMSDchaMaxPwr
    delegate CCU_proto.VDC_DCDCEnableCmd <-> outer port CCU_CSWC/VDC_DCDCEnableCmd
    delegate CCU_proto.VDC_DCDCMaxCurrtAlld <-> outer port CCU_CSWC/VDC_DCDCMaxCurrtAlld
    delegate CCU_proto.VDC_DCDCSetVolt <-> outer port CCU_CSWC/VDC_DCDCSetVolt
    delegate CCU_proto.VDC_HVCtrl_Checksum <-> outer port CCU_CSWC/VDC_HVCtrl_Checksum
    delegate CCU_proto.VDC_HVCtrl_Counter <-> outer port CCU_CSWC/VDC_HVCtrl_Counter
    delegate CCU_proto.VDC_OBCACCurrtMaxPerm <-> outer port CCU_CSWC/VDC_OBCACCurrtMaxPerm
    delegate CCU_proto.VDC_RBAllwdSts <-> outer port CCU_CSWC/VDC_RBAllwdSts
    delegate CCU_proto.VDC_RBDCACVoltReq <-> outer port CCU_CSWC/VDC_RBDCACVoltReq
    delegate CCU_proto.VDC_RBEnableSt <-> outer port CCU_CSWC/VDC_RBEnableSt
    delegate CCU_proto.VDC_RBMainK1K2Ctrl <-> outer port CCU_CSWC/VDC_RBMainK1K2Ctrl
    delegate CCU_proto.VDC_RBMainK3K4Ctrl <-> outer port CCU_CSWC/VDC_RBMainK3K4Ctrl
    delegate CCU_proto.VDC_RBOBCWorkModReq <-> outer port CCU_CSWC/VDC_RBOBCWorkModReq
    delegate CCU_proto.VDC_SysState_Checksum <-> outer port CCU_CSWC/VDC_SysState_Checksum
    delegate CCU_proto.VDC_SysState_Counter <-> outer port CCU_CSWC/VDC_SysState_Counter
    delegate CCU_proto.VDC_TotalRang_VV01 <-> outer port CCU_CSWC/VDC_TotalRang_VV01
    delegate CCU_proto.VDC_VehState_Checksum <-> outer port CCU_CSWC/VDC_VehState_Checksum
    delegate CCU_proto.VDC_VehState_Counter <-> outer port CCU_CSWC/VDC_VehState_Counter
    delegate CCU_proto.VIU_CarMode <-> outer port CCU_CSWC/VIU_CarMode
    delegate CCU_proto.VIU_Info_Checksum_VV01 <-> outer port CCU_CSWC/VIU_Info_Checksum_VV01
    delegate CCU_proto.VIU_Info_Counter <-> outer port CCU_CSWC/VIU_Info_Counter
    delegate CCU_proto.VIU_PowerMode <-> outer port CCU_CSWC/VIU_PowerMode
    delegate CCU_proto.VIU_Route_EP_Checksum <-> outer port CCU_CSWC/VIU_Route_EP_Checksum
    delegate CCU_proto.VIU_Route_EP_Counter <-> outer port CCU_CSWC/VIU_Route_EP_Counter
    delegate CCU_proto.VIU_UsageMode <-> outer port CCU_CSWC/VIU_UsageMode
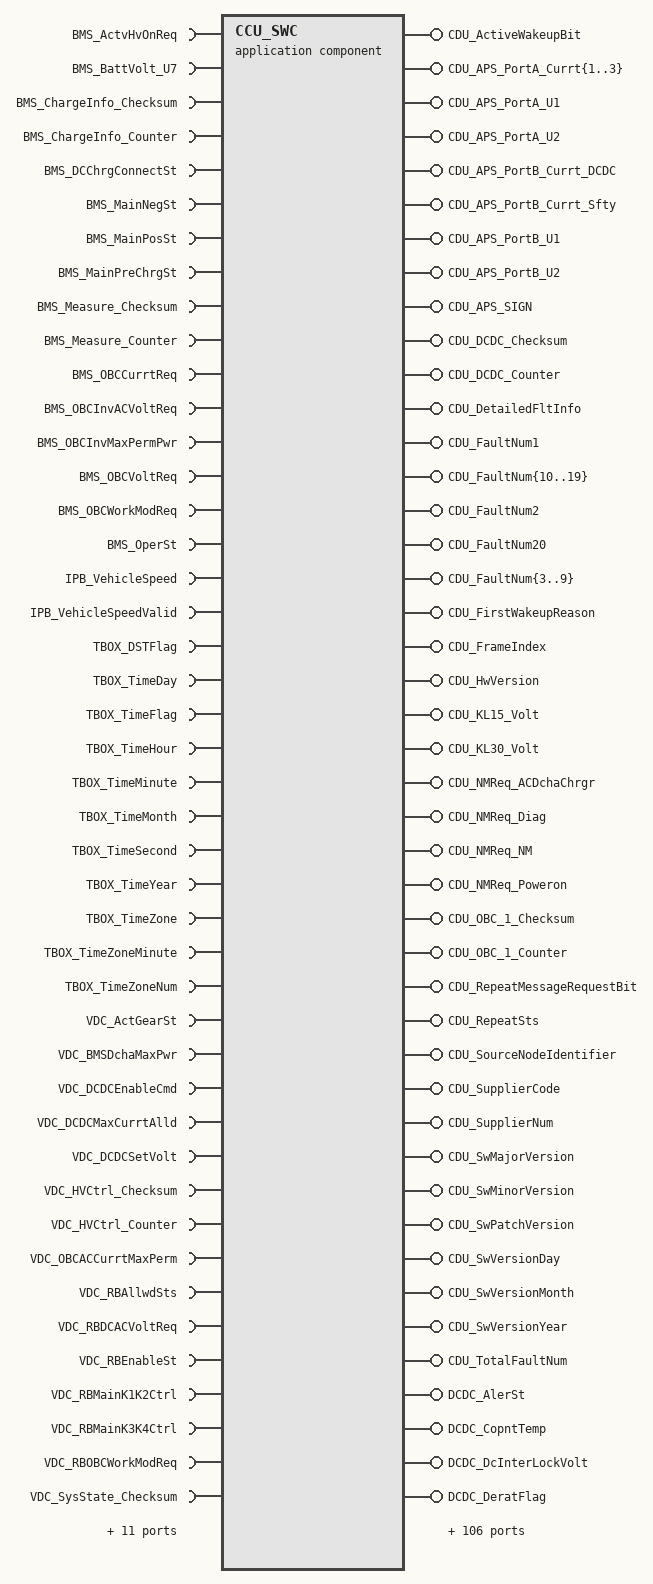
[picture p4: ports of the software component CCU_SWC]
  application sw component type CCU_SWC
    198 x provide port:
      CDU_ActiveWakeupBit: provided-interface=CDU_ActiveWakeupBit
      CDU_APS_PortA_Currt{1..3}: provided-interface=CDU_APS_PortA_Currt{1..3}
      CDU_APS_PortA_U1: provided-interface=CDU_APS_PortA_U1
      CDU_APS_PortA_U2: provided-interface=CDU_APS_PortA_U2
      CDU_APS_PortB_Currt_DCDC: provided-interface=CDU_APS_PortB_Currt_DCDC
      CDU_APS_PortB_Currt_Sfty: provided-interface=CDU_APS_PortB_Currt_Sfty
      CDU_APS_PortB_U1: provided-interface=CDU_APS_PortB_U1
      CDU_APS_PortB_U2: provided-interface=CDU_APS_PortB_U2
      CDU_APS_SIGN: provided-interface=CDU_APS_SIGN
      CDU_DCDC_Checksum: provided-interface=CDU_DCDC_Checksum
      CDU_DCDC_Counter: provided-interface=CDU_DCDC_Counter
      CDU_DetailedFltInfo: provided-interface=CDU_DetailedFltInfo
      CDU_FaultNum1: provided-interface=CDU_FaultNum1
      CDU_FaultNum{10..19}: provided-interface=CDU_FaultNum{10..19}
      CDU_FaultNum2: provided-interface=CDU_FaultNum2
      CDU_FaultNum20: provided-interface=CDU_FaultNum20
      CDU_FaultNum{3..9}: provided-interface=CDU_FaultNum{3..9}
      CDU_FirstWakeupReason: provided-interface=CDU_FirstWakeupReason
      CDU_FrameIndex: provided-interface=CDU_FrameIndex
      CDU_HwVersion: provided-interface=CDU_HwVersion
      CDU_KL15_Volt: provided-interface=CDU_KL15_Volt
      CDU_KL30_Volt: provided-interface=CDU_KL30_Volt
      CDU_NMReq_ACDchaChrgr: provided-interface=CDU_NMReq_ACDchaChrgr
      CDU_NMReq_Diag: provided-interface=CDU_NMReq_Diag
      CDU_NMReq_NM: provided-interface=CDU_NMReq_NM
      CDU_NMReq_Poweron: provided-interface=CDU_NMReq_Poweron
      CDU_OBC_1_Checksum: provided-interface=CDU_OBC_1_Checksum
      CDU_OBC_1_Counter: provided-interface=CDU_OBC_1_Counter
      CDU_RepeatMessageRequestBit: provided-interface=CDU_RepeatMessageRequestBit
      CDU_RepeatSts: provided-interface=CDU_RepeatSts
      CDU_SourceNodeIdentifier: provided-interface=CDU_SourceNodeIdentifier
      CDU_SupplierCode: provided-interface=CDU_SupplierCode
      CDU_SupplierNum: provided-interface=CDU_SupplierNum
      CDU_SwMajorVersion: provided-interface=CDU_SwMajorVersion
      CDU_SwMinorVersion: provided-interface=CDU_SwMinorVersion
      CDU_SwPatchVersion: provided-interface=CDU_SwPatchVersion
      CDU_SwVersionDay: provided-interface=CDU_SwVersionDay
      CDU_SwVersionMonth: provided-interface=CDU_SwVersionMonth
      CDU_SwVersionYear: provided-interface=CDU_SwVersionYear
      CDU_TotalFaultNum: provided-interface=CDU_TotalFaultNum
      DCDC_AlerSt: provided-interface=DCDC_AlerSt
      DCDC_CopntTemp: provided-interface=DCDC_CopntTemp
      DCDC_DcInterLockVolt: provided-interface=DCDC_DcInterLockVolt
      DCDC_DeratFlag: provided-interface=DCDC_DeratFlag
      DCDC_DeratReason1: provided-interface=DCDC_DeratReason1
      DCDC_DeratReason{10..12}: provided-interface=DCDC_DeratReason{10..12}
      DCDC_DeratReason{2..9}: provided-interface=DCDC_DeratReason{2..9}
      DCDC_EnergyConvrtDir: provided-interface=DCDC_EnergyConvrtDir
      DCDC_FaultLevel: provided-interface=DCDC_FaultLevel
      DCDC_FaultLightReq: provided-interface=DCDC_FaultLightReq
      DCDC_FlowReq: provided-interface=DCDC_FlowReq
      DCDC_HVIL_48VDCDC_St: provided-interface=DCDC_HVIL_48VDCDC_St
      DCDC_HVIL_Batt_St: provided-interface=DCDC_HVIL_Batt_St
      DCDC_HVIL_EAS_St: provided-interface=DCDC_HVIL_EAS_St
      DCDC_HVIL_MCU_St: provided-interface=DCDC_HVIL_MCU_St
      DCDC_HVIL_PTC_St: provided-interface=DCDC_HVIL_PTC_St
      DCDC_HVIL_PTCR_St: provided-interface=DCDC_HVIL_PTCR_St
      DCDC_InpWtrTemp: provided-interface=DCDC_InpWtrTemp
      DCDC_IptCurrt: provided-interface=DCDC_IptCurrt
      DCDC_IptVolt: provided-interface=DCDC_IptVolt
      DCDC_LoopOut: provided-interface=DCDC_LoopOut
      DCDC_LvSidePwr: provided-interface=DCDC_LvSidePwr
      DCDC_MaxOptPwr: provided-interface=DCDC_MaxOptPwr
      DCDC_McuInterLockVolt: provided-interface=DCDC_McuInterLockVolt
      DCDC_NoLoadCurrtFlag: provided-interface=DCDC_NoLoadCurrtFlag
      DCDC_OperSt: provided-interface=DCDC_OperSt
      DCDC_OptCurrt: provided-interface=DCDC_OptCurrt
      DCDC_OptVolt: provided-interface=DCDC_OptVolt
      DCDC_Oring_APS_Temp: provided-interface=DCDC_Oring_APS_Temp
      DCDC_OutWtrTemp: provided-interface=DCDC_OutWtrTemp
      DCDC_OverTemp: provided-interface=DCDC_OverTemp
      DCDC_PeakPwrTi: provided-interface=DCDC_PeakPwrTi
      DCDC_PNGSt: provided-interface=DCDC_PNGSt
      DCDC_PtcInterLockVolt: provided-interface=DCDC_PtcInterLockVolt
      DCDC_SwMajorVersion: provided-interface=DCDC_SwMajorVersion
      DCDC_SwMinorVersion: provided-interface=DCDC_SwMinorVersion
      DCDC_SwPatchVersion: provided-interface=DCDC_SwPatchVersion
      DCDC_SwVersionDay: provided-interface=DCDC_SwVersionDay
      DCDC_SwVersionMonth: provided-interface=DCDC_SwVersionMonth
      DCDC_SwVersionYear: provided-interface=DCDC_SwVersionYear
      OBC_ACInpFrq: provided-interface=OBC_ACInpFrq
      OBC_AcIptSts: provided-interface=OBC_AcIptSts
      OBC_AcIptType: provided-interface=OBC_AcIptType
      OBC_ACL1Currt: provided-interface=OBC_ACL1Currt
      OBC_ACL1Volt: provided-interface=OBC_ACL1Volt
      OBC_ACL2Currt: provided-interface=OBC_ACL2Currt
      OBC_ACL2Volt: provided-interface=OBC_ACL2Volt
      OBC_ACL3Currt: provided-interface=OBC_ACL3Currt
      OBC_ACL3Volt: provided-interface=OBC_ACL3Volt
      OBC_AcLineImpedance: provided-interface=OBC_AcLineImpedance
      OBC_ACPileMaxCurrt: provided-interface=OBC_ACPileMaxCurrt
      OBC_ACPwr: provided-interface=OBC_ACPwr
      OBC_BusCapacity: provided-interface=OBC_BusCapacity
      OBC_CCRes: provided-interface=OBC_CCRes
      OBC_ChrgCablePermitCurrt: provided-interface=OBC_ChrgCablePermitCurrt
      OBC_ChrgDischrgStep: provided-interface=OBC_ChrgDischrgStep
      OBC_ChrgEndNum: provided-interface=OBC_ChrgEndNum
      OBC_ChrgGunCCSts: provided-interface=OBC_ChrgGunCCSts
      OBC_ChrgOptMaxCurrt: provided-interface=OBC_ChrgOptMaxCurrt
      OBC_ChrgOptMaxPwr: provided-interface=OBC_ChrgOptMaxPwr
      OBC_ChrgOptMaxVolt: provided-interface=OBC_ChrgOptMaxVolt
      OBC_ChrgOptMinVolt: provided-interface=OBC_ChrgOptMinVolt
      OBC_CopntTemp: provided-interface=OBC_CopntTemp
      OBC_CPDuty: provided-interface=OBC_CPDuty
      OBC_CPFreqSts: provided-interface=OBC_CPFreqSts
      OBC_CPFrq: provided-interface=OBC_CPFrq
      OBC_CPOutpDuty: provided-interface=OBC_CPOutpDuty
      OBC_CPOutpVolt: provided-interface=OBC_CPOutpVolt
      OBC_CPSts: provided-interface=OBC_CPSts
      OBC_CPValidSt: provided-interface=OBC_CPValidSt
      OBC_CPVolt: provided-interface=OBC_CPVolt
      OBC_DCChrgMod_LimCurrt: provided-interface=OBC_DCChrgMod_LimCurrt
      OBC_DCCurrt: provided-interface=OBC_DCCurrt
      OBC_DchaEndNum: provided-interface=OBC_DchaEndNum
      OBC_DCVolt: provided-interface=OBC_DCVolt
      OBC_DeratFlag: provided-interface=OBC_DeratFlag
      OBC_DeratReason1: provided-interface=OBC_DeratReason1
      OBC_DeratReason{10..19}: provided-interface=OBC_DeratReason{10..19}
      OBC_DeratReason2: provided-interface=OBC_DeratReason2
      OBC_DeratReason{20..24}: provided-interface=OBC_DeratReason{20..24}
      OBC_DeratReason{3..9}: provided-interface=OBC_DeratReason{3..9}
      OBC_DischrgLoadForm: provided-interface=OBC_DischrgLoadForm
      OBC_DischrgOptMaxPwr: provided-interface=OBC_DischrgOptMaxPwr
      OBC_DisWorkMode: provided-interface=OBC_DisWorkMode
      OBC_EnergyConvrtDir: provided-interface=OBC_EnergyConvrtDir
      OBC_FastChargeRelayNegSts: provided-interface=OBC_FastChargeRelayNegSts
      OBC_FastChargeRelayPosSts: provided-interface=OBC_FastChargeRelayPosSts
      OBC_FastChrgRelayNeg_Extd_U: provided-interface=OBC_FastChrgRelayNeg_Extd_U
      OBC_FastChrgRelayPos_Extd_U: provided-interface=OBC_FastChrgRelayPos_Extd_U
      OBC_FaultLevel: provided-interface=OBC_FaultLevel
      OBC_FaultLightReq: provided-interface=OBC_FaultLightReq
      OBC_HVIL_AC_St: provided-interface=OBC_HVIL_AC_St
      OBC_HVIL_DC_St: provided-interface=OBC_HVIL_DC_St
      OBC_InsulationR: provided-interface=OBC_InsulationR
      OBC_Ithd: provided-interface=OBC_Ithd
      OBC_OperSt: provided-interface=OBC_OperSt
      OBC_RatedPwrLevel: provided-interface=OBC_RatedPwrLevel
      OBC_RBCurrt: provided-interface=OBC_RBCurrt
      OBC_RBMainK{1..4}Sts: provided-interface=OBC_RBMainK{1..4}Sts
      OBC_S1Sts: provided-interface=OBC_S1Sts
      OBC_S2Sts: provided-interface=OBC_S2Sts
      OBC_S4Sts: provided-interface=OBC_S4Sts
      OBC_SwMajorVersion: provided-interface=OBC_SwMajorVersion
      OBC_SwMinorVersion: provided-interface=OBC_SwMinorVersion
      OBC_SwPatchVersion: provided-interface=OBC_SwPatchVersion
      OBC_SwVersionDay: provided-interface=OBC_SwVersionDay
      OBC_SwVersionMonth: provided-interface=OBC_SwVersionMonth
      OBC_SwVersionYear: provided-interface=OBC_SwVersionYear
      OBC_Uthd: provided-interface=OBC_Uthd
      OBC_WorkMode: provided-interface=OBC_WorkMode
    55 x require port:
      BMS_ActvHvOnReq: required-interface=BMS_ActvHvOnReq
      BMS_BattVolt_U7: required-interface=BMS_BattVolt_U7
      BMS_ChargeInfo_Checksum: required-interface=BMS_ChargeInfo_Checksum
      BMS_ChargeInfo_Counter: required-interface=BMS_ChargeInfo_Counter
      BMS_DCChrgConnectSt: required-interface=BMS_DCChrgConnectSt
      BMS_MainNegSt: required-interface=BMS_MainNegSt
      BMS_MainPosSt: required-interface=BMS_MainPosSt
      BMS_MainPreChrgSt: required-interface=BMS_MainPreChrgSt
      BMS_Measure_Checksum: required-interface=BMS_Measure_Checksum
      BMS_Measure_Counter: required-interface=BMS_Measure_Counter
      BMS_OBCCurrtReq: required-interface=BMS_OBCCurrtReq
      BMS_OBCInvACVoltReq: required-interface=BMS_OBCInvACVoltReq
      BMS_OBCInvMaxPermPwr: required-interface=BMS_OBCInvMaxPermPwr
      BMS_OBCVoltReq: required-interface=BMS_OBCVoltReq
      BMS_OBCWorkModReq: required-interface=BMS_OBCWorkModReq
      BMS_OperSt: required-interface=BMS_OperSt
      IPB_VehicleSpeed: required-interface=IPB_VehicleSpeed
      IPB_VehicleSpeedValid: required-interface=IPB_VehicleSpeedValid
      TBOX_DSTFlag: required-interface=TBOX_DSTFlag
      TBOX_TimeDay: required-interface=TBOX_TimeDay
      TBOX_TimeFlag: required-interface=TBOX_TimeFlag
      TBOX_TimeHour: required-interface=TBOX_TimeHour
      TBOX_TimeMinute: required-interface=TBOX_TimeMinute
      TBOX_TimeMonth: required-interface=TBOX_TimeMonth
      TBOX_TimeSecond: required-interface=TBOX_TimeSecond
      TBOX_TimeYear: required-interface=TBOX_TimeYear
      TBOX_TimeZone: required-interface=TBOX_TimeZone
      TBOX_TimeZoneMinute: required-interface=TBOX_TimeZoneMinute
      TBOX_TimeZoneNum: required-interface=TBOX_TimeZoneNum
      VDC_ActGearSt: required-interface=VDC_ActGearSt
      VDC_BMSDchaMaxPwr: required-interface=VDC_BMSDchaMaxPwr
      VDC_DCDCEnableCmd: required-interface=VDC_DCDCEnableCmd
      VDC_DCDCMaxCurrtAlld: required-interface=VDC_DCDCMaxCurrtAlld
      VDC_DCDCSetVolt: required-interface=VDC_DCDCSetVolt
      VDC_HVCtrl_Checksum: required-interface=VDC_HVCtrl_Checksum
      VDC_HVCtrl_Counter: required-interface=VDC_HVCtrl_Counter
      VDC_OBCACCurrtMaxPerm: required-interface=VDC_OBCACCurrtMaxPerm
      VDC_RBAllwdSts: required-interface=VDC_RBAllwdSts
      VDC_RBDCACVoltReq: required-interface=VDC_RBDCACVoltReq
      VDC_RBEnableSt: required-interface=VDC_RBEnableSt
      VDC_RBMainK1K2Ctrl: required-interface=VDC_RBMainK1K2Ctrl
      VDC_RBMainK3K4Ctrl: required-interface=VDC_RBMainK3K4Ctrl
      VDC_RBOBCWorkModReq: required-interface=VDC_RBOBCWorkModReq
      VDC_SysState_Checksum: required-interface=VDC_SysState_Checksum
      VDC_SysState_Counter: required-interface=VDC_SysState_Counter
      VDC_TotalRang_VV01: required-interface=VDC_TotalRang_VV01
      VDC_VehState_Checksum: required-interface=VDC_VehState_Checksum
      VDC_VehState_Counter: required-interface=VDC_VehState_Counter
      VIU_CarMode: required-interface=VIU_CarMode
      VIU_Info_Checksum_VV01: required-interface=VIU_Info_Checksum_VV01
      VIU_Info_Counter: required-interface=VIU_Info_Counter
      VIU_PowerMode: required-interface=VIU_PowerMode
      VIU_Route_EP_Checksum: required-interface=VIU_Route_EP_Checksum
      VIU_Route_EP_Counter: required-interface=VIU_Route_EP_Counter
      VIU_UsageMode: required-interface=VIU_UsageMode
package /Interfaces
  253 x sender receiver interface:
    CDU_ActiveWakeupBit
      data CDU_ActiveWakeupBit: type=CDU_ActiveWakeupBit_dt
    CDU_APS_PortA_Currt1
      data CDU_APS_PortA_Currt1: type=CDU_APS_PortA_Currt1_dt
    CDU_APS_PortA_Currt2
      data CDU_APS_PortA_Currt2: type=CDU_APS_PortA_Currt2_dt
    CDU_APS_PortA_Currt3
      data CDU_APS_PortA_Currt3: type=CDU_APS_PortA_Currt3_dt
    CDU_APS_PortA_U1
      data CDU_APS_PortA_U1: type=CDU_APS_PortA_U1_dt
    CDU_APS_PortA_U2
      data CDU_APS_PortA_U2: type=CDU_APS_PortA_U2_dt
    CDU_APS_PortB_Currt_DCDC
      data CDU_APS_PortB_Currt_DCDC: type=CDU_APS_PortB_Currt_DCDC_dt
    CDU_APS_PortB_Currt_Sfty
      data CDU_APS_PortB_Currt_Sfty: type=CDU_APS_PortB_Currt_Sfty_dt
    CDU_APS_PortB_U1
      data CDU_APS_PortB_U1: type=CDU_APS_PortB_U1_dt
    CDU_APS_PortB_U2
      data CDU_APS_PortB_U2: type=CDU_APS_PortB_U2_dt
    CDU_APS_SIGN
      data CDU_APS_SIGN: type=CDU_APS_SIGN_dt
    CDU_DCDC_Checksum
      data CDU_DCDC_Checksum: type=CDU_DCDC_Checksum_dt
    CDU_DCDC_Counter
      data CDU_DCDC_Counter: type=CDU_DCDC_Counter_dt
    CDU_DetailedFltInfo
      data CDU_DetailedFltInfo: type=CDU_DetailedFltInfo_dt
    CDU_FaultNum1
      data CDU_FaultNum1: type=CDU_FaultNum1_dt
    CDU_FaultNum10
      data CDU_FaultNum10: type=CDU_FaultNum10_dt
    CDU_FaultNum11
      data CDU_FaultNum11: type=CDU_FaultNum11_dt
    CDU_FaultNum12
      data CDU_FaultNum12: type=CDU_FaultNum12_dt
    CDU_FaultNum13
      data CDU_FaultNum13: type=CDU_FaultNum13_dt
    CDU_FaultNum14
      data CDU_FaultNum14: type=CDU_FaultNum14_dt
    CDU_FaultNum15
      data CDU_FaultNum15: type=CDU_FaultNum15_dt
    CDU_FaultNum16
      data CDU_FaultNum16: type=CDU_FaultNum16_dt
    CDU_FaultNum17
      data CDU_FaultNum17: type=CDU_FaultNum17_dt
    CDU_FaultNum18
      data CDU_FaultNum18: type=CDU_FaultNum18_dt
    CDU_FaultNum19
      data CDU_FaultNum19: type=CDU_FaultNum19_dt
    CDU_FaultNum2
      data CDU_FaultNum2: type=CDU_FaultNum2_dt
    CDU_FaultNum20
      data CDU_FaultNum20: type=CDU_FaultNum20_dt
    CDU_FaultNum3
      data CDU_FaultNum3: type=CDU_FaultNum3_dt
    CDU_FaultNum4
      data CDU_FaultNum4: type=CDU_FaultNum4_dt
    CDU_FaultNum5
      data CDU_FaultNum5: type=CDU_FaultNum5_dt
    CDU_FaultNum6
      data CDU_FaultNum6: type=CDU_FaultNum6_dt
    CDU_FaultNum7
      data CDU_FaultNum7: type=CDU_FaultNum7_dt
    CDU_FaultNum8
      data CDU_FaultNum8: type=CDU_FaultNum8_dt
    CDU_FaultNum9
      data CDU_FaultNum9: type=CDU_FaultNum9_dt
    CDU_FirstWakeupReason
      data CDU_FirstWakeupReason: type=CDU_FirstWakeupReason_dt
    CDU_FrameIndex
      data CDU_FrameIndex: type=CDU_FrameIndex_dt
    CDU_HwVersion
      data CDU_HwVersion: type=CDU_HwVersion_dt
    CDU_KL15_Volt
      data CDU_KL15_Volt: type=CDU_KL15_Volt_dt
    CDU_KL30_Volt
      data CDU_KL30_Volt: type=CDU_KL30_Volt_dt
    CDU_NMReq_ACDchaChrgr
      data CDU_NMReq_ACDchaChrgr: type=CDU_NMReq_ACDchaChrgr_dt
    CDU_NMReq_Diag
      data CDU_NMReq_Diag: type=CDU_NMReq_Diag_dt
    CDU_NMReq_NM
      data CDU_NMReq_NM: type=CDU_NMReq_NM_dt
    CDU_NMReq_Poweron
      data CDU_NMReq_Poweron: type=CDU_NMReq_Poweron_dt
    CDU_OBC_1_Checksum
      data CDU_OBC_1_Checksum: type=CDU_OBC_1_Checksum_dt
    CDU_OBC_1_Counter
      data CDU_OBC_1_Counter: type=CDU_OBC_1_Counter_dt
    CDU_RepeatMessageRequestBit
      data CDU_RepeatMessageRequestBit: type=CDU_RepeatMessageRequestBit_dt
    CDU_RepeatSts
      data CDU_RepeatSts: type=CDU_RepeatSts_dt
    CDU_SourceNodeIdentifier
      data CDU_SourceNodeIdentifier: type=CDU_SourceNodeIdentifier_dt
    CDU_SupplierCode
      data CDU_SupplierCode: type=CDU_SupplierCode_dt
    CDU_SupplierNum
      data CDU_SupplierNum: type=CDU_SupplierNum_dt
    CDU_SwMajorVersion
      data CDU_SwMajorVersion: type=CDU_SwMajorVersion_dt
    CDU_SwMinorVersion
      data CDU_SwMinorVersion: type=CDU_SwMinorVersion_dt
    CDU_SwPatchVersion
      data CDU_SwPatchVersion: type=CDU_SwPatchVersion_dt
    CDU_SwVersionDay
      data CDU_SwVersionDay: type=CDU_SwVersionDay_dt
    CDU_SwVersionMonth
      data CDU_SwVersionMonth: type=CDU_SwVersionMonth_dt
    CDU_SwVersionYear
      data CDU_SwVersionYear: type=CDU_SwVersionYear_dt
    CDU_TotalFaultNum
      data CDU_TotalFaultNum: type=CDU_TotalFaultNum_dt
    DCDC_AlerSt
      data DCDC_AlerSt: type=DCDC_AlerSt_dt
    DCDC_CopntTemp
      data DCDC_CopntTemp: type=DCDC_CopntTemp_dt
    DCDC_DcInterLockVolt
      data DCDC_DcInterLockVolt: type=DCDC_DcInterLockVolt_dt
    DCDC_DeratFlag
      data DCDC_DeratFlag: type=DCDC_DeratFlag_dt
    DCDC_DeratReason1
      data DCDC_DeratReason1: type=DCDC_DeratReason1_dt
    DCDC_DeratReason10
      data DCDC_DeratReason10: type=DCDC_DeratReason10_dt
    DCDC_DeratReason11
      data DCDC_DeratReason11: type=DCDC_DeratReason11_dt
    DCDC_DeratReason12
      data DCDC_DeratReason12: type=DCDC_DeratReason12_dt
    DCDC_DeratReason2
      data DCDC_DeratReason2: type=DCDC_DeratReason2_dt
    DCDC_DeratReason3
      data DCDC_DeratReason3: type=DCDC_DeratReason3_dt
    DCDC_DeratReason4
      data DCDC_DeratReason4: type=DCDC_DeratReason4_dt
    DCDC_DeratReason5
      data DCDC_DeratReason5: type=DCDC_DeratReason5_dt
    DCDC_DeratReason6
      data DCDC_DeratReason6: type=DCDC_DeratReason6_dt
    DCDC_DeratReason7
      data DCDC_DeratReason7: type=DCDC_DeratReason7_dt
    DCDC_DeratReason8
      data DCDC_DeratReason8: type=DCDC_DeratReason8_dt
    DCDC_DeratReason9
      data DCDC_DeratReason9: type=DCDC_DeratReason9_dt
    DCDC_EnergyConvrtDir
      data DCDC_EnergyConvrtDir: type=DCDC_EnergyConvrtDir_dt
    DCDC_FaultLevel
      data DCDC_FaultLevel: type=DCDC_FaultLevel_dt
    DCDC_FaultLightReq
      data DCDC_FaultLightReq: type=DCDC_FaultLightReq_dt
    DCDC_FlowReq
      data DCDC_FlowReq: type=DCDC_FlowReq_dt
    DCDC_HVIL_48VDCDC_St
      data DCDC_HVIL_48VDCDC_St: type=DCDC_HVIL_48VDCDC_St_dt
    DCDC_HVIL_Batt_St
      data DCDC_HVIL_Batt_St: type=DCDC_HVIL_Batt_St_dt
    DCDC_HVIL_EAS_St
      data DCDC_HVIL_EAS_St: type=DCDC_HVIL_EAS_St_dt
    DCDC_HVIL_MCU_St
      data DCDC_HVIL_MCU_St: type=DCDC_HVIL_MCU_St_dt
    DCDC_HVIL_PTC_St
      data DCDC_HVIL_PTC_St: type=DCDC_HVIL_PTC_St_dt
    DCDC_HVIL_PTCR_St
      data DCDC_HVIL_PTCR_St: type=DCDC_HVIL_PTCR_St_dt
    DCDC_InpWtrTemp
      data DCDC_InpWtrTemp: type=DCDC_InpWtrTemp_dt
    DCDC_IptCurrt
      data DCDC_IptCurrt: type=DCDC_IptCurrt_dt
    DCDC_IptVolt
      data DCDC_IptVolt: type=DCDC_IptVolt_dt
    DCDC_LoopOut
      data DCDC_LoopOut: type=DCDC_LoopOut_dt
    DCDC_LvSidePwr
      data DCDC_LvSidePwr: type=DCDC_LvSidePwr_dt
    DCDC_MaxOptPwr
      data DCDC_MaxOptPwr: type=DCDC_MaxOptPwr_dt
    DCDC_McuInterLockVolt
      data DCDC_McuInterLockVolt: type=DCDC_McuInterLockVolt_dt
    DCDC_NoLoadCurrtFlag
      data DCDC_NoLoadCurrtFlag: type=DCDC_NoLoadCurrtFlag_dt
    DCDC_OperSt
      data DCDC_OperSt: type=DCDC_OperSt_dt
    DCDC_OptCurrt
      data DCDC_OptCurrt: type=DCDC_OptCurrt_dt
    DCDC_OptVolt
      data DCDC_OptVolt: type=DCDC_OptVolt_dt
    DCDC_Oring_APS_Temp
      data DCDC_Oring_APS_Temp: type=DCDC_Oring_APS_Temp_dt
    DCDC_OutWtrTemp
      data DCDC_OutWtrTemp: type=DCDC_OutWtrTemp_dt
    DCDC_OverTemp
      data DCDC_OverTemp: type=DCDC_OverTemp_dt
    DCDC_PeakPwrTi
      data DCDC_PeakPwrTi: type=DCDC_PeakPwrTi_dt
    DCDC_PNGSt
      data DCDC_PNGSt: type=DCDC_PNGSt_dt
    DCDC_PtcInterLockVolt
      data DCDC_PtcInterLockVolt: type=DCDC_PtcInterLockVolt_dt
    DCDC_SwMajorVersion
      data DCDC_SwMajorVersion: type=DCDC_SwMajorVersion_dt
    DCDC_SwMinorVersion
      data DCDC_SwMinorVersion: type=DCDC_SwMinorVersion_dt
    DCDC_SwPatchVersion
      data DCDC_SwPatchVersion: type=DCDC_SwPatchVersion_dt
    DCDC_SwVersionDay
      data DCDC_SwVersionDay: type=DCDC_SwVersionDay_dt
    DCDC_SwVersionMonth
      data DCDC_SwVersionMonth: type=DCDC_SwVersionMonth_dt
    DCDC_SwVersionYear
      data DCDC_SwVersionYear: type=DCDC_SwVersionYear_dt
    OBC_ACInpFrq
      data OBC_ACInpFrq: type=OBC_ACInpFrq_dt
    OBC_AcIptSts
      data OBC_AcIptSts: type=OBC_AcIptSts_dt
    OBC_AcIptType
      data OBC_AcIptType: type=OBC_AcIptType_dt
    OBC_ACL1Currt
      data OBC_ACL1Currt: type=OBC_ACL1Currt_dt
    OBC_ACL1Volt
      data OBC_ACL1Volt: type=OBC_ACL1Volt_dt
    OBC_ACL2Currt
      data OBC_ACL2Currt: type=OBC_ACL2Currt_dt
    OBC_ACL2Volt
      data OBC_ACL2Volt: type=OBC_ACL2Volt_dt
    OBC_ACL3Currt
      data OBC_ACL3Currt: type=OBC_ACL3Currt_dt
    OBC_ACL3Volt
      data OBC_ACL3Volt: type=OBC_ACL3Volt_dt
    OBC_AcLineImpedance
      data OBC_AcLineImpedance: type=OBC_AcLineImpedance_dt
    OBC_ACPileMaxCurrt
      data OBC_ACPileMaxCurrt: type=OBC_ACPileMaxCurrt_dt
    OBC_ACPwr
      data OBC_ACPwr: type=OBC_ACPwr_dt
    OBC_BusCapacity
      data OBC_BusCapacity: type=OBC_BusCapacity_dt
    OBC_CCRes
      data OBC_CCRes: type=OBC_CCRes_dt
    OBC_ChrgCablePermitCurrt
      data OBC_ChrgCablePermitCurrt: type=OBC_ChrgCablePermitCurrt_dt
    OBC_ChrgDischrgStep
      data OBC_ChrgDischrgStep: type=OBC_ChrgDischrgStep_dt
    OBC_ChrgEndNum
      data OBC_ChrgEndNum: type=OBC_ChrgEndNum_dt
    OBC_ChrgGunCCSts
      data OBC_ChrgGunCCSts: type=OBC_ChrgGunCCSts_dt
    OBC_ChrgOptMaxCurrt
      data OBC_ChrgOptMaxCurrt: type=OBC_ChrgOptMaxCurrt_dt
    OBC_ChrgOptMaxPwr
      data OBC_ChrgOptMaxPwr: type=OBC_ChrgOptMaxPwr_dt
    OBC_ChrgOptMaxVolt
      data OBC_ChrgOptMaxVolt: type=OBC_ChrgOptMaxVolt_dt
    OBC_ChrgOptMinVolt
      data OBC_ChrgOptMinVolt: type=OBC_ChrgOptMinVolt_dt
    OBC_CopntTemp
      data OBC_CopntTemp: type=OBC_CopntTemp_dt
    OBC_CPDuty
      data OBC_CPDuty: type=OBC_CPDuty_dt
    OBC_CPFreqSts
      data OBC_CPFreqSts: type=OBC_CPFreqSts_dt
    OBC_CPFrq
      data OBC_CPFrq: type=OBC_CPFrq_dt
    OBC_CPOutpDuty
      data OBC_CPOutpDuty: type=OBC_CPOutpDuty_dt
    OBC_CPOutpVolt
      data OBC_CPOutpVolt: type=OBC_CPOutpVolt_dt
    OBC_CPSts
      data OBC_CPSts: type=OBC_CPSts_dt
    OBC_CPValidSt
      data OBC_CPValidSt: type=OBC_CPValidSt_dt
    OBC_CPVolt
      data OBC_CPVolt: type=OBC_CPVolt_dt
    OBC_DCChrgMod_LimCurrt
      data OBC_DCChrgMod_LimCurrt: type=OBC_DCChrgMod_LimCurrt_dt
    OBC_DCCurrt
      data OBC_DCCurrt: type=OBC_DCCurrt_dt
    OBC_DchaEndNum
      data OBC_DchaEndNum: type=OBC_DchaEndNum_dt
    OBC_DCVolt
      data OBC_DCVolt: type=OBC_DCVolt_dt
    OBC_DeratFlag
      data OBC_DeratFlag: type=OBC_DeratFlag_dt
    OBC_DeratReason1
      data OBC_DeratReason1: type=OBC_DeratReason1_dt
    OBC_DeratReason10
      data OBC_DeratReason10: type=OBC_DeratReason10_dt
    OBC_DeratReason11
      data OBC_DeratReason11: type=OBC_DeratReason11_dt
    OBC_DeratReason12
      data OBC_DeratReason12: type=OBC_DeratReason12_dt
    OBC_DeratReason13
      data OBC_DeratReason13: type=OBC_DeratReason13_dt
    OBC_DeratReason14
      data OBC_DeratReason14: type=OBC_DeratReason14_dt
    OBC_DeratReason15
      data OBC_DeratReason15: type=OBC_DeratReason15_dt
    OBC_DeratReason16
      data OBC_DeratReason16: type=OBC_DeratReason16_dt
    OBC_DeratReason17
      data OBC_DeratReason17: type=OBC_DeratReason17_dt
    OBC_DeratReason18
      data OBC_DeratReason18: type=OBC_DeratReason18_dt
    OBC_DeratReason19
      data OBC_DeratReason19: type=OBC_DeratReason19_dt
    OBC_DeratReason2
      data OBC_DeratReason2: type=OBC_DeratReason2_dt
    OBC_DeratReason20
      data OBC_DeratReason20: type=OBC_DeratReason20_dt
    OBC_DeratReason21
      data OBC_DeratReason21: type=OBC_DeratReason21_dt
    OBC_DeratReason22
      data OBC_DeratReason22: type=OBC_DeratReason22_dt
    OBC_DeratReason23
      data OBC_DeratReason23: type=OBC_DeratReason23_dt
    OBC_DeratReason24
      data OBC_DeratReason24: type=OBC_DeratReason24_dt
    OBC_DeratReason3
      data OBC_DeratReason3: type=OBC_DeratReason3_dt
    OBC_DeratReason4
      data OBC_DeratReason4: type=OBC_DeratReason4_dt
    OBC_DeratReason5
      data OBC_DeratReason5: type=OBC_DeratReason5_dt
    OBC_DeratReason6
      data OBC_DeratReason6: type=OBC_DeratReason6_dt
    OBC_DeratReason7
      data OBC_DeratReason7: type=OBC_DeratReason7_dt
    OBC_DeratReason8
      data OBC_DeratReason8: type=OBC_DeratReason8_dt
    OBC_DeratReason9
      data OBC_DeratReason9: type=OBC_DeratReason9_dt
    OBC_DischrgLoadForm
      data OBC_DischrgLoadForm: type=OBC_DischrgLoadForm_dt
    OBC_DischrgOptMaxPwr
      data OBC_DischrgOptMaxPwr: type=OBC_DischrgOptMaxPwr_dt
    OBC_DisWorkMode
      data OBC_DisWorkMode: type=OBC_DisWorkMode_dt
    OBC_EnergyConvrtDir
      data OBC_EnergyConvrtDir: type=OBC_EnergyConvrtDir_dt
    OBC_FastChargeRelayNegSts
      data OBC_FastChargeRelayNegSts: type=OBC_FastChargeRelayNegSts_dt
    OBC_FastChargeRelayPosSts
      data OBC_FastChargeRelayPosSts: type=OBC_FastChargeRelayPosSts_dt
    OBC_FastChrgRelayNeg_Extd_U
      data OBC_FastChrgRelayNeg_Extd_U: type=OBC_FastChrgRelayNeg_Extd_U_dt
    OBC_FastChrgRelayPos_Extd_U
      data OBC_FastChrgRelayPos_Extd_U: type=OBC_FastChrgRelayPos_Extd_U_dt
    OBC_FaultLevel
      data OBC_FaultLevel: type=OBC_FaultLevel_dt
    OBC_FaultLightReq
      data OBC_FaultLightReq: type=OBC_FaultLightReq_dt
    OBC_HVIL_AC_St
      data OBC_HVIL_AC_St: type=OBC_HVIL_AC_St_dt
    OBC_HVIL_DC_St
      data OBC_HVIL_DC_St: type=OBC_HVIL_DC_St_dt
    OBC_InsulationR
      data OBC_InsulationR: type=OBC_InsulationR_dt
    OBC_Ithd
      data OBC_Ithd: type=OBC_Ithd_dt
    OBC_OperSt
      data OBC_OperSt: type=OBC_OperSt_dt
    OBC_RatedPwrLevel
      data OBC_RatedPwrLevel: type=OBC_RatedPwrLevel_dt
    OBC_RBCurrt
      data OBC_RBCurrt: type=OBC_RBCurrt_dt
    OBC_RBMainK1Sts
      data OBC_RBMainK1Sts: type=OBC_RBMainK1Sts_dt
    OBC_RBMainK2Sts
      data OBC_RBMainK2Sts: type=OBC_RBMainK2Sts_dt
    OBC_RBMainK3Sts
      data OBC_RBMainK3Sts: type=OBC_RBMainK3Sts_dt
    OBC_RBMainK4Sts
      data OBC_RBMainK4Sts: type=OBC_RBMainK4Sts_dt
    OBC_S1Sts
      data OBC_S1Sts: type=OBC_S1Sts_dt
    OBC_S2Sts
      data OBC_S2Sts: type=OBC_S2Sts_dt
    OBC_S4Sts
      data OBC_S4Sts: type=OBC_S4Sts_dt
    OBC_SwMajorVersion
      data OBC_SwMajorVersion: type=OBC_SwMajorVersion_dt
    OBC_SwMinorVersion
      data OBC_SwMinorVersion: type=OBC_SwMinorVersion_dt
    OBC_SwPatchVersion
      data OBC_SwPatchVersion: type=OBC_SwPatchVersion_dt
    OBC_SwVersionDay
      data OBC_SwVersionDay: type=OBC_SwVersionDay_dt
    OBC_SwVersionMonth
      data OBC_SwVersionMonth: type=OBC_SwVersionMonth_dt
    OBC_SwVersionYear
      data OBC_SwVersionYear: type=OBC_SwVersionYear_dt
    OBC_Uthd
      data OBC_Uthd: type=OBC_Uthd_dt
    OBC_WorkMode
      data OBC_WorkMode: type=OBC_WorkMode_dt
    BMS_ActvHvOnReq
      data BMS_ActvHvOnReq: type=BMS_ActvHvOnReq_dt
    BMS_BattVolt_U7
      data BMS_BattVolt_U7: type=BMS_BattVolt_U7_dt
    BMS_ChargeInfo_Checksum
      data BMS_ChargeInfo_Checksum: type=BMS_ChargeInfo_Checksum_dt
    BMS_ChargeInfo_Counter
      data BMS_ChargeInfo_Counter: type=BMS_ChargeInfo_Counter_dt
    BMS_DCChrgConnectSt
      data BMS_DCChrgConnectSt: type=BMS_DCChrgConnectSt_dt
    BMS_MainNegSt
      data BMS_MainNegSt: type=BMS_MainNegSt_dt
    BMS_MainPosSt
      data BMS_MainPosSt: type=BMS_MainPosSt_dt
    BMS_MainPreChrgSt
      data BMS_MainPreChrgSt: type=BMS_MainPreChrgSt_dt
    BMS_Measure_Checksum
      data BMS_Measure_Checksum: type=BMS_Measure_Checksum_dt
    BMS_Measure_Counter
      data BMS_Measure_Counter: type=BMS_Measure_Counter_dt
    BMS_OBCCurrtReq
      data BMS_OBCCurrtReq: type=BMS_OBCCurrtReq_dt
    BMS_OBCInvACVoltReq
      data BMS_OBCInvACVoltReq: type=BMS_OBCInvACVoltReq_dt
    BMS_OBCInvMaxPermPwr
      data BMS_OBCInvMaxPermPwr: type=BMS_OBCInvMaxPermPwr_dt
    BMS_OBCVoltReq
      data BMS_OBCVoltReq: type=BMS_OBCVoltReq_dt
    BMS_OBCWorkModReq
      data BMS_OBCWorkModReq: type=BMS_OBCWorkModReq_dt
    BMS_OperSt
      data BMS_OperSt: type=BMS_OperSt_dt
    IPB_VehicleSpeed
      data IPB_VehicleSpeed: type=IPB_VehicleSpeed_dt
    IPB_VehicleSpeedValid
      data IPB_VehicleSpeedValid: type=IPB_VehicleSpeedValid_dt
    TBOX_DSTFlag
      data TBOX_DSTFlag: type=TBOX_DSTFlag_dt
    TBOX_TimeDay
      data TBOX_TimeDay: type=TBOX_TimeDay_dt
    TBOX_TimeFlag
      data TBOX_TimeFlag: type=TBOX_TimeFlag_dt
    TBOX_TimeHour
      data TBOX_TimeHour: type=TBOX_TimeHour_dt
    TBOX_TimeMinute
      data TBOX_TimeMinute: type=TBOX_TimeMinute_dt
    TBOX_TimeMonth
      data TBOX_TimeMonth: type=TBOX_TimeMonth_dt
    TBOX_TimeSecond
      data TBOX_TimeSecond: type=TBOX_TimeSecond_dt
    TBOX_TimeYear
      data TBOX_TimeYear: type=TBOX_TimeYear_dt
    TBOX_TimeZone
      data TBOX_TimeZone: type=TBOX_TimeZone_dt
    TBOX_TimeZoneMinute
      data TBOX_TimeZoneMinute: type=TBOX_TimeZoneMinute_dt
    TBOX_TimeZoneNum
      data TBOX_TimeZoneNum: type=TBOX_TimeZoneNum_dt
    VDC_ActGearSt
      data VDC_ActGearSt: type=VDC_ActGearSt_dt
    VDC_BMSDchaMaxPwr
      data VDC_BMSDchaMaxPwr: type=VDC_BMSDchaMaxPwr_dt
    VDC_DCDCEnableCmd
      data VDC_DCDCEnableCmd: type=VDC_DCDCEnableCmd_dt
    VDC_DCDCMaxCurrtAlld
      data VDC_DCDCMaxCurrtAlld: type=VDC_DCDCMaxCurrtAlld_dt
    VDC_DCDCSetVolt
      data VDC_DCDCSetVolt: type=VDC_DCDCSetVolt_dt
    VDC_HVCtrl_Checksum
      data VDC_HVCtrl_Checksum: type=VDC_HVCtrl_Checksum_dt
    VDC_HVCtrl_Counter
      data VDC_HVCtrl_Counter: type=VDC_HVCtrl_Counter_dt
    VDC_OBCACCurrtMaxPerm
      data VDC_OBCACCurrtMaxPerm: type=VDC_OBCACCurrtMaxPerm_dt
    VDC_RBAllwdSts
      data VDC_RBAllwdSts: type=VDC_RBAllwdSts_dt
    VDC_RBDCACVoltReq
      data VDC_RBDCACVoltReq: type=VDC_RBDCACVoltReq_dt
    VDC_RBEnableSt
      data VDC_RBEnableSt: type=VDC_RBEnableSt_dt
    VDC_RBMainK1K2Ctrl
      data VDC_RBMainK1K2Ctrl: type=VDC_RBMainK1K2Ctrl_dt
    VDC_RBMainK3K4Ctrl
      data VDC_RBMainK3K4Ctrl: type=VDC_RBMainK3K4Ctrl_dt
    VDC_RBOBCWorkModReq
      data VDC_RBOBCWorkModReq: type=VDC_RBOBCWorkModReq_dt
    VDC_SysState_Checksum
      data VDC_SysState_Checksum: type=VDC_SysState_Checksum_dt
    VDC_SysState_Counter
      data VDC_SysState_Counter: type=VDC_SysState_Counter_dt
    VDC_TotalRang_VV01
      data VDC_TotalRang_VV01: type=VDC_TotalRang_VV01_dt
    VDC_VehState_Checksum
      data VDC_VehState_Checksum: type=VDC_VehState_Checksum_dt
    VDC_VehState_Counter
      data VDC_VehState_Counter: type=VDC_VehState_Counter_dt
    VIU_CarMode
      data VIU_CarMode: type=VIU_CarMode_dt
    VIU_Info_Checksum_VV01
      data VIU_Info_Checksum_VV01: type=VIU_Info_Checksum_VV01_dt
    VIU_Info_Counter
      data VIU_Info_Counter: type=VIU_Info_Counter_dt
    VIU_PowerMode
      data VIU_PowerMode: type=VIU_PowerMode_dt
    VIU_Route_EP_Checksum
      data VIU_Route_EP_Checksum: type=VIU_Route_EP_Checksum_dt
    VIU_Route_EP_Counter
      data VIU_Route_EP_Counter: type=VIU_Route_EP_Counter_dt
    VIU_UsageMode
      data VIU_UsageMode: type=VIU_UsageMode_dt
